VERSION ""

NS_ :

BS_:

BU_: AHLM ASBS CBC DIAGNOST DPDM DTCM ECM EHPS ESC ESL ESM ETM GPF HCP IC IRCM OCM ORC PTS RF_HUB SCCM SGW TBM TCM TPM

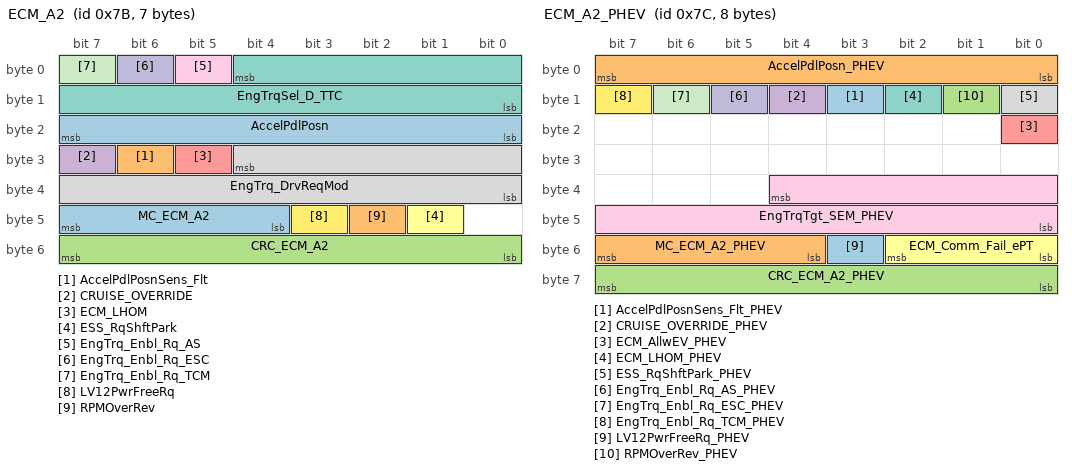
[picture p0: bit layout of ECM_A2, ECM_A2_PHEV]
BO_ 123 ECM_A2: 7 ECM
 SG_ AccelPdlPosn : 16|8@1+ (0.4,0) [0|100] "%"  CBC,DTCM,ESC,ETM,SGW,TBM,TCM
 SG_ AccelPdlPosnSens_Flt : 30|1@1+ (1,0) [0|0] ""  CBC,DTCM,ESC,IRCM,SGW,TCM
 SG_ CRC_ECM_A2 : 48|8@1+ (1,0) [0|0] ""  ESC,IRCM,SGW,TCM
 SG_ CRUISE_OVERRIDE : 31|1@1+ (1,0) [0|0] ""  ESC,IRCM,ORC,SGW,TCM
 SG_ ECM_LHOM : 29|1@1+ (1,0) [0|0] ""  IRCM,SGW,TCM
 SG_ ESS_RqShftPark : 41|1@1+ (1,0) [0|0] ""  ORC,SGW
 SG_ EngTrqSel_D_TTC : 4|13@0+ (0.25,-500) [-500|1547.5] "Nm"  DTCM,ESC,IRCM,ORC,SGW,TCM
 SG_ EngTrq_DrvReqMod : 28|13@0+ (0.25,-500) [-500|1547.5] "Nm"  DTCM,ESC,SGW,TCM
 SG_ EngTrq_Enbl_Rq_AS : 5|1@1+ (1,0) [0|0] ""  ESC,IRCM,SGW
 SG_ EngTrq_Enbl_Rq_ESC : 6|1@1+ (1,0) [0|0] ""  ESC,IRCM,SGW
 SG_ EngTrq_Enbl_Rq_TCM : 7|1@1+ (1,0) [0|0] ""  ORC,SGW,TCM
 SG_ LV12PwrFreeRq : 43|1@1+ (1,0) [0|0] ""  ESC,SGW,TCM
 SG_ MC_ECM_A2 : 44|4@1+ (1,0) [0|15] ""  ESC,IRCM,SGW,TCM
 SG_ RPMOverRev : 42|1@1+ (1,0) [0|0] ""  IRCM,SGW

BO_ 124 ECM_A2_PHEV: 8 ECM
 SG_ AccelPdlPosnSens_Flt_PHEV : 11|1@1+ (1,0) [0|0] ""  CBC,DTCM,ESC,HCP,IRCM,SGW,TCM
 SG_ AccelPdlPosn_PHEV : 0|8@1+ (0.4,0) [0|100] "%"  CBC,DTCM,ESC,IRCM,SGW,TCM
 SG_ CRC_ECM_A2_PHEV : 56|8@1+ (1,0) [0|0] ""  DTCM,ESC,HCP,IRCM,SGW,TCM
 SG_ CRUISE_OVERRIDE_PHEV : 12|1@1+ (1,0) [0|0] ""  ESC,IRCM,ORC,SGW,TCM
 SG_ ECM_AllwEV_PHEV : 16|1@1+ (1,0) [0|0] ""  HCP,SGW
 SG_ ECM_Comm_Fail_ePT : 48|3@1+ (1,0) [0|0] ""  HCP,SGW,TCM
 SG_ ECM_LHOM_PHEV : 10|1@1+ (1,0) [0|0] ""  HCP,IRCM,SGW,TCM
 SG_ ESS_RqShftPark_PHEV : 8|1@1+ (1,0) [0|0] ""  ORC,SGW
 SG_ EngTrqTgt_SEM_PHEV : 36|13@0+ (0.25,-500) [-500|1547.5] "Nm"  HCP,SGW
 SG_ EngTrq_Enbl_Rq_AS_PHEV : 13|1@1+ (1,0) [0|0] ""  ESC,IRCM,SGW
 SG_ EngTrq_Enbl_Rq_ESC_PHEV : 14|1@1+ (1,0) [0|0] ""  ESC,IRCM,SGW
 SG_ EngTrq_Enbl_Rq_TCM_PHEV : 15|1@1+ (1,0) [0|0] ""  HCP,ORC,SGW
 SG_ LV12PwrFreeRq_PHEV : 51|1@1+ (1,0) [0|0] ""  ESC,HCP,SGW
 SG_ MC_ECM_A2_PHEV : 52|4@1+ (1,0) [0|15] ""  DTCM,ESC,HCP,IRCM,SGW,TCM
 SG_ RPMOverRev_PHEV : 9|1@1+ (1,0) [0|0] ""  HCP,IRCM,SGW

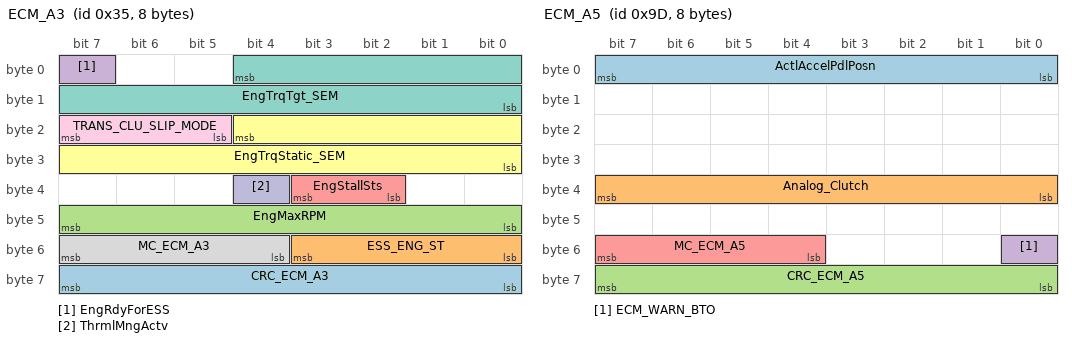
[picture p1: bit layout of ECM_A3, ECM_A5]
BO_ 53 ECM_A3: 8 ECM
 SG_ CRC_ECM_A3 : 56|8@1+ (1,0) [0|0] ""  IRCM,PTS,RF_HUB,SGW,TCM
 SG_ ESS_ENG_ST : 48|4@1+ (1,0) [0|0] ""  CBC,DTCM,EHPS,ESC,ETM,IC,IRCM,ORC,PTS,SGW,TBM,TCM
 SG_ EngMaxRPM : 40|8@1+ (50,0) [0|12700] "rpm"  SGW,TCM
 SG_ EngRdyForESS : 7|1@1+ (1,0) [0|0] ""  SGW,TCM
 SG_ EngStallSts : 34|2@1+ (1,0) [0|0] ""  RF_HUB,SGW
 SG_ EngTrqStatic_SEM : 20|13@0+ (0.25,-500) [-500|1547.5] "Nm"  SGW,TCM
 SG_ EngTrqTgt_SEM : 4|13@0+ (0.25,-500) [-500|1547.5] "Nm"  HCP,SGW,TCM
 SG_ MC_ECM_A3 : 52|4@1+ (1,0) [0|15] ""  EHPS,IRCM,PTS,RF_HUB,SGW,TCM
 SG_ TRANS_CLU_SLIP_MODE : 21|3@1+ (1,0) [0|0] ""  SGW,TCM
 SG_ ThrmlMngActv : 36|1@1+ (1,0) [0|0] ""  IRCM,SGW,TCM

BO_ 976 ECM_A4: 8 ECM
 SG_ KNK_MG_TRIGGER : 29|2@1+ (1,0) [0|0] ""  IC,SGW
 SG_ PF_WARN_MSG : 24|3@1+ (1,0) [0|0] ""  IC,SGW

BO_ 157 ECM_A5: 8 ECM
 SG_ ActlAccelPdlPosn : 0|8@1+ (0.4,0) [0|100] "%"  ESC,ETM,IRCM,ORC,SGW,TBM
 SG_ Analog_Clutch : 32|8@1+ (0.4,0) [0|100] "%"  SGW
 SG_ CRC_ECM_A5 : 56|8@1+ (1,0) [0|0] ""  ESC,IRCM,SGW
 SG_ ECM_WARN_BTO : 48|1@1+ (1,0) [0|0] ""  IC,SGW
 SG_ MC_ECM_A5 : 52|4@1+ (1,0) [0|15] ""  ESC,IRCM,SGW

BO_ 819 ECM_A6: 8 ECM
 SG_ ExhaustSwStat : 56|2@1+ (1,0) [0|0] ""  CBC,IC,SGW

BO_ 864 ECM_APPL1: 8 ECM
 SG_ ECM_APPL1 : 7|64@0+ (1,0) [0|0] ""  DIAGNOST,SGW

BO_ 850 ECM_APPL2: 8 DIAGNOST
 SG_ ECM_APPL2 : 7|64@0+ (1,0) [0|0] ""  ECM

BO_ 880 ECM_APPL3: 8 ECM
 SG_ ECM_APPL3 : 7|64@0+ (1,0) [0|0] ""  DIAGNOST,SGW

BO_ 896 ECM_APPL4: 8 ECM
 SG_ ECM_APPL4 : 7|64@0+ (1,0) [0|0] ""  DIAGNOST,SGW

BO_ 912 ECM_APPL5: 8 ECM
 SG_ ECM_APPL5 : 7|64@0+ (1,0) [0|0] ""  DIAGNOST,SGW

BO_ 928 ECM_APPL6: 8 ECM
 SG_ ECM_APPL6 : 7|64@0+ (1,0) [0|0] ""  DIAGNOST,SGW

BO_ 936 ECM_APPL7: 8 ECM
 SG_ ECM_APPL7 : 7|64@0+ (1,0) [0|0] ""  DIAGNOST,SGW

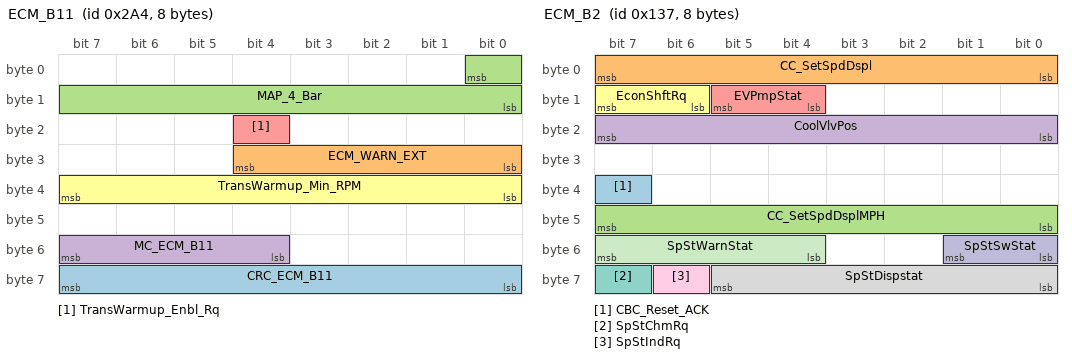
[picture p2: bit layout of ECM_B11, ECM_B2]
BO_ 676 ECM_B11: 8 ECM
 SG_ CRC_ECM_B11 : 56|8@1+ (1,0) [0|0] ""  SGW,TCM
 SG_ ECM_WARN_EXT : 24|5@1+ (1,0) [0|0] ""  ETM,IC,SGW,TBM
 SG_ MAP_4_Bar : 0|9@0+ (0.8,0) [0|408] "kPa"  ETM,ORC,SGW,TBM
 SG_ MC_ECM_B11 : 52|4@1+ (1,0) [0|15] ""  SGW,TCM
 SG_ TransWarmup_Enbl_Rq : 20|1@1+ (1,0) [0|0] ""  SGW,TCM
 SG_ TransWarmup_Min_RPM : 32|8@1+ (25,0) [0|6350] "rpm"  SGW,TCM

BO_ 311 ECM_B2: 8 ECM
 SG_ CBC_Reset_ACK : 39|1@1+ (1,0) [0|0] ""  CBC,SGW
 SG_ CC_SetSpdDspl : 0|8@1+ (1,0) [0|250] "km/h"  ETM,IC,SGW,TBM
 SG_ CC_SetSpdDsplMPH : 40|8@1+ (1,0) [0|254] "mph"  ETM,IC,SGW,TBM
 SG_ CoolVlvPos : 16|8@1+ (0.39374,0) [0.39374|99.61622] "%"  CBC,SGW
 SG_ EVPmpStat : 12|2@1+ (1,0) [0|0] ""  ESC,SGW
 SG_ EconShftRq : 14|2@1+ (1,0) [0|0] ""  IC,SGW
 SG_ SpStChmRq : 63|1@1+ (1,0) [0|0] ""  IC,SGW
 SG_ SpStDispstat : 56|6@1+ (1,0) [0|0] ""  ETM,IC,ORC,SGW,TBM
 SG_ SpStIndRq : 62|1@1+ (1,0) [0|0] ""  IC,SGW
 SG_ SpStSwStat : 48|2@1+ (1,0) [0|0] ""  CBC,ETM,ORC,SGW,TBM
 SG_ SpStWarnStat : 52|4@1+ (1,0) [0|0] ""  ETM,IC,ORC,SGW,TBM

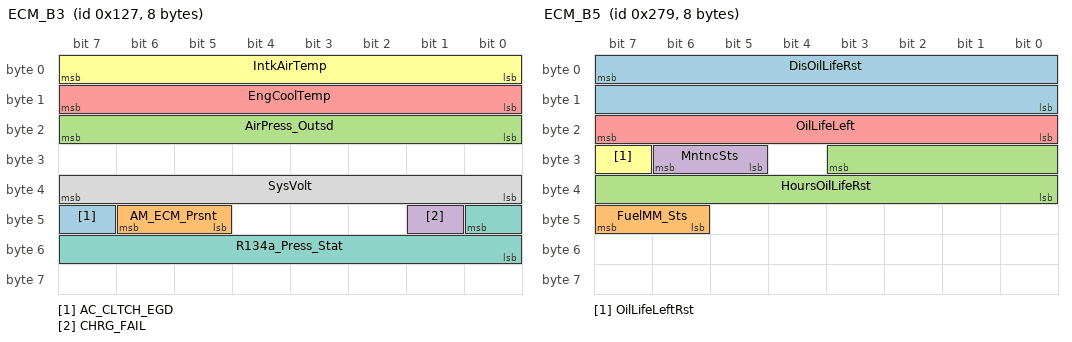
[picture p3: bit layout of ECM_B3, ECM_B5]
BO_ 295 ECM_B3: 8 ECM
 SG_ AC_CLTCH_EGD : 47|1@1+ (1,0) [0|0] ""  CBC,SGW,TCM
 SG_ AM_ECM_Prsnt : 45|2@1+ (1,0) [0|0] ""  CBC,SGW
 SG_ AirPress_Outsd : 16|8@1+ (1,0) [0|254] "kPaA"  ESC,IRCM,SGW,TCM,TPM
 SG_ CHRG_FAIL : 41|1@1+ (1,0) [0|0] ""  ETM,IC,SGW,TBM
 SG_ EngCoolTemp : 8|8@1+ (1,-40) [-40|214] "°C"  CBC,DTCM,ESC,ETM,IC,SGW,TBM,TCM
 SG_ IntkAirTemp : 0|8@1+ (1,-40) [-40|214] "°C"  ECM,SGW,TCM
 SG_ R134a_Press_Stat : 40|9@0+ (0.1,0) [0|40] "bar"  CBC,SGW
 SG_ SysVolt : 32|8@1+ (0.0618,0) [0|15.6972] "Volts"  HCP,SGW

BO_ 633 ECM_B5: 8 ECM
 SG_ DisOilLifeRst : 7|16@0+ (1,0) [0|65534] "km"  CBC,IC,SGW
 SG_ FuelMM_Sts : 46|2@1+ (1,0) [0|0] ""  IC,SGW
 SG_ HoursOilLifeRst : 27|12@0+ (1,0) [0|4000] "Hours"  CBC,SGW
 SG_ MntncSts : 29|2@1+ (1,0) [0|0] ""  ETM,IC,SGW,TBM
 SG_ OilLifeLeft : 16|8@1+ (1,0) [0|100] "%"  ETM,IC,SGW,TBM
 SG_ OilLifeLeftRst : 31|1@1+ (1,0) [0|0] ""  ETM,IC,SGW,TBM

BO_ 323 ECM_B7: 8 ECM
 SG_ DrvAway_Alert : 7|1@1+ (1,0) [0|0] ""  IC,ORC,SGW
 SG_ DrvAway_Inhibit : 15|1@1+ (1,0) [0|0] ""  IC,PTS,SGW

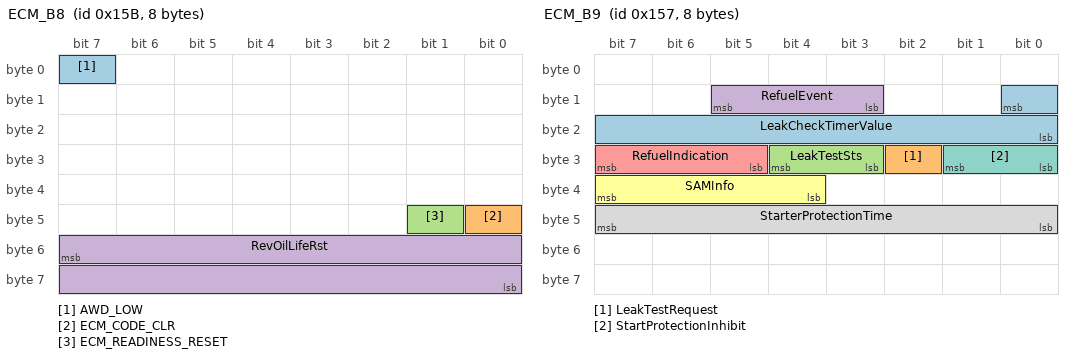
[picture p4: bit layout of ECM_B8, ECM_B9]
BO_ 347 ECM_B8: 8 ECM
 SG_ AWD_LOW : 7|1@1+ (1,0) [0|0] ""  HCP,SGW
 SG_ ECM_CODE_CLR : 40|1@1+ (1,0) [0|0] ""  ESC,HCP,SGW,TCM
 SG_ ECM_READINESS_RESET : 41|1@1+ (1,0) [0|0] ""  ESC,HCP,SGW,TCM
 SG_ RevOilLifeRst : 55|16@0+ (1000,0) [0|65534000] "Rev's"  CBC,SGW

BO_ 343 ECM_B9: 8 ECM
 SG_ LeakCheckTimerValue : 8|9@0+ (1,0) [0|510] "min"  CBC,SGW
 SG_ LeakTestRequest : 26|1@1+ (1,0) [0|0] ""  CBC,SGW
 SG_ LeakTestSts : 27|2@1+ (1,0) [0|0] ""  CBC,ECM,SGW
 SG_ RefuelEvent : 11|3@1+ (1,0) [0|0] ""  CBC,SGW
 SG_ RefuelIndication : 29|3@1+ (1,0) [0|0] ""  IC,SGW
 SG_ SAMInfo : 36|4@1+ (1,0) [0|0] ""  CBC,SGW
 SG_ StartProtectionInhibit : 24|2@1+ (1,0) [0|0] ""  IC,SGW
 SG_ StarterProtectionTime : 40|8@1+ (1,0) [0|254] "sec"  IC,SGW

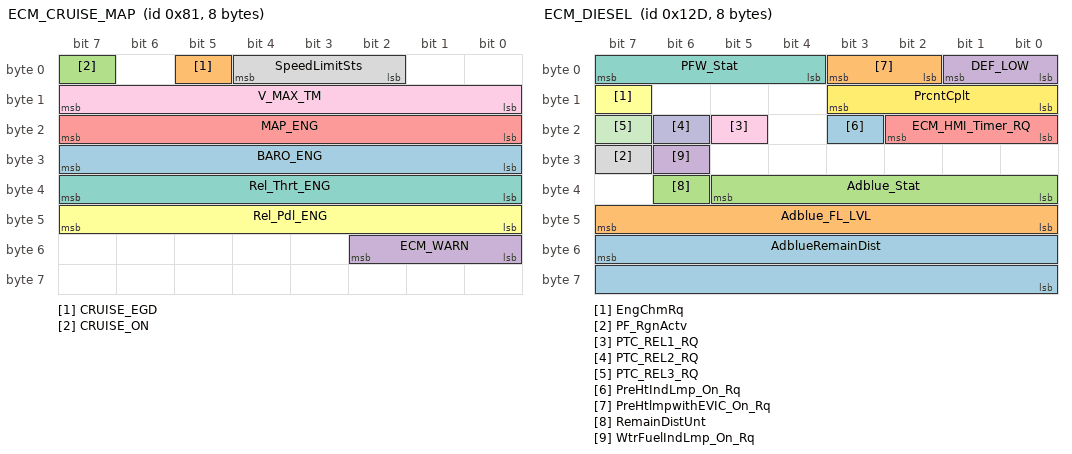
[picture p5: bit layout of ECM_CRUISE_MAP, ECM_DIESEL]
BO_ 129 ECM_CRUISE_MAP: 8 ECM
 SG_ BARO_ENG : 24|8@1+ (1,0) [0|254] "kPaA"  ESC,ETM,SGW,TBM
 SG_ CRUISE_EGD : 5|1@1+ (1,0) [0|0] ""  CBC,ESC,ETM,HCP,IC,ORC,SGW,TBM,TCM
 SG_ CRUISE_ON : 7|1@1+ (1,0) [0|0] ""  CBC,ESC,HCP,IC,ORC,SGW,TCM
 SG_ ECM_WARN : 48|3@1+ (1,0) [0|0] ""  IC,SGW
 SG_ MAP_ENG : 16|8@1+ (0.8,0) [0|203.2] "kPa"  ESC,ETM,SGW,TBM
 SG_ Rel_Pdl_ENG : 40|8@1+ (0.019607843,0) [0|4.98] "Volts"  ESC,ETM,SGW,TBM
 SG_ Rel_Thrt_ENG : 32|8@1+ (0.019607843,0) [0|4.98] "Volts"  ESC,ETM,SGW,TBM
 SG_ SpeedLimitSts : 2|3@1+ (1,0) [0|0] ""  IC,IRCM,ORC,SGW
 SG_ V_MAX_TM : 8|8@1+ (1,0) [0|250] "km/h(mph)"  SGW,TCM

BO_ 301 ECM_DIESEL: 8 ECM
 SG_ AdblueRemainDist : 55|16@0+ (1,0) [0|65534] ""  IC,SGW
 SG_ Adblue_FL_LVL : 40|8@1+ (1,0) [0|100] "%"  ETM,IC,SGW,TBM
 SG_ Adblue_Stat : 32|6@1+ (1,0) [0|0] ""  ETM,IC,SGW,TBM
 SG_ DEF_LOW : 0|2@1+ (1,0) [0|0] ""  ETM,IC,SGW,TBM
 SG_ ECM_HMI_Timer_RQ : 16|3@1+ (1,0) [0|0] ""  IC,SGW
 SG_ EngChmRq : 15|1@1+ (1,0) [0|0] ""  IC,SGW
 SG_ PFW_Stat : 4|4@1+ (1,0) [0|0] ""  ETM,IC,SGW,TBM
 SG_ PF_RgnActv : 31|1@1+ (1,0) [0|0] ""  SGW,TCM
 SG_ PTC_REL1_RQ : 21|1@1+ (1,0) [0|0] ""  CBC,SGW
 SG_ PTC_REL2_RQ : 22|1@1+ (1,0) [0|0] ""  CBC,SGW
 SG_ PTC_REL3_RQ : 23|1@1+ (1,0) [0|0] ""  CBC,SGW
 SG_ PrcntCplt : 8|4@1+ (10,0) [0|100] "%"  ETM,IC,SGW,TBM
 SG_ PreHtIndLmp_On_Rq : 19|1@1+ (1,0) [0|0] ""  CBC,ETM,SGW,TBM
 SG_ PreHtlmpwithEVIC_On_Rq : 2|2@1+ (1,0) [0|0] ""  IC,SGW
 SG_ RemainDistUnt : 38|1@1+ (1,0) [0|0] ""  IC,SGW
 SG_ WtrFuelIndLmp_On_Rq : 30|1@1+ (1,0) [0|0] ""  ETM,IC,SGW,TBM

BO_ 337 ECM_DIESEL2: 8 ECM
 SG_ TrboBstPress : 48|8@1+ (1,0) [0|250] "kPaG"  SGW

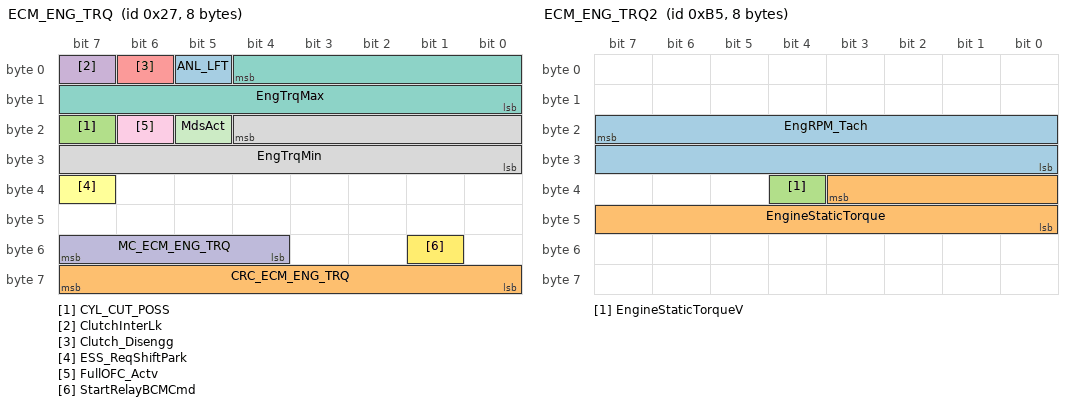
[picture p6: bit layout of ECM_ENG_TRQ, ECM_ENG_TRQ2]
BO_ 39 ECM_ENG_TRQ: 8 ECM
 SG_ ANL_LFT : 5|1@1+ (1,0) [0|0] ""  CBC,SGW
 SG_ CRC_ECM_ENG_TRQ : 56|8@1+ (1,0) [0|0] ""  ESC,IRCM,SGW
 SG_ CYL_CUT_POSS : 23|1@1+ (1,0) [0|0] ""  SGW
 SG_ ClutchInterLk : 7|1@1+ (1,0) [0|0] ""  DTCM,ECM,ESC,ORC,SGW
 SG_ Clutch_Disengg : 6|1@1+ (1,0) [0|0] ""  CBC,ECM,ESC,IRCM,ORC,SGW
 SG_ ESS_ReqShiftPark : 39|1@1+ (1,0) [0|0] ""  SGW,TCM
 SG_ EngTrqMax : 4|13@0+ (0.25,-500) [-500|1547.5] "Nm"  DTCM,ESC,IRCM,SGW,TCM
 SG_ EngTrqMin : 20|13@0+ (0.25,-500) [-500|1547.5] "Nm"  DTCM,ESC,IRCM,SGW
 SG_ FullOFC_Actv : 22|1@1+ (1,0) [0|0] ""  ESC,IRCM,SGW
 SG_ MC_ECM_ENG_TRQ : 52|4@1+ (1,0) [0|15] ""  ESC,IRCM,SGW
 SG_ MdsAct : 21|1@1+ (1,0) [0|0] ""  ETM,SGW,TBM,TCM
 SG_ StartRelayBCMCmd : 49|1@1+ (1,0) [0|0] ""  CBC,SGW

BO_ 181 ECM_ENG_TRQ2: 8 ECM
 SG_ EngRPM_Tach : 23|16@0+ (1,0) [0|65534] "RPM"  IC,SGW
 SG_ EngineStaticTorque : 35|12@0+ (0.32,-300.16) [-300.16|1008] "Nm"  HCP,SGW
 SG_ EngineStaticTorqueV : 36|1@1+ (1,0) [0|0] ""  HCP,SGW

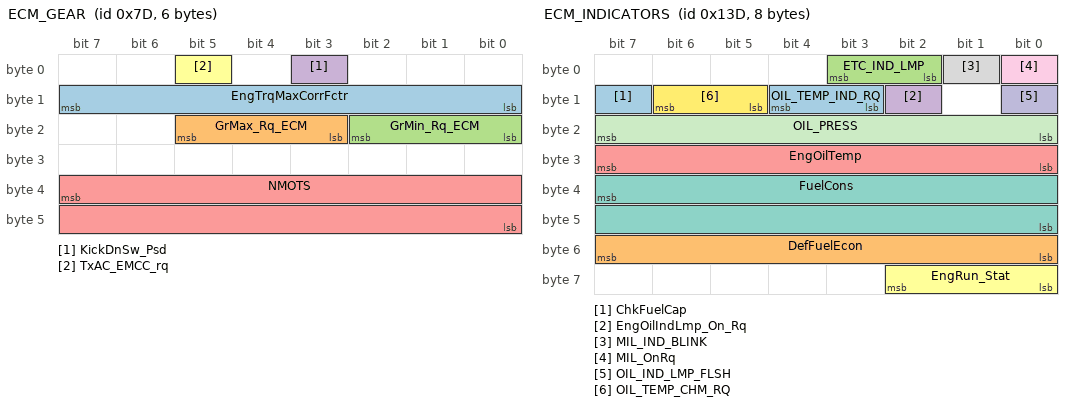
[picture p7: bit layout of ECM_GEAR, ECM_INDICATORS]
BO_ 125 ECM_GEAR: 6 ECM
 SG_ EngTrqMaxCorrFctr : 8|8@1+ (0.0078,0) [0|1.98] "Nm"  SGW,TCM
 SG_ GrMax_Rq_ECM : 19|3@1+ (1,0) [0|0] ""  SGW,TCM
 SG_ GrMin_Rq_ECM : 16|3@1+ (1,0) [0|0] ""  SGW,TCM
 SG_ KickDnSw_Psd : 3|1@1+ (1,0) [0|0] ""  ESC,SGW,TCM
 SG_ NMOTS : 39|16@0+ (1,0) [0|65534] "rpm"  ESC,SGW,TCM
 SG_ TxAC_EMCC_rq : 5|1@1+ (1,0) [0|0] ""  SGW,TCM

BO_ 317 ECM_INDICATORS: 8 ECM
 SG_ ChkFuelCap : 15|1@1+ (1,0) [0|0] ""  ETM,IC,SGW,TBM
 SG_ DefFuelEcon : 48|8@1+ (0.2,0) [0|50] "kmpl"  ETM,IC,SGW,TBM
 SG_ ETC_IND_LMP : 2|2@1+ (1,0) [0|0] ""  CBC,ETM,IC,SGW,TBM
 SG_ EngOilIndLmp_On_Rq : 10|1@1+ (1,0) [0|0] ""  CBC,ETM,IC,SGW,TBM
 SG_ EngOilTemp : 24|8@1+ (1,-40) [-40|160] "°C"  ETM,HCP,IC,SGW,TBM,TCM
 SG_ EngRun_Stat : 56|3@1+ (1,0) [0|0] ""  CBC,DTCM,ESC,HCP,IC,RF_HUB,SGW,TCM
 SG_ FuelCons : 39|16@0+ (0.21668,0) [0|14200] "µl/100ms"  ETM,IC,SGW,TBM
 SG_ MIL_IND_BLINK : 1|1@1+ (1,0) [0|0] ""  CBC,HCP,IC,ORC,SGW
 SG_ MIL_OnRq : 0|1@1+ (1,0) [0|0] ""  CBC,ETM,HCP,IC,ORC,SGW,TBM
 SG_ OIL_IND_LMP_FLSH : 8|1@1+ (1,0) [0|0] ""  ETM,IC,SGW,TBM
 SG_ OIL_PRESS : 16|8@1+ (4,0) [0|1016] "kPaG"  ETM,IC,SGW,TBM
 SG_ OIL_TEMP_CHM_RQ : 13|2@1+ (1,0) [0|0] ""  SGW
 SG_ OIL_TEMP_IND_RQ : 11|2@1+ (1,0) [0|0] ""  ETM,IC,SGW,TBM

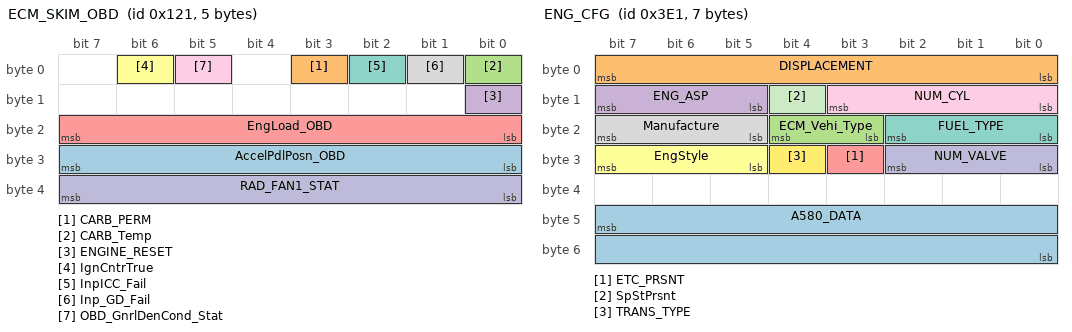
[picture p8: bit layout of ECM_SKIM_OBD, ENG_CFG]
BO_ 289 ECM_SKIM_OBD: 5 ECM
 SG_ AccelPdlPosn_OBD : 24|8@1+ (0.3922,0) [0|100] "%"  ESC,ETM,SGW,TBM,TCM
 SG_ CARB_PERM : 3|1@1+ (1,0) [0|0] ""  SGW,TCM
 SG_ CARB_Temp : 0|1@1+ (1,0) [0|0] ""  SGW,TCM
 SG_ ENGINE_RESET : 8|1@1+ (1,0) [0|0] ""  HCP,SGW
 SG_ EngLoad_OBD : 16|8@1+ (0.3922,0) [0|100] "%"  ESC,ETM,SGW,TBM,TCM
 SG_ IgnCntrTrue : 6|1@1+ (1,0) [0|0] ""  SGW,TCM
 SG_ InpICC_Fail : 2|1@1+ (1,0) [0|0] ""  SGW,TCM
 SG_ Inp_GD_Fail : 1|1@1+ (1,0) [0|0] ""  SGW,TCM
 SG_ OBD_GnrlDenCond_Stat : 5|1@1+ (1,0) [0|0] ""  HCP,SGW,TCM
 SG_ RAD_FAN1_STAT : 32|8@1+ (1,0) [0|100] "%"  ETM,SGW,TBM

BO_ 1449 ECU_APPL_AHLM: 8 AHLM
 SG_ ECU_APPL_AHLM : 7|64@0+ (1,0) [0|0] ""  DIAGNOST,SGW

BO_ 1418 ECU_APPL_ASBS: 8 ASBS
 SG_ ECU_APPL_ASBS : 7|64@0+ (1,0) [0|0] ""  DIAGNOST,SGW

BO_ 1468 ECU_APPL_BSMO: 8 ESC
 SG_ ECU_APPL_BSMO : 7|64@0+ (1,0) [0|0] ""  DIAGNOST,SGW

BO_ 1409 ECU_APPL_CBC: 8 CBC
 SG_ ECU_APPL_CBC : 7|64@0+ (1,0) [0|0] ""  DIAGNOST,SGW

BO_ 1427 ECU_APPL_DASM: 8 IRCM
 SG_ ECU_APPL_DASM : 7|64@0+ (1,0) [0|0] ""  DIAGNOST,SGW

BO_ 1425 ECU_APPL_DPDM: 8 DPDM
 SG_ ECU_APPL_DPDM : 7|64@0+ (1,0) [0|0] ""  DIAGNOST,SGW

BO_ 1419 ECU_APPL_DTCM: 8 DTCM
 SG_ ECU_APPL_DTCM : 7|64@0+ (1,0) [0|0] ""  DIAGNOST,SGW

BO_ 1464 ECU_APPL_ECM: 8 ECM
 SG_ ECU_APPL_ECM : 7|64@0+ (1,0) [0|0] ""  DIAGNOST,SGW

BO_ 1434 ECU_APPL_EPS: 8 EHPS
 SG_ ECU_APPL_EPS : 7|64@0+ (1,0) [0|0] ""  DIAGNOST,SGW

BO_ 1415 ECU_APPL_ESC: 8 ESC
 SG_ ECU_APPL_ESC : 7|64@0+ (1,0) [0|0] ""  DIAGNOST,SGW

BO_ 1416 ECU_APPL_ESL: 8 ESL
 SG_ ECU_APPL_ESL : 7|64@0+ (1,0) [0|0] ""  DIAGNOST,SGW

BO_ 1417 ECU_APPL_ESM: 8 ESM
 SG_ ECU_APPL_ESM : 7|64@0+ (1,0) [0|0] ""  DIAGNOST,SGW

BO_ 1458 ECU_APPL_GPF: 8 GPF
 SG_ ECU_APPL_GPF : 7|64@0+ (1,0) [0|0] ""  DIAGNOST,SGW

BO_ 1466 ECU_APPL_HCP: 8 HCP
 SG_ ECU_APPL_HCP : 7|64@0+ (1,0) [0|0] ""  DIAGNOST,SGW

BO_ 1410 ECU_APPL_IC: 8 IC
 SG_ ECU_APPL_IC : 7|64@0+ (1,0) [0|0] ""  DIAGNOST,SGW

BO_ 1438 ECU_APPL_OCM: 8 OCM
 SG_ ECU_APPL_OCM : 7|64@0+ (1,0) [0|0] ""  DIAGNOST,SGW

BO_ 1412 ECU_APPL_ORC: 8 ORC
 SG_ ECU_APPL_ORC : 7|64@0+ (1,0) [0|0] ""  DIAGNOST,SGW

BO_ 1442 ECU_APPL_PTS: 8 PTS
 SG_ ECU_APPL_PTS : 7|64@0+ (1,0) [0|0] ""  DIAGNOST,SGW

BO_ 1408 ECU_APPL_RF_HUB: 8 RF_HUB
 SG_ ECU_APPL_RF_HUB : 7|64@0+ (1,0) [0|0] ""  DIAGNOST,SGW

BO_ 1443 ECU_APPL_SCCM: 8 SCCM
 SG_ ECU_APPL_SCCM : 7|64@0+ (1,0) [0|0] ""  DIAGNOST,SGW

BO_ 1515 ECU_APPL_TBM: 8 SGW
 SG_ ECU_APPL_TBM : 7|64@0+ (1,0) [0|0] ""  DIAGNOST

BO_ 1465 ECU_APPL_TCM: 8 TCM
 SG_ ECU_APPL_TCM : 7|64@0+ (1,0) [0|0] ""  DIAGNOST,SGW

BO_ 1411 ECU_APPL_TPM: 8 TPM
 SG_ ECU_APPL_TPM : 7|64@0+ (1,0) [0|0] ""  DIAGNOST,SGW

BO_ 993 ENG_CFG: 7 ECM
 SG_ A580_DATA : 47|16@0+ (1,0) [0|0] ""  SGW
 SG_ DISPLACEMENT : 0|8@1+ (0.1,0) [0|25] "liters"  DTCM,ESC,ETM,HCP,IC,IRCM,ORC,SGW,TBM
 SG_ ECM_Vehi_Type : 19|2@1+ (1,0) [0|0] ""  SGW
 SG_ ENG_ASP : 13|3@1+ (1,0) [0|0] ""  ESC,IC,IRCM,SGW
 SG_ ETC_PRSNT : 27|1@1+ (1,0) [0|0] ""  SGW
 SG_ EngStyle : 29|3@1+ (1,0) [0|0] ""  CBC,ESC,SGW
 SG_ FUEL_TYPE : 16|3@1+ (1,0) [0|0] ""  CBC,ESC,ETM,IC,IRCM,SGW,TBM
 SG_ Manufacture : 21|3@1+ (1,0) [0|0] ""  SGW
 SG_ NUM_CYL : 8|4@1+ (1,0) [0|14] "cylinders"  ESC,ETM,IC,IRCM,SGW,TBM
 SG_ NUM_VALVE : 24|3@1+ (1,0) [0|6] "valve-per-cylinder"  IRCM,SGW
 SG_ SpStPrsnt : 12|1@1+ (1,0) [0|0] ""  CBC,EHPS,ESC,IC,IRCM,PTS,SGW
 SG_ TRANS_TYPE : 28|1@1+ (1,0) [0|0] ""  ETM,SGW,TBM

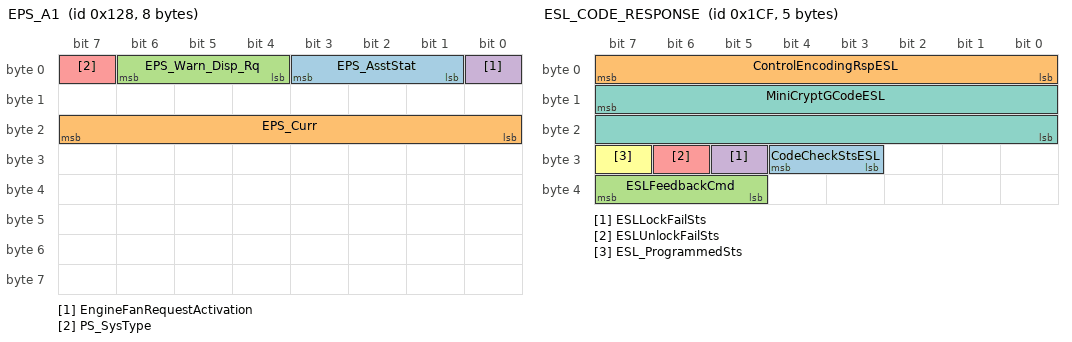
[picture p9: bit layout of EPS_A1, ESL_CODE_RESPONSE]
BO_ 296 EPS_A1: 8 EHPS
 SG_ EPS_AsstStat : 1|3@1+ (1,0) [0|0] ""  ESC,SGW
 SG_ EPS_Curr : 16|8@1+ (1,-50) [-50|204] "Amp"  SGW
 SG_ EPS_Warn_Disp_Rq : 4|3@1+ (1,0) [0|0] ""  ESC,ETM,IC,ORC,SGW,TBM
 SG_ EngineFanRequestActivation : 0|1@1+ (1,0) [0|0] ""  ECM,SGW
 SG_ PS_SysType : 7|1@1+ (1,0) [0|0] ""  CBC,ESC,SGW

BO_ 463 ESL_CODE_RESPONSE: 5 ESL
 SG_ CodeCheckStsESL : 27|2@1+ (1,0) [0|0] ""  CBC,SGW
 SG_ ControlEncodingRspESL : 0|8@1+ (1,0) [0|0] ""  CBC,SGW
 SG_ ESLFeedbackCmd : 37|3@1+ (1,0) [0|0] ""  CBC,SGW
 SG_ ESLLockFailSts : 29|1@1+ (1,0) [0|0] ""  CBC,SGW
 SG_ ESLUnlockFailSts : 30|1@1+ (1,0) [0|0] ""  CBC,SGW
 SG_ ESL_ProgrammedSts : 31|1@1+ (1,0) [0|0] ""  SGW
 SG_ MiniCryptGCodeESL : 15|16@0+ (1,0) [0|0] ""  CBC,SGW

BO_TX_BU_ 850 : DIAGNOST,SGW;
BO_TX_BU_ 1515 : SGW,TBM;
CM_ SG_ 123 AccelPdlPosn "Throttle Pedal Position (Calculated)";
CM_ SG_ 123 AccelPdlPosnSens_Flt "Accelerator pedal position sensor fault";
CM_ SG_ 123 CRC_ECM_A2 "CRC-checksum byte 1 to 6 according to SAE J1850";
CM_ SG_ 123 CRUISE_OVERRIDE "Driver is over-riding cruise set speed";
CM_ SG_ 123 ECM_LHOM "Engine in limp home mode";
CM_ SG_ 123 ESS_RqShftPark "ESS Request shift to Park.  1 = True, 0 = False";
CM_ SG_ 123 EngTrqSel_D_TTC "Corrected (substitute) driver torque demand";
CM_ SG_ 123 EngTrq_DrvReqMod "Driver requested engine torque modifed";
CM_ SG_ 123 EngTrq_Enbl_Rq_AS "Allow LCM torque requests";
CM_ SG_ 123 EngTrq_Enbl_Rq_ESC "Allow ESC torque request";
CM_ SG_ 123 EngTrq_Enbl_Rq_TCM "Allow TRANS torque request";
CM_ SG_ 123 LV12PwrFreeRq "Level 1 or 2 power free request - engine controller has depowered the throttle body";
CM_ SG_ 123 MC_ECM_A2 "Message counter";
CM_ SG_ 123 RPMOverRev "RPM Overrev condition has occurred";
CM_ SG_ 124 AccelPdlPosnSens_Flt_PHEV "Accelerator pedal position sensor fault";
CM_ SG_ 124 AccelPdlPosn_PHEV "Throttle Pedal Position (Calculated)";
CM_ SG_ 124 CRC_ECM_A2_PHEV "CRC-checksum byte 1 to 6 according to SAE J1850";
CM_ SG_ 124 CRUISE_OVERRIDE_PHEV "Driver is over-riding cruise set speed";
CM_ SG_ 124 ECM_AllwEV_PHEV "ECM allow EV mode; 0 EV_not_allowed 1 EV_allowed";
CM_ SG_ 124 ECM_Comm_Fail_ePT "ECM_Comm_Fail_ePT";
CM_ SG_ 124 ECM_LHOM_PHEV "Engine in limp home mode";
CM_ SG_ 124 ESS_RqShftPark_PHEV "ESS Request shift to Park.  1 = True, 0 = False";
CM_ SG_ 124 EngTrqTgt_SEM_PHEV "Final Target torque produced by combustion engine without Shift Intervention torque requests";
CM_ SG_ 124 EngTrq_Enbl_Rq_AS_PHEV "Allow LCM torque requests";
CM_ SG_ 124 EngTrq_Enbl_Rq_ESC_PHEV "Allow ESC torque request";
CM_ SG_ 124 EngTrq_Enbl_Rq_TCM_PHEV "Allow TRANS torque request";
CM_ SG_ 124 LV12PwrFreeRq_PHEV "Level 1 or 2 power free request - engine controller has depowered the throttle body";
CM_ SG_ 124 MC_ECM_A2_PHEV "Message counter";
CM_ SG_ 124 RPMOverRev_PHEV "RPM Overrev condition has occurred";
CM_ SG_ 53 CRC_ECM_A3 "CRC-checksum byte 1 to 7 according to SAE J1850";
CM_ SG_ 53 ESS_ENG_ST "ESS Engine State";
CM_ SG_ 53 EngMaxRPM "Engine maximum RPM";
CM_ SG_ 53 EngRdyForESS "Engine is ready for ESS action (1 = ready)";
CM_ SG_ 53 EngStallSts "Engine stall status message";
CM_ SG_ 53 EngTrqStatic_SEM "Static engine torque - trans trq request";
CM_ SG_ 53 EngTrqTgt_SEM "Target Torque  - trans trq. request";
CM_ SG_ 53 MC_ECM_A3 "Message counter";
CM_ SG_ 53 TRANS_CLU_SLIP_MODE "Clutch Slip Request Mode";
CM_ SG_ 53 ThrmlMngActv "Indicates ECM RPM Limitation Status, Active = 1";
CM_ SG_ 976 KNK_MG_TRIGGER "engine is experiencing high levels of LSPI (mega-knock)";
CM_ SG_ 976 PF_WARN_MSG "Particulate Filter warning message status";
CM_ SG_ 157 ActlAccelPdlPosn "Throttle Pedal Position (actual)";
CM_ SG_ 157 Analog_Clutch "Analog clutch pedal signal";
CM_ SG_ 157 CRC_ECM_A5 "CRC-checksum byte 1 to 7 according to SAE J1850";
CM_ SG_ 157 ECM_WARN_BTO "Status of the BTO failure is transmitted from ECM to cluster, appropriate EVIC message will be displayed by cluster";
CM_ SG_ 157 MC_ECM_A5 "Message counter";
CM_ SG_ 819 ExhaustSwStat "Exhaust switch status for button LED";
CM_ SG_ 864 ECM_APPL1 "Application";
CM_ SG_ 850 ECM_APPL2 "Application";
CM_ SG_ 880 ECM_APPL3 "CCP synchronous - TDC event DAQ";
CM_ SG_ 896 ECM_APPL4 "CCP 5ms DAQ  (from ENGINE to external tool)";
CM_ SG_ 912 ECM_APPL5 "CCP 10ms DAQ  (from ENGINE to external tool)";
CM_ SG_ 928 ECM_APPL6 "CCP 80ms DAQ  (from ENGINE to external tool)";
CM_ SG_ 936 ECM_APPL7 "Application";
CM_ SG_ 676 CRC_ECM_B11 "CRC-Checksum Byte 1 - 7 according to SAE J1850";
CM_ SG_ 676 ECM_WARN_EXT "HMI extended warnings";
CM_ SG_ 676 MAP_4_Bar "Engine manifold pressure (4 bar range)";
CM_ SG_ 676 MC_ECM_B11 "Message counter";
CM_ SG_ 676 TransWarmup_Enbl_Rq "Enable and disable flag for transmission warm up feature, 0h = WarmUp_NOT_Enabled 1h = WarmUp_Enabled";
CM_ SG_ 676 TransWarmup_Min_RPM "Minimal engine rpm request for transmission warm up feature";
CM_ SG_ 311 CBC_Reset_ACK "CBC reset acknowledge; True = [1]";
CM_ SG_ 311 CC_SetSpdDspl "Cruise control set speed for display (kmph only)";
CM_ SG_ 311 CC_SetSpdDsplMPH "Cruise control set speed for display in miles per hour";
CM_ SG_ 311 CoolVlvPos "Coolant (3-way) valve position";
CM_ SG_ 311 EVPmpStat "Electric vacuum pump status";
CM_ SG_ 311 EconShftRq "Economy transmission shift request";
CM_ SG_ 311 SpStChmRq "Stop start chime request";
CM_ SG_ 311 SpStDispstat "Stop start display status";
CM_ SG_ 311 SpStIndRq "Stop start indicator request";
CM_ SG_ 311 SpStSwStat "Stop start switch status";
CM_ SG_ 311 SpStWarnStat "Stop start warning status";
CM_ SG_ 295 AC_CLTCH_EGD "AC clutch engauged";
CM_ SG_ 295 AM_ECM_Prsnt "Aftermarket ECM present";
CM_ SG_ 295 AirPress_Outsd "Ambient air pressure (barometric pressure)";
CM_ SG_ 295 CHRG_FAIL "Charging system Failure (battery indicator request)";
CM_ SG_ 295 EngCoolTemp "Engine coolant temperature";
CM_ SG_ 295 IntkAirTemp "Engine Intake Air Temperature";
CM_ SG_ 295 R134a_Press_Stat "Refrigerant pressure (R134a or R1234YF)";
CM_ SG_ 295 SysVolt "Engine system voltage";
CM_ SG_ 633 DisOilLifeRst "Distance since last oil life reset";
CM_ SG_ 633 FuelMM_Sts "Fuel maintenance mode status";
CM_ SG_ 633 HoursOilLifeRst "Hours since last oil life reset";
CM_ SG_ 633 MntncSts "Maintenance reminder status";
CM_ SG_ 633 OilLifeLeft "Oil life left";
CM_ SG_ 633 OilLifeLeftRst "Oil life remaining has been reset";
CM_ SG_ 323 DrvAway_Alert "Drive Away Alert; True = [1]";
CM_ SG_ 323 DrvAway_Inhibit "Drive Away Inhibit; True = [1]";
CM_ SG_ 347 AWD_LOW "AWD LOW status; 0 4LOW_Not_Active 1 4LOW_Active";
CM_ SG_ 347 ECM_CODE_CLR "Handshake for not to send; 0 = Not cleared 1= Cleared";
CM_ SG_ 347 ECM_READINESS_RESET "Handshake for not to send; 0 Not set 1 set";
CM_ SG_ 347 RevOilLifeRst "Engine revolutions since last oil life reset";
CM_ SG_ 343 LeakCheckTimerValue "Requested leak test timer value";
CM_ SG_ 343 LeakTestRequest "Leak test is requested after powerdown; No request = [0], Leak test requested = [1]";
CM_ SG_ 343 LeakTestSts "Status of leak test";
CM_ SG_ 343 RefuelEvent "Status of refuel event";
CM_ SG_ 343 RefuelIndication "Indication to the driver about the status of the refuel system";
CM_ SG_ 343 SAMInfo "Logic status of the SAM strategy";
CM_ SG_ 343 StartProtectionInhibit "Starter protection status";
CM_ SG_ 343 StarterProtectionTime "Starter protection time";
CM_ SG_ 129 BARO_ENG "Ambient air pressure (barometric pressure)";
CM_ SG_ 129 CRUISE_EGD "Cruise system is controlling speed";
CM_ SG_ 129 CRUISE_ON "Cruise control system 'on'";
CM_ SG_ 129 ECM_WARN "HMI warnings";
CM_ SG_ 129 MAP_ENG "Intake manifold pressure, extended rangeEDR ONLY - Intake manifold pressure";
CM_ SG_ 129 Rel_Pdl_ENG "Relative pedal value";
CM_ SG_ 129 Rel_Thrt_ENG "Relative throttle value";
CM_ SG_ 129 SpeedLimitSts "Speed limiter status";
CM_ SG_ 129 V_MAX_TM "Max. or cruise control set speed";
CM_ SG_ 301 AdblueRemainDist "Adblue remaining distance";
CM_ SG_ 301 Adblue_FL_LVL "Adblue fluid level";
CM_ SG_ 301 Adblue_Stat "Adblue status";
CM_ SG_ 301 DEF_LOW "DEF Low Indicator request";
CM_ SG_ 301 ECM_HMI_Timer_RQ "DEF and DPF warning re-launch timer request";
CM_ SG_ 301 EngChmRq "Engine chime request";
CM_ SG_ 301 PFW_Stat "Particulate filter warning status";
CM_ SG_ 301 PF_RgnActv "Particulate filter regeneration active";
CM_ SG_ 301 PTC_REL1_RQ "Activate PTC Relay # 1";
CM_ SG_ 301 PTC_REL2_RQ "Activate PTC Relay # 2";
CM_ SG_ 301 PTC_REL3_RQ "Activate PTC Relay # 3";
CM_ SG_ 301 PrcntCplt "Percent complete";
CM_ SG_ 301 PreHtIndLmp_On_Rq "Request glow-plug (wait to start) lamp";
CM_ SG_ 301 PreHtlmpwithEVIC_On_Rq "Request Glow Plug Wait to Start Message and Lamp Indicator";
CM_ SG_ 301 RemainDistUnt "Adblue distance counter unit; miles = [0], km = [1]";
CM_ SG_ 301 WtrFuelIndLmp_On_Rq "Request water in fuel lamp (diesel only)";
CM_ SG_ 337 TrboBstPress "Turbo boost pressure";
CM_ SG_ 39 ANL_LFT "Starter motor running (Cranking)";
CM_ SG_ 39 CRC_ECM_ENG_TRQ "CRC-checksum byte 1 to 7 according to SAE J1850";
CM_ SG_ 39 CYL_CUT_POSS "Cylinder cut-out conditions fulfilled";
CM_ SG_ 39 ClutchInterLk "Clutch interlock switch, clutch depressed = [0]";
CM_ SG_ 39 Clutch_Disengg "Clutch upstop position:  Upstop=[0]; partial=[1]";
CM_ SG_ 39 ESS_ReqShiftPark "ESS Request shift to Park.  1 = True, 0 = False";
CM_ SG_ 39 EngTrqMax "Maximum engine torque";
CM_ SG_ 39 EngTrqMin "Minimum engine torque";
CM_ SG_ 39 FullOFC_Actv "Cylinder cut-out";
CM_ SG_ 39 MC_ECM_ENG_TRQ "Message counter";
CM_ SG_ 39 MdsAct "MDS Active";
CM_ SG_ 39 StartRelayBCMCmd "Engine restart request for StopStart function";
CM_ SG_ 181 EngRPM_Tach "Engine revolutions per minute for indication";
CM_ SG_ 181 EngineStaticTorque "Engine Actual Steady State Torque";
CM_ SG_ 181 EngineStaticTorqueV "Engine Actual Steady State Torque Validity";
CM_ SG_ 125 EngTrqMaxCorrFctr "Factor of reduction from max. torque";
CM_ SG_ 125 GrMax_Rq_ECM "Target gear upper limit (ECM requested limit)";
CM_ SG_ 125 GrMin_Rq_ECM "Target gear lower limit (ECM requested limit)";
CM_ SG_ 125 KickDnSw_Psd "kick-down (change-over scenario open!)";
CM_ SG_ 125 NMOTS "Target idle speed";
CM_ SG_ 125 TxAC_EMCC_rq "Transmission  AC converter clutch slip request; [1] = True";
CM_ SG_ 317 ChkFuelCap "Check fuel cap";
CM_ SG_ 317 DefFuelEcon "Default fuel economy";
CM_ SG_ 317 ETC_IND_LMP "ETC faulty, indicator lamp request";
CM_ SG_ 317 EngOilIndLmp_On_Rq "Request oil level/oil pressure indicator lamp";
CM_ SG_ 317 EngOilTemp "Oil temperature";
CM_ SG_ 317 EngRun_Stat "Engine running state";
CM_ SG_ 317 FuelCons "Fuel consumption";
CM_ SG_ 317 MIL_IND_BLINK "Request MIL blink (OBD II)";
CM_ SG_ 317 MIL_OnRq "MIL on request from the engine";
CM_ SG_ 317 OIL_IND_LMP_FLSH "Oil indicator lamp flash (for in plant use)";
CM_ SG_ 317 OIL_PRESS "Oil pressure";
CM_ SG_ 317 OIL_TEMP_CHM_RQ "Engine oil overtemp. chime request";
CM_ SG_ 317 OIL_TEMP_IND_RQ "Engine oil overtemp. indicator request";
CM_ SG_ 289 AccelPdlPosn_OBD "Pedal value for OBD (ISO 15031-5.4 PID 49)";
CM_ SG_ 289 CARB_PERM "CARB permanent fault code drive cycle";
CM_ SG_ 289 CARB_Temp "CARB warmup criteria is true [1]";
CM_ SG_ 289 ENGINE_RESET "ECM Reset Notification";
CM_ SG_ 289 EngLoad_OBD "Load value for OBD (ISO 15031-5.4 PID 4)";
CM_ SG_ 289 IgnCntrTrue "Ignition cycle counter is true [1]";
CM_ SG_ 289 InpICC_Fail "Inputs to the Ign Cycle Cntr are in a Pend or MIL cond.";
CM_ SG_ 289 Inp_GD_Fail "Inputs to the general denominator are in a pend or MIL fault.";
CM_ SG_ 289 OBD_GnrlDenCond_Stat "General denominator conditions are met [1].";
CM_ SG_ 289 RAD_FAN1_STAT "Low speed or single radiator fan requested duty cycle";
CM_ SG_ 1449 ECU_APPL_AHLM "ECU to External Application";
CM_ SG_ 1418 ECU_APPL_ASBS "ECU to External Application";
CM_ SG_ 1468 ECU_APPL_BSMO "ECU to External Application";
CM_ SG_ 1409 ECU_APPL_CBC "ECU to External Application";
CM_ SG_ 1427 ECU_APPL_DASM "ECU to External Application";
CM_ SG_ 1425 ECU_APPL_DPDM "ECU to External Application";
CM_ SG_ 1419 ECU_APPL_DTCM "ECU to External Application";
CM_ SG_ 1464 ECU_APPL_ECM "ECU to External Application";
CM_ SG_ 1434 ECU_APPL_EPS "ECU to External Application";
CM_ SG_ 1415 ECU_APPL_ESC "ECU to External Application";
CM_ SG_ 1416 ECU_APPL_ESL "ECU to External Application";
CM_ SG_ 1417 ECU_APPL_ESM "ECU to External Application";
CM_ SG_ 1458 ECU_APPL_GPF "ECU to External Application";
CM_ SG_ 1466 ECU_APPL_HCP "ECU to External Application";
CM_ SG_ 1410 ECU_APPL_IC "ECU to External Application";
CM_ SG_ 1438 ECU_APPL_OCM "ECU to External Application";
CM_ SG_ 1412 ECU_APPL_ORC "ECU to External Application";
CM_ SG_ 1442 ECU_APPL_PTS "ECU to External Application";
CM_ SG_ 1408 ECU_APPL_RF_HUB "ECU to External Application";
CM_ SG_ 1443 ECU_APPL_SCCM "ECU to External Application";
CM_ SG_ 1515 ECU_APPL_TBM "ECU to External Application";
CM_ SG_ 1465 ECU_APPL_TCM "ECU to External Application";
CM_ SG_ 1411 ECU_APPL_TPM "ECU to External Application";
CM_ SG_ 993 A580_DATA "A580 engine stored data and CRC";
CM_ SG_ 993 DISPLACEMENT "Engine displacement";
CM_ SG_ 993 ECM_Vehi_Type "Engine vehicle type";
CM_ SG_ 993 ENG_ASP "Engine aspiration method";
CM_ SG_ 993 ETC_PRSNT "Electronic throttle control";
CM_ SG_ 993 EngStyle "Engine output version";
CM_ SG_ 993 FUEL_TYPE "Fuel type";
CM_ SG_ 993 Manufacture "Engine manufacture";
CM_ SG_ 993 NUM_CYL "Number of engine cylinders";
CM_ SG_ 993 NUM_VALVE "Number of valves per cylinder";
CM_ SG_ 993 SpStPrsnt "Stop start feature present";
CM_ SG_ 993 TRANS_TYPE "Transmission type; [0] = manual, [1] = automatic";
CM_ SG_ 296 EPS_AsstStat "Electric Power Steering Assistance Status";
CM_ SG_ 296 EPS_Curr "Electric power steering current";
CM_ SG_ 296 EPS_Warn_Disp_Rq "Electric power steering warning display request";
CM_ SG_ 296 EngineFanRequestActivation "Engine fan activation request for cooling; True = [1]";
CM_ SG_ 296 PS_SysType "Power steering system type; EHPS = [0]: EPS = [1]";
CM_ SG_ 463 CodeCheckStsESL "Result of code check";
CM_ SG_ 463 ControlEncodingRspESL "ESL response to BCM MiniCrypt input";
CM_ SG_ 463 ESLFeedbackCmd "ESL status of executing lock/unlock";
CM_ SG_ 463 ESLLockFailSts "Display info on failed lock; Failed = [1]";
CM_ SG_ 463 ESLUnlockFailSts "Display info on failed unlock; Failed = [1]";
CM_ SG_ 463 ESL_ProgrammedSts "ESL programmed with security code; Programmed = [1]";
CM_ SG_ 463 MiniCryptGCodeESL "ESL MiniCrypt code";
BA_DEF_ BO_  "App-Botschaft" ENUM  "nein","ja";
BA_DEF_ BO_  "CanMsgMinLen" INT 0 8;
BA_DEF_ BO_  "DiagRequest" ENUM  "nein","ja";
BA_DEF_ BO_  "DiagResponse" ENUM  "nein","ja";
BA_DEF_ BO_  "DiagState" ENUM  "nein","ja";
BA_DEF_ BO_  "GenMsgCycleTime" INT 0 65535;
BA_DEF_ BO_  "GenMsgCycleTimeActive" INT 0 65535;
BA_DEF_ BO_  "GenMsgDelayTime" INT 0 65535;
BA_DEF_ BO_  "GenMsgNrOfRepetitions" INT 0 65535;
BA_DEF_ BO_  "GenMsgSendType" ENUM  "cyclicX","spontanX","cyclicIfActiveX","spontanWithDelay","cyclicAndSpontanX","cyclicAndSpontanWithDelay","spontanWithRepitition","cyclicIfActiveAndSpontanWD","cyclicIfActiveFast","cyclicWithRepeatOnDemand","none";
BA_DEF_ BO_  "GenMsgStartDelayTime" INT 0 65535;
BA_DEF_ BO_  "GenMsgStartValue" STRING ;
BA_DEF_ BO_  "NWM-Botschaft" ENUM  "nein","ja";
BA_DEF_ BO_  "TpTxIndex" INT 0 99;
BA_DEF_ SG_  "FlexKomComment" STRING ;
BA_DEF_ SG_  "FlexKomIsMotorola" ENUM  "nein","ja";
BA_DEF_ SG_  "FlexKomSID" INT 0 2147483647;
BA_DEF_ SG_  "FlexKomSigLaenge" INT 0 64;
BA_DEF_ SG_  "FlexKomSigName" STRING ;
BA_DEF_ SG_  "FlexKomSigStartPos" INT 0 63;
BA_DEF_ SG_  "FlexKomSigStartValue" STRING ;
BA_DEF_ SG_  "GenSigCycleTime" INT 0 65535;
BA_DEF_ SG_  "GenSigCycleTimeActive" INT 0 65535;
BA_DEF_ SG_  "GenSigSendType" ENUM  "cyclicX","spontanX","cyclicIfActiveX","spontanWithDelay","cyclicAndSpontanX","cyclicAndSpontanWithDelay","spontanWithRepitition","cyclicIfActiveAndSpontanWD","cyclicIfActiveFast","cyclicWithRepeatOnDemand","none";
BA_DEF_ SG_  "GenSigSNA" STRING ;
BA_DEF_ SG_  "GenSigStartValue" HEX 0 2147483648;
BA_DEF_ SG_  "GenSigTimeout_AHLM" INT 0 65535;
BA_DEF_ SG_  "GenSigTimeout_ASBS" INT 0 65535;
BA_DEF_ SG_  "GenSigTimeout_CBC" INT 0 65535;
BA_DEF_ SG_  "GenSigTimeout_DPDM" INT 0 65535;
BA_DEF_ SG_  "GenSigTimeout_DTCM" INT 0 65535;
BA_DEF_ SG_  "GenSigTimeout_EHPS" INT 0 65535;
BA_DEF_ SG_  "GenSigTimeout_ESC" INT 0 65535;
BA_DEF_ SG_  "GenSigTimeout_ESL" INT 0 65535;
BA_DEF_ SG_  "GenSigTimeout_ESM" INT 0 65535;
BA_DEF_ SG_  "GenSigTimeout_ETM" INT 0 65535;
BA_DEF_ SG_  "GenSigTimeout_IC" INT 0 65535;
BA_DEF_ SG_  "GenSigTimeout_OCM" INT 0 65535;
BA_DEF_ SG_  "GenSigTimeout_ORC" INT 0 65535;
BA_DEF_ SG_  "GenSigTimeout_PTS" INT 0 65535;
BA_DEF_ SG_  "GenSigTimeout_RF_HUB" INT 0 65535;
BA_DEF_ SG_  "GenSigTimeout_SCCM" INT 0 65535;
BA_DEF_ SG_  "GenSigTimeout_TBM" INT 0 65535;
BA_DEF_ SG_  "GenSigTimeout_TCM" INT 0 65535;
BA_DEF_ SG_  "GenSigTimeout_TPM" INT 0 65535;
BA_DEF_ SG_  "RID" STRING ;
BA_DEF_ SG_  "SystemSignalLongSymbol" STRING ;
BA_DEF_DEF_  "App-Botschaft" "nein";
BA_DEF_DEF_  "CanMsgMinLen" 0;
BA_DEF_DEF_  "DiagRequest" "nein";
BA_DEF_DEF_  "DiagResponse" "nein";
BA_DEF_DEF_  "DiagState" "nein";
BA_DEF_DEF_  "GenMsgCycleTime" 0;
BA_DEF_DEF_  "GenMsgCycleTimeActive" 0;
BA_DEF_DEF_  "GenMsgDelayTime" 0;
BA_DEF_DEF_  "GenMsgNrOfRepetitions" 0;
BA_DEF_DEF_  "GenMsgSendType" "cyclicX";
BA_DEF_DEF_  "GenMsgStartDelayTime" 0;
BA_DEF_DEF_  "GenMsgStartValue" "";
BA_DEF_DEF_  "NWM-Botschaft" "nein";
BA_DEF_DEF_  "TpTxIndex" 0;
BA_DEF_DEF_  "FlexKomComment" "";
BA_DEF_DEF_  "FlexKomIsMotorola" "nein";
BA_DEF_DEF_  "FlexKomSID" 0;
BA_DEF_DEF_  "FlexKomSigLaenge" 0;
BA_DEF_DEF_  "FlexKomSigName" "";
BA_DEF_DEF_  "FlexKomSigStartPos" 0;
BA_DEF_DEF_  "FlexKomSigStartValue" "";
BA_DEF_DEF_  "GenSigCycleTime" 0;
BA_DEF_DEF_  "GenSigCycleTimeActive" 0;
BA_DEF_DEF_  "GenSigSendType" "cyclicX";
BA_DEF_DEF_  "GenSigSNA" "";
BA_DEF_DEF_  "GenSigStartValue" 0;
BA_DEF_DEF_  "GenSigTimeout_AHLM" 0;
BA_DEF_DEF_  "GenSigTimeout_ASBS" 0;
BA_DEF_DEF_  "GenSigTimeout_CBC" 0;
BA_DEF_DEF_  "GenSigTimeout_DPDM" 0;
BA_DEF_DEF_  "GenSigTimeout_DTCM" 0;
BA_DEF_DEF_  "GenSigTimeout_EHPS" 0;
BA_DEF_DEF_  "GenSigTimeout_ESC" 0;
BA_DEF_DEF_  "GenSigTimeout_ESL" 0;
BA_DEF_DEF_  "GenSigTimeout_ESM" 0;
BA_DEF_DEF_  "GenSigTimeout_ETM" 0;
BA_DEF_DEF_  "GenSigTimeout_IC" 0;
BA_DEF_DEF_  "GenSigTimeout_OCM" 0;
BA_DEF_DEF_  "GenSigTimeout_ORC" 0;
BA_DEF_DEF_  "GenSigTimeout_PTS" 0;
BA_DEF_DEF_  "GenSigTimeout_RF_HUB" 0;
BA_DEF_DEF_  "GenSigTimeout_SCCM" 0;
BA_DEF_DEF_  "GenSigTimeout_TBM" 0;
BA_DEF_DEF_  "GenSigTimeout_TCM" 0;
BA_DEF_DEF_  "GenSigTimeout_TPM" 0;
BA_DEF_DEF_  "RID" "";
BA_DEF_DEF_  "SystemSignalLongSymbol" "";
BA_ "GenMsgStartValue" BO_ 123 "1FFFFF1FFF00FFh";
BA_ "GenMsgNrOfRepetitions" BO_ 123 2;
BA_ "GenMsgDelayTime" BO_ 123 20;
BA_ "GenMsgCycleTime" BO_ 123 20;
BA_ "GenMsgStartValue" BO_ 124 "FF0000001FFF00FFh";
BA_ "GenMsgNrOfRepetitions" BO_ 124 2;
BA_ "GenMsgDelayTime" BO_ 124 20;
BA_ "GenMsgCycleTime" BO_ 124 20;
BA_ "GenMsgStartValue" BO_ 53 "5FFF1FFF00FF0FFFh";
BA_ "GenMsgNrOfRepetitions" BO_ 53 2;
BA_ "GenMsgDelayTime" BO_ 53 20;
BA_ "GenMsgCycleTime" BO_ 53 10;
BA_ "GenMsgStartValue" BO_ 976 "0000000000000000h";
BA_ "GenMsgNrOfRepetitions" BO_ 976 2;
BA_ "GenMsgDelayTime" BO_ 976 20;
BA_ "GenMsgCycleTime" BO_ 976 500;
BA_ "GenMsgStartValue" BO_ 157 "FFFFFFFF00000CFFh";
BA_ "GenMsgNrOfRepetitions" BO_ 157 2;
BA_ "GenMsgDelayTime" BO_ 157 20;
BA_ "GenMsgCycleTime" BO_ 157 20;
BA_ "GenMsgStartValue" BO_ 819 "00000000000000FFh";
BA_ "GenMsgSendType" BO_ 819 5;
BA_ "GenMsgNrOfRepetitions" BO_ 819 2;
BA_ "GenMsgDelayTime" BO_ 819 20;
BA_ "GenMsgCycleTime" BO_ 819 1000;
BA_ "GenMsgStartValue" BO_ 864 "0000000000000000h";
BA_ "GenMsgSendType" BO_ 864 1;
BA_ "GenMsgNrOfRepetitions" BO_ 864 2;
BA_ "GenMsgDelayTime" BO_ 864 20;
BA_ "GenMsgStartValue" BO_ 850 "0000000000000000h";
BA_ "GenMsgSendType" BO_ 850 1;
BA_ "GenMsgNrOfRepetitions" BO_ 850 2;
BA_ "GenMsgDelayTime" BO_ 850 20;
BA_ "GenMsgStartValue" BO_ 880 "0000000000000000h";
BA_ "GenMsgSendType" BO_ 880 1;
BA_ "GenMsgNrOfRepetitions" BO_ 880 2;
BA_ "GenMsgDelayTime" BO_ 880 20;
BA_ "GenMsgStartValue" BO_ 896 "0000000000000000h";
BA_ "GenMsgSendType" BO_ 896 1;
BA_ "GenMsgNrOfRepetitions" BO_ 896 2;
BA_ "GenMsgDelayTime" BO_ 896 20;
BA_ "GenMsgStartValue" BO_ 912 "0000000000000000h";
BA_ "GenMsgSendType" BO_ 912 1;
BA_ "GenMsgNrOfRepetitions" BO_ 912 2;
BA_ "GenMsgDelayTime" BO_ 912 20;
BA_ "GenMsgStartValue" BO_ 928 "0000000000000000h";
BA_ "GenMsgSendType" BO_ 928 1;
BA_ "GenMsgNrOfRepetitions" BO_ 928 2;
BA_ "GenMsgDelayTime" BO_ 928 20;
BA_ "GenMsgStartValue" BO_ 936 "0000000000000000h";
BA_ "GenMsgSendType" BO_ 936 1;
BA_ "GenMsgNrOfRepetitions" BO_ 936 2;
BA_ "GenMsgDelayTime" BO_ 936 20;
BA_ "GenMsgStartValue" BO_ 676 "01FF0700000000FFh";
BA_ "GenMsgNrOfRepetitions" BO_ 676 2;
BA_ "GenMsgDelayTime" BO_ 676 20;
BA_ "GenMsgCycleTime" BO_ 676 100;
BA_ "GenMsgStartValue" BO_ 311 "FF00FFFF00FF0000h";
BA_ "GenMsgNrOfRepetitions" BO_ 311 2;
BA_ "GenMsgDelayTime" BO_ 311 20;
BA_ "GenMsgCycleTime" BO_ 311 100;
BA_ "GenMsgStartValue" BO_ 295 "00FFFF000001FFFFh";
BA_ "GenMsgNrOfRepetitions" BO_ 295 2;
BA_ "GenMsgDelayTime" BO_ 295 20;
BA_ "GenMsgCycleTime" BO_ 295 100;
BA_ "GenMsgStartValue" BO_ 633 "FFFFFF0FFF00FF00h";
BA_ "GenMsgNrOfRepetitions" BO_ 633 2;
BA_ "GenMsgDelayTime" BO_ 633 20;
BA_ "GenMsgCycleTime" BO_ 633 1000;
BA_ "GenMsgStartValue" BO_ 323 "7F0FFF0000000000h";
BA_ "GenMsgNrOfRepetitions" BO_ 323 2;
BA_ "GenMsgDelayTime" BO_ 323 20;
BA_ "GenMsgCycleTime" BO_ 323 100;
BA_ "GenMsgStartValue" BO_ 347 "000000000000FFFFh";
BA_ "GenMsgNrOfRepetitions" BO_ 347 2;
BA_ "GenMsgDelayTime" BO_ 347 20;
BA_ "GenMsgCycleTime" BO_ 347 100;
BA_ "GenMsgStartValue" BO_ 343 "00000000F00000FFh";
BA_ "GenMsgNrOfRepetitions" BO_ 343 2;
BA_ "GenMsgDelayTime" BO_ 343 20;
BA_ "GenMsgCycleTime" BO_ 343 100;
BA_ "GenMsgStartValue" BO_ 129 "08FFFF00FFFF00FFh";
BA_ "GenMsgNrOfRepetitions" BO_ 129 2;
BA_ "GenMsgDelayTime" BO_ 129 20;
BA_ "GenMsgCycleTime" BO_ 129 20;
BA_ "GenMsgStartValue" BO_ 301 "000F000000FF0000h";
BA_ "GenMsgNrOfRepetitions" BO_ 301 2;
BA_ "GenMsgDelayTime" BO_ 301 20;
BA_ "GenMsgCycleTime" BO_ 301 100;
BA_ "GenMsgStartValue" BO_ 337 "FF00000000000000h";
BA_ "GenMsgNrOfRepetitions" BO_ 337 2;
BA_ "GenMsgDelayTime" BO_ 337 20;
BA_ "GenMsgCycleTime" BO_ 337 100;
BA_ "GenMsgStartValue" BO_ 39 "9FFF1FFF1FFF00FFh";
BA_ "GenMsgNrOfRepetitions" BO_ 39 2;
BA_ "GenMsgDelayTime" BO_ 39 20;
BA_ "GenMsgCycleTime" BO_ 39 10;
BA_ "GenMsgStartValue" BO_ 181 "0000FFFF03AA00FFh";
BA_ "GenMsgNrOfRepetitions" BO_ 181 2;
BA_ "GenMsgDelayTime" BO_ 181 20;
BA_ "GenMsgCycleTime" BO_ 181 20;
BA_ "GenMsgStartValue" BO_ 125 "00FF000FFFFFh";
BA_ "GenMsgNrOfRepetitions" BO_ 125 2;
BA_ "GenMsgDelayTime" BO_ 125 20;
BA_ "GenMsgCycleTime" BO_ 125 20;
BA_ "GenMsgStartValue" BO_ 317 "6000FFFFFFFFFF07h";
BA_ "GenMsgNrOfRepetitions" BO_ 317 2;
BA_ "GenMsgDelayTime" BO_ 317 20;
BA_ "GenMsgCycleTime" BO_ 317 100;
BA_ "GenMsgStartValue" BO_ 289 "0000000000h";
BA_ "GenMsgNrOfRepetitions" BO_ 289 2;
BA_ "GenMsgDelayTime" BO_ 289 20;
BA_ "GenMsgCycleTime" BO_ 289 100;
BA_ "GenMsgStartValue" BO_ 1449 "0000000000000000h";
BA_ "GenMsgSendType" BO_ 1449 1;
BA_ "GenMsgNrOfRepetitions" BO_ 1449 2;
BA_ "GenMsgDelayTime" BO_ 1449 20;
BA_ "App-Botschaft" BO_ 1449 1;
BA_ "GenMsgStartValue" BO_ 1418 "0000000000000000h";
BA_ "GenMsgSendType" BO_ 1418 1;
BA_ "GenMsgNrOfRepetitions" BO_ 1418 2;
BA_ "GenMsgDelayTime" BO_ 1418 20;
BA_ "App-Botschaft" BO_ 1418 1;
BA_ "GenMsgStartValue" BO_ 1468 "0000000000000000h";
BA_ "GenMsgSendType" BO_ 1468 1;
BA_ "GenMsgNrOfRepetitions" BO_ 1468 2;
BA_ "GenMsgDelayTime" BO_ 1468 20;
BA_ "App-Botschaft" BO_ 1468 1;
BA_ "GenMsgStartValue" BO_ 1409 "0000000000000000h";
BA_ "GenMsgSendType" BO_ 1409 1;
BA_ "GenMsgNrOfRepetitions" BO_ 1409 2;
BA_ "GenMsgDelayTime" BO_ 1409 20;
BA_ "App-Botschaft" BO_ 1409 1;
BA_ "GenMsgStartValue" BO_ 1427 "0000000000000000h";
BA_ "GenMsgSendType" BO_ 1427 1;
BA_ "GenMsgNrOfRepetitions" BO_ 1427 2;
BA_ "GenMsgDelayTime" BO_ 1427 20;
BA_ "App-Botschaft" BO_ 1427 1;
BA_ "GenMsgStartValue" BO_ 1425 "0000000000000000h";
BA_ "GenMsgSendType" BO_ 1425 1;
BA_ "GenMsgNrOfRepetitions" BO_ 1425 2;
BA_ "GenMsgDelayTime" BO_ 1425 20;
BA_ "App-Botschaft" BO_ 1425 1;
BA_ "GenMsgStartValue" BO_ 1419 "0000000000000000h";
BA_ "GenMsgSendType" BO_ 1419 1;
BA_ "GenMsgNrOfRepetitions" BO_ 1419 2;
BA_ "GenMsgDelayTime" BO_ 1419 20;
BA_ "App-Botschaft" BO_ 1419 1;
BA_ "GenMsgStartValue" BO_ 1464 "0000000000000000h";
BA_ "GenMsgSendType" BO_ 1464 1;
BA_ "GenMsgNrOfRepetitions" BO_ 1464 2;
BA_ "GenMsgDelayTime" BO_ 1464 20;
BA_ "App-Botschaft" BO_ 1464 1;
BA_ "GenMsgStartValue" BO_ 1434 "0000000000000000h";
BA_ "GenMsgSendType" BO_ 1434 1;
BA_ "GenMsgNrOfRepetitions" BO_ 1434 2;
BA_ "GenMsgDelayTime" BO_ 1434 20;
BA_ "App-Botschaft" BO_ 1434 1;
BA_ "GenMsgStartValue" BO_ 1415 "0000000000000000h";
BA_ "GenMsgSendType" BO_ 1415 1;
BA_ "GenMsgNrOfRepetitions" BO_ 1415 2;
BA_ "GenMsgDelayTime" BO_ 1415 20;
BA_ "App-Botschaft" BO_ 1415 1;
BA_ "GenMsgStartValue" BO_ 1416 "0000000000000000h";
BA_ "GenMsgSendType" BO_ 1416 1;
BA_ "GenMsgNrOfRepetitions" BO_ 1416 2;
BA_ "GenMsgDelayTime" BO_ 1416 20;
BA_ "App-Botschaft" BO_ 1416 1;
BA_ "GenMsgStartValue" BO_ 1417 "0000000000000000h";
BA_ "GenMsgSendType" BO_ 1417 1;
BA_ "GenMsgNrOfRepetitions" BO_ 1417 2;
BA_ "GenMsgDelayTime" BO_ 1417 20;
BA_ "App-Botschaft" BO_ 1417 1;
BA_ "GenMsgStartValue" BO_ 1458 "0000000000000000h";
BA_ "GenMsgSendType" BO_ 1458 1;
BA_ "GenMsgNrOfRepetitions" BO_ 1458 2;
BA_ "GenMsgDelayTime" BO_ 1458 20;
BA_ "App-Botschaft" BO_ 1458 1;
BA_ "GenMsgStartValue" BO_ 1466 "0000000000000000h";
BA_ "GenMsgSendType" BO_ 1466 1;
BA_ "GenMsgNrOfRepetitions" BO_ 1466 2;
BA_ "GenMsgDelayTime" BO_ 1466 20;
BA_ "App-Botschaft" BO_ 1466 1;
BA_ "GenMsgStartValue" BO_ 1410 "0000000000000000h";
BA_ "GenMsgSendType" BO_ 1410 1;
BA_ "GenMsgNrOfRepetitions" BO_ 1410 2;
BA_ "GenMsgDelayTime" BO_ 1410 20;
BA_ "App-Botschaft" BO_ 1410 1;
BA_ "GenMsgStartValue" BO_ 1438 "0000000000000000h";
BA_ "GenMsgSendType" BO_ 1438 1;
BA_ "GenMsgNrOfRepetitions" BO_ 1438 2;
BA_ "GenMsgDelayTime" BO_ 1438 20;
BA_ "App-Botschaft" BO_ 1438 1;
BA_ "GenMsgStartValue" BO_ 1412 "0000000000000000h";
BA_ "GenMsgSendType" BO_ 1412 1;
BA_ "GenMsgNrOfRepetitions" BO_ 1412 2;
BA_ "GenMsgDelayTime" BO_ 1412 20;
BA_ "App-Botschaft" BO_ 1412 1;
BA_ "GenMsgStartValue" BO_ 1442 "0000000000000000h";
BA_ "GenMsgSendType" BO_ 1442 1;
BA_ "GenMsgNrOfRepetitions" BO_ 1442 2;
BA_ "GenMsgDelayTime" BO_ 1442 20;
BA_ "App-Botschaft" BO_ 1442 1;
BA_ "GenMsgStartValue" BO_ 1408 "0000000000000000h";
BA_ "GenMsgSendType" BO_ 1408 1;
BA_ "GenMsgNrOfRepetitions" BO_ 1408 2;
BA_ "GenMsgDelayTime" BO_ 1408 20;
BA_ "App-Botschaft" BO_ 1408 1;
BA_ "GenMsgStartValue" BO_ 1443 "0000000000000000h";
BA_ "GenMsgSendType" BO_ 1443 1;
BA_ "GenMsgNrOfRepetitions" BO_ 1443 2;
BA_ "GenMsgDelayTime" BO_ 1443 20;
BA_ "App-Botschaft" BO_ 1443 1;
BA_ "GenMsgStartValue" BO_ 1515 "0000000000000000h";
BA_ "GenMsgSendType" BO_ 1515 1;
BA_ "GenMsgNrOfRepetitions" BO_ 1515 2;
BA_ "GenMsgDelayTime" BO_ 1515 20;
BA_ "App-Botschaft" BO_ 1515 1;
BA_ "GenMsgStartValue" BO_ 1465 "0000000000000000h";
BA_ "GenMsgSendType" BO_ 1465 1;
BA_ "GenMsgNrOfRepetitions" BO_ 1465 2;
BA_ "GenMsgDelayTime" BO_ 1465 20;
BA_ "App-Botschaft" BO_ 1465 1;
BA_ "GenMsgStartValue" BO_ 1411 "0000000000000000h";
BA_ "GenMsgSendType" BO_ 1411 1;
BA_ "GenMsgNrOfRepetitions" BO_ 1411 2;
BA_ "GenMsgDelayTime" BO_ 1411 20;
BA_ "App-Botschaft" BO_ 1411 1;
BA_ "GenMsgStartValue" BO_ 993 "FFEFE7E71F0000h";
BA_ "GenMsgNrOfRepetitions" BO_ 993 2;
BA_ "GenMsgDelayTime" BO_ 993 20;
BA_ "GenMsgCycleTime" BO_ 993 100;
BA_ "GenMsgStartValue" BO_ 296 "0200FF0000000000h";
BA_ "GenMsgNrOfRepetitions" BO_ 296 2;
BA_ "GenMsgDelayTime" BO_ 296 20;
BA_ "GenMsgCycleTime" BO_ 296 100;
BA_ "GenMsgStartValue" BO_ 463 "0000000000h";
BA_ "GenMsgSendType" BO_ 463 1;
BA_ "GenMsgNrOfRepetitions" BO_ 463 2;
BA_ "GenMsgDelayTime" BO_ 463 20;
BA_ "RID" SG_ 123 AccelPdlPosn "5036";
BA_ "GenSigTimeout_TCM" SG_ 123 AccelPdlPosn 210;
BA_ "GenSigTimeout_ETM" SG_ 123 AccelPdlPosn 210;
BA_ "GenSigTimeout_DTCM" SG_ 123 AccelPdlPosn 210;
BA_ "GenSigStartValue" SG_ 123 AccelPdlPosn 255;
BA_ "GenSigSNA" SG_ 123 AccelPdlPosn "FFh";
BA_ "GenSigCycleTime" SG_ 123 AccelPdlPosn 20;
BA_ "FlexKomSigStartValue" SG_ 123 AccelPdlPosn "1FFFFF1FFF00FFh";
BA_ "FlexKomSigStartPos" SG_ 123 AccelPdlPosn 7;
BA_ "FlexKomSigName" SG_ 123 AccelPdlPosn "ECM_A2_PKT";
BA_ "FlexKomSigLaenge" SG_ 123 AccelPdlPosn 56;
BA_ "FlexKomSID" SG_ 123 AccelPdlPosn 455;
BA_ "FlexKomIsMotorola" SG_ 123 AccelPdlPosn 1;
BA_ "FlexKomComment" SG_ 123 AccelPdlPosn "ECM_A2 Packet";
BA_ "RID" SG_ 123 AccelPdlPosnSens_Flt "5031";
BA_ "GenSigTimeout_DTCM" SG_ 123 AccelPdlPosnSens_Flt 210;
BA_ "GenSigSNA" SG_ 123 AccelPdlPosnSens_Flt "0h";
BA_ "GenSigCycleTime" SG_ 123 AccelPdlPosnSens_Flt 20;
BA_ "FlexKomSigStartValue" SG_ 123 AccelPdlPosnSens_Flt "1FFFFF1FFF00FFh";
BA_ "FlexKomSigStartPos" SG_ 123 AccelPdlPosnSens_Flt 7;
BA_ "FlexKomSigName" SG_ 123 AccelPdlPosnSens_Flt "ECM_A2_PKT";
BA_ "FlexKomSigLaenge" SG_ 123 AccelPdlPosnSens_Flt 56;
BA_ "FlexKomSID" SG_ 123 AccelPdlPosnSens_Flt 455;
BA_ "FlexKomIsMotorola" SG_ 123 AccelPdlPosnSens_Flt 1;
BA_ "FlexKomComment" SG_ 123 AccelPdlPosnSens_Flt "ECM_A2 Packet";
BA_ "GenSigStartValue" SG_ 123 CRC_ECM_A2 255;
BA_ "GenSigSNA" SG_ 123 CRC_ECM_A2 "FFh";
BA_ "GenSigCycleTime" SG_ 123 CRC_ECM_A2 20;
BA_ "FlexKomSigStartValue" SG_ 123 CRC_ECM_A2 "1FFFFF1FFF00FFh";
BA_ "FlexKomSigStartPos" SG_ 123 CRC_ECM_A2 7;
BA_ "FlexKomSigName" SG_ 123 CRC_ECM_A2 "ECM_A2_PKT";
BA_ "FlexKomSigLaenge" SG_ 123 CRC_ECM_A2 56;
BA_ "FlexKomSID" SG_ 123 CRC_ECM_A2 455;
BA_ "FlexKomIsMotorola" SG_ 123 CRC_ECM_A2 1;
BA_ "FlexKomComment" SG_ 123 CRC_ECM_A2 "ECM_A2 Packet";
BA_ "GenSigTimeout_TCM" SG_ 123 CRUISE_OVERRIDE 210;
BA_ "GenSigTimeout_IC" SG_ 123 CRUISE_OVERRIDE 210;
BA_ "GenSigSNA" SG_ 123 CRUISE_OVERRIDE "0h";
BA_ "GenSigCycleTime" SG_ 123 CRUISE_OVERRIDE 20;
BA_ "FlexKomSigStartValue" SG_ 123 CRUISE_OVERRIDE "1FFFFF1FFF00FFh";
BA_ "FlexKomSigStartPos" SG_ 123 CRUISE_OVERRIDE 7;
BA_ "FlexKomSigName" SG_ 123 CRUISE_OVERRIDE "ECM_A2_PKT";
BA_ "FlexKomSigLaenge" SG_ 123 CRUISE_OVERRIDE 56;
BA_ "FlexKomSID" SG_ 123 CRUISE_OVERRIDE 455;
BA_ "FlexKomIsMotorola" SG_ 123 CRUISE_OVERRIDE 1;
BA_ "FlexKomComment" SG_ 123 CRUISE_OVERRIDE "ECM_A2 Packet";
BA_ "GenSigTimeout_TCM" SG_ 123 ECM_LHOM 210;
BA_ "GenSigSNA" SG_ 123 ECM_LHOM "0h";
BA_ "GenSigCycleTime" SG_ 123 ECM_LHOM 20;
BA_ "FlexKomSigStartValue" SG_ 123 ECM_LHOM "1FFFFF1FFF00FFh";
BA_ "FlexKomSigStartPos" SG_ 123 ECM_LHOM 7;
BA_ "FlexKomSigName" SG_ 123 ECM_LHOM "ECM_A2_PKT";
BA_ "FlexKomSigLaenge" SG_ 123 ECM_LHOM 56;
BA_ "FlexKomSID" SG_ 123 ECM_LHOM 455;
BA_ "FlexKomIsMotorola" SG_ 123 ECM_LHOM 1;
BA_ "FlexKomComment" SG_ 123 ECM_LHOM "ECM_A2 Packet";
BA_ "GenSigSNA" SG_ 123 ESS_RqShftPark "0h";
BA_ "GenSigCycleTime" SG_ 123 ESS_RqShftPark 20;
BA_ "FlexKomSigStartValue" SG_ 123 ESS_RqShftPark "1FFFFF1FFF00FFh";
BA_ "FlexKomSigStartPos" SG_ 123 ESS_RqShftPark 7;
BA_ "FlexKomSigName" SG_ 123 ESS_RqShftPark "ECM_A2_PKT";
BA_ "FlexKomSigLaenge" SG_ 123 ESS_RqShftPark 56;
BA_ "FlexKomSID" SG_ 123 ESS_RqShftPark 455;
BA_ "FlexKomIsMotorola" SG_ 123 ESS_RqShftPark 1;
BA_ "FlexKomComment" SG_ 123 ESS_RqShftPark "ECM_A2 Packet";
BA_ "GenSigTimeout_TCM" SG_ 123 EngTrqSel_D_TTC 210;
BA_ "GenSigTimeout_DTCM" SG_ 123 EngTrqSel_D_TTC 210;
BA_ "GenSigStartValue" SG_ 123 EngTrqSel_D_TTC 8191;
BA_ "GenSigSNA" SG_ 123 EngTrqSel_D_TTC "1FFFh";
BA_ "GenSigCycleTime" SG_ 123 EngTrqSel_D_TTC 20;
BA_ "FlexKomSigStartValue" SG_ 123 EngTrqSel_D_TTC "1FFFFF1FFF00FFh";
BA_ "FlexKomSigStartPos" SG_ 123 EngTrqSel_D_TTC 7;
BA_ "FlexKomSigName" SG_ 123 EngTrqSel_D_TTC "ECM_A2_PKT";
BA_ "FlexKomSigLaenge" SG_ 123 EngTrqSel_D_TTC 56;
BA_ "FlexKomSID" SG_ 123 EngTrqSel_D_TTC 455;
BA_ "FlexKomIsMotorola" SG_ 123 EngTrqSel_D_TTC 1;
BA_ "FlexKomComment" SG_ 123 EngTrqSel_D_TTC "ECM_A2 Packet";
BA_ "GenSigTimeout_DTCM" SG_ 123 EngTrq_DrvReqMod 210;
BA_ "GenSigStartValue" SG_ 123 EngTrq_DrvReqMod 8191;
BA_ "GenSigSNA" SG_ 123 EngTrq_DrvReqMod "1FFFh";
BA_ "GenSigCycleTime" SG_ 123 EngTrq_DrvReqMod 20;
BA_ "FlexKomSigStartValue" SG_ 123 EngTrq_DrvReqMod "1FFFFF1FFF00FFh";
BA_ "FlexKomSigStartPos" SG_ 123 EngTrq_DrvReqMod 7;
BA_ "FlexKomSigName" SG_ 123 EngTrq_DrvReqMod "ECM_A2_PKT";
BA_ "FlexKomSigLaenge" SG_ 123 EngTrq_DrvReqMod 56;
BA_ "FlexKomSID" SG_ 123 EngTrq_DrvReqMod 455;
BA_ "FlexKomIsMotorola" SG_ 123 EngTrq_DrvReqMod 1;
BA_ "FlexKomComment" SG_ 123 EngTrq_DrvReqMod "ECM_A2 Packet";
BA_ "GenSigSNA" SG_ 123 EngTrq_Enbl_Rq_AS "0h";
BA_ "GenSigCycleTime" SG_ 123 EngTrq_Enbl_Rq_AS 20;
BA_ "FlexKomSigStartValue" SG_ 123 EngTrq_Enbl_Rq_AS "1FFFFF1FFF00FFh";
BA_ "FlexKomSigStartPos" SG_ 123 EngTrq_Enbl_Rq_AS 7;
BA_ "FlexKomSigName" SG_ 123 EngTrq_Enbl_Rq_AS "ECM_A2_PKT";
BA_ "FlexKomSigLaenge" SG_ 123 EngTrq_Enbl_Rq_AS 56;
BA_ "FlexKomSID" SG_ 123 EngTrq_Enbl_Rq_AS 455;
BA_ "FlexKomIsMotorola" SG_ 123 EngTrq_Enbl_Rq_AS 1;
BA_ "FlexKomComment" SG_ 123 EngTrq_Enbl_Rq_AS "ECM_A2 Packet";
BA_ "GenSigSNA" SG_ 123 EngTrq_Enbl_Rq_ESC "0h";
BA_ "GenSigCycleTime" SG_ 123 EngTrq_Enbl_Rq_ESC 20;
BA_ "FlexKomSigStartValue" SG_ 123 EngTrq_Enbl_Rq_ESC "1FFFFF1FFF00FFh";
BA_ "FlexKomSigStartPos" SG_ 123 EngTrq_Enbl_Rq_ESC 7;
BA_ "FlexKomSigName" SG_ 123 EngTrq_Enbl_Rq_ESC "ECM_A2_PKT";
BA_ "FlexKomSigLaenge" SG_ 123 EngTrq_Enbl_Rq_ESC 56;
BA_ "FlexKomSID" SG_ 123 EngTrq_Enbl_Rq_ESC 455;
BA_ "FlexKomIsMotorola" SG_ 123 EngTrq_Enbl_Rq_ESC 1;
BA_ "FlexKomComment" SG_ 123 EngTrq_Enbl_Rq_ESC "ECM_A2 Packet";
BA_ "GenSigTimeout_TCM" SG_ 123 EngTrq_Enbl_Rq_TCM 210;
BA_ "GenSigSNA" SG_ 123 EngTrq_Enbl_Rq_TCM "0h";
BA_ "GenSigCycleTime" SG_ 123 EngTrq_Enbl_Rq_TCM 20;
BA_ "FlexKomSigStartValue" SG_ 123 EngTrq_Enbl_Rq_TCM "1FFFFF1FFF00FFh";
BA_ "FlexKomSigStartPos" SG_ 123 EngTrq_Enbl_Rq_TCM 7;
BA_ "FlexKomSigName" SG_ 123 EngTrq_Enbl_Rq_TCM "ECM_A2_PKT";
BA_ "FlexKomSigLaenge" SG_ 123 EngTrq_Enbl_Rq_TCM 56;
BA_ "FlexKomSID" SG_ 123 EngTrq_Enbl_Rq_TCM 455;
BA_ "FlexKomIsMotorola" SG_ 123 EngTrq_Enbl_Rq_TCM 1;
BA_ "FlexKomComment" SG_ 123 EngTrq_Enbl_Rq_TCM "ECM_A2 Packet";
BA_ "GenSigSNA" SG_ 123 LV12PwrFreeRq "0h";
BA_ "GenSigCycleTime" SG_ 123 LV12PwrFreeRq 20;
BA_ "FlexKomSigStartValue" SG_ 123 LV12PwrFreeRq "1FFFFF1FFF00FFh";
BA_ "FlexKomSigStartPos" SG_ 123 LV12PwrFreeRq 7;
BA_ "FlexKomSigName" SG_ 123 LV12PwrFreeRq "ECM_A2_PKT";
BA_ "FlexKomSigLaenge" SG_ 123 LV12PwrFreeRq 56;
BA_ "FlexKomSID" SG_ 123 LV12PwrFreeRq 455;
BA_ "FlexKomIsMotorola" SG_ 123 LV12PwrFreeRq 1;
BA_ "FlexKomComment" SG_ 123 LV12PwrFreeRq "ECM_A2 Packet";
BA_ "GenSigSNA" SG_ 123 MC_ECM_A2 "0h";
BA_ "GenSigCycleTime" SG_ 123 MC_ECM_A2 20;
BA_ "FlexKomSigStartValue" SG_ 123 MC_ECM_A2 "1FFFFF1FFF00FFh";
BA_ "FlexKomSigStartPos" SG_ 123 MC_ECM_A2 7;
BA_ "FlexKomSigName" SG_ 123 MC_ECM_A2 "ECM_A2_PKT";
BA_ "FlexKomSigLaenge" SG_ 123 MC_ECM_A2 56;
BA_ "FlexKomSID" SG_ 123 MC_ECM_A2 455;
BA_ "FlexKomIsMotorola" SG_ 123 MC_ECM_A2 1;
BA_ "FlexKomComment" SG_ 123 MC_ECM_A2 "ECM_A2 Packet";
BA_ "GenSigSNA" SG_ 123 RPMOverRev "0h";
BA_ "GenSigCycleTime" SG_ 123 RPMOverRev 20;
BA_ "FlexKomSigStartValue" SG_ 123 RPMOverRev "1FFFFF1FFF00FFh";
BA_ "FlexKomSigStartPos" SG_ 123 RPMOverRev 7;
BA_ "FlexKomSigName" SG_ 123 RPMOverRev "ECM_A2_PKT";
BA_ "FlexKomSigLaenge" SG_ 123 RPMOverRev 56;
BA_ "FlexKomSID" SG_ 123 RPMOverRev 455;
BA_ "FlexKomIsMotorola" SG_ 123 RPMOverRev 1;
BA_ "FlexKomComment" SG_ 123 RPMOverRev "ECM_A2 Packet";
BA_ "RID" SG_ 124 AccelPdlPosnSens_Flt_PHEV "6416";
BA_ "GenSigTimeout_DTCM" SG_ 124 AccelPdlPosnSens_Flt_PHEV 210;
BA_ "GenSigSNA" SG_ 124 AccelPdlPosnSens_Flt_PHEV "0h";
BA_ "GenSigCycleTime" SG_ 124 AccelPdlPosnSens_Flt_PHEV 20;
BA_ "FlexKomSigStartValue" SG_ 124 AccelPdlPosnSens_Flt_PHEV "FF0000001FFF00FFh";
BA_ "FlexKomSigStartPos" SG_ 124 AccelPdlPosnSens_Flt_PHEV 7;
BA_ "FlexKomSigName" SG_ 124 AccelPdlPosnSens_Flt_PHEV "ECM_A2_PHEV_PKT";
BA_ "FlexKomSigLaenge" SG_ 124 AccelPdlPosnSens_Flt_PHEV 64;
BA_ "FlexKomSID" SG_ 124 AccelPdlPosnSens_Flt_PHEV 2991;
BA_ "FlexKomIsMotorola" SG_ 124 AccelPdlPosnSens_Flt_PHEV 1;
BA_ "FlexKomComment" SG_ 124 AccelPdlPosnSens_Flt_PHEV "ECM_A2_PHEV_PKT";
BA_ "RID" SG_ 124 AccelPdlPosn_PHEV "6400";
BA_ "GenSigTimeout_TCM" SG_ 124 AccelPdlPosn_PHEV 210;
BA_ "GenSigTimeout_ETM" SG_ 124 AccelPdlPosn_PHEV 210;
BA_ "GenSigTimeout_DTCM" SG_ 124 AccelPdlPosn_PHEV 210;
BA_ "GenSigStartValue" SG_ 124 AccelPdlPosn_PHEV 255;
BA_ "GenSigSNA" SG_ 124 AccelPdlPosn_PHEV "FFh";
BA_ "GenSigCycleTime" SG_ 124 AccelPdlPosn_PHEV 20;
BA_ "FlexKomSigStartValue" SG_ 124 AccelPdlPosn_PHEV "FF0000001FFF00FFh";
BA_ "FlexKomSigStartPos" SG_ 124 AccelPdlPosn_PHEV 7;
BA_ "FlexKomSigName" SG_ 124 AccelPdlPosn_PHEV "ECM_A2_PHEV_PKT";
BA_ "FlexKomSigLaenge" SG_ 124 AccelPdlPosn_PHEV 64;
BA_ "FlexKomSID" SG_ 124 AccelPdlPosn_PHEV 2991;
BA_ "FlexKomIsMotorola" SG_ 124 AccelPdlPosn_PHEV 1;
BA_ "FlexKomComment" SG_ 124 AccelPdlPosn_PHEV "ECM_A2_PHEV_PKT";
BA_ "GenSigStartValue" SG_ 124 CRC_ECM_A2_PHEV 255;
BA_ "GenSigSNA" SG_ 124 CRC_ECM_A2_PHEV "FFh";
BA_ "GenSigCycleTime" SG_ 124 CRC_ECM_A2_PHEV 20;
BA_ "FlexKomSigStartValue" SG_ 124 CRC_ECM_A2_PHEV "FF0000001FFF00FFh";
BA_ "FlexKomSigStartPos" SG_ 124 CRC_ECM_A2_PHEV 7;
BA_ "FlexKomSigName" SG_ 124 CRC_ECM_A2_PHEV "ECM_A2_PHEV_PKT";
BA_ "FlexKomSigLaenge" SG_ 124 CRC_ECM_A2_PHEV 64;
BA_ "FlexKomSID" SG_ 124 CRC_ECM_A2_PHEV 2991;
BA_ "FlexKomIsMotorola" SG_ 124 CRC_ECM_A2_PHEV 1;
BA_ "FlexKomComment" SG_ 124 CRC_ECM_A2_PHEV "ECM_A2_PHEV_PKT";
BA_ "GenSigTimeout_TCM" SG_ 124 CRUISE_OVERRIDE_PHEV 210;
BA_ "GenSigTimeout_IC" SG_ 124 CRUISE_OVERRIDE_PHEV 210;
BA_ "GenSigSNA" SG_ 124 CRUISE_OVERRIDE_PHEV "0h";
BA_ "GenSigCycleTime" SG_ 124 CRUISE_OVERRIDE_PHEV 20;
BA_ "FlexKomSigStartValue" SG_ 124 CRUISE_OVERRIDE_PHEV "FF0000001FFF00FFh";
BA_ "FlexKomSigStartPos" SG_ 124 CRUISE_OVERRIDE_PHEV 7;
BA_ "FlexKomSigName" SG_ 124 CRUISE_OVERRIDE_PHEV "ECM_A2_PHEV_PKT";
BA_ "FlexKomSigLaenge" SG_ 124 CRUISE_OVERRIDE_PHEV 64;
BA_ "FlexKomSID" SG_ 124 CRUISE_OVERRIDE_PHEV 2991;
BA_ "FlexKomIsMotorola" SG_ 124 CRUISE_OVERRIDE_PHEV 1;
BA_ "FlexKomComment" SG_ 124 CRUISE_OVERRIDE_PHEV "ECM_A2_PHEV_PKT";
BA_ "GenSigSNA" SG_ 124 ECM_AllwEV_PHEV "0h";
BA_ "GenSigCycleTime" SG_ 124 ECM_AllwEV_PHEV 20;
BA_ "FlexKomSigStartValue" SG_ 124 ECM_AllwEV_PHEV "FF0000001FFF00FFh";
BA_ "FlexKomSigStartPos" SG_ 124 ECM_AllwEV_PHEV 7;
BA_ "FlexKomSigName" SG_ 124 ECM_AllwEV_PHEV "ECM_A2_PHEV_PKT";
BA_ "FlexKomSigLaenge" SG_ 124 ECM_AllwEV_PHEV 64;
BA_ "FlexKomSID" SG_ 124 ECM_AllwEV_PHEV 2991;
BA_ "FlexKomIsMotorola" SG_ 124 ECM_AllwEV_PHEV 1;
BA_ "FlexKomComment" SG_ 124 ECM_AllwEV_PHEV "ECM_A2_PHEV_PKT";
BA_ "GenSigSNA" SG_ 124 ECM_Comm_Fail_ePT "0h";
BA_ "GenSigCycleTime" SG_ 124 ECM_Comm_Fail_ePT 20;
BA_ "FlexKomSigStartValue" SG_ 124 ECM_Comm_Fail_ePT "FF0000001FFF00FFh";
BA_ "FlexKomSigStartPos" SG_ 124 ECM_Comm_Fail_ePT 7;
BA_ "FlexKomSigName" SG_ 124 ECM_Comm_Fail_ePT "ECM_A2_PHEV_PKT";
BA_ "FlexKomSigLaenge" SG_ 124 ECM_Comm_Fail_ePT 64;
BA_ "FlexKomSID" SG_ 124 ECM_Comm_Fail_ePT 2991;
BA_ "FlexKomIsMotorola" SG_ 124 ECM_Comm_Fail_ePT 1;
BA_ "FlexKomComment" SG_ 124 ECM_Comm_Fail_ePT "ECM_A2_PHEV_PKT";
BA_ "GenSigTimeout_TCM" SG_ 124 ECM_LHOM_PHEV 210;
BA_ "GenSigSNA" SG_ 124 ECM_LHOM_PHEV "0h";
BA_ "GenSigCycleTime" SG_ 124 ECM_LHOM_PHEV 20;
BA_ "FlexKomSigStartValue" SG_ 124 ECM_LHOM_PHEV "FF0000001FFF00FFh";
BA_ "FlexKomSigStartPos" SG_ 124 ECM_LHOM_PHEV 7;
BA_ "FlexKomSigName" SG_ 124 ECM_LHOM_PHEV "ECM_A2_PHEV_PKT";
BA_ "FlexKomSigLaenge" SG_ 124 ECM_LHOM_PHEV 64;
BA_ "FlexKomSID" SG_ 124 ECM_LHOM_PHEV 2991;
BA_ "FlexKomIsMotorola" SG_ 124 ECM_LHOM_PHEV 1;
BA_ "FlexKomComment" SG_ 124 ECM_LHOM_PHEV "ECM_A2_PHEV_PKT";
BA_ "GenSigSNA" SG_ 124 ESS_RqShftPark_PHEV "0h";
BA_ "GenSigCycleTime" SG_ 124 ESS_RqShftPark_PHEV 20;
BA_ "FlexKomSigStartValue" SG_ 124 ESS_RqShftPark_PHEV "FF0000001FFF00FFh";
BA_ "FlexKomSigStartPos" SG_ 124 ESS_RqShftPark_PHEV 7;
BA_ "FlexKomSigName" SG_ 124 ESS_RqShftPark_PHEV "ECM_A2_PHEV_PKT";
BA_ "FlexKomSigLaenge" SG_ 124 ESS_RqShftPark_PHEV 64;
BA_ "FlexKomSID" SG_ 124 ESS_RqShftPark_PHEV 2991;
BA_ "FlexKomIsMotorola" SG_ 124 ESS_RqShftPark_PHEV 1;
BA_ "FlexKomComment" SG_ 124 ESS_RqShftPark_PHEV "ECM_A2_PHEV_PKT";
BA_ "GenSigStartValue" SG_ 124 EngTrqTgt_SEM_PHEV 8191;
BA_ "GenSigSNA" SG_ 124 EngTrqTgt_SEM_PHEV "1FFFh";
BA_ "GenSigCycleTime" SG_ 124 EngTrqTgt_SEM_PHEV 20;
BA_ "FlexKomSigStartValue" SG_ 124 EngTrqTgt_SEM_PHEV "FF0000001FFF00FFh";
BA_ "FlexKomSigStartPos" SG_ 124 EngTrqTgt_SEM_PHEV 7;
BA_ "FlexKomSigName" SG_ 124 EngTrqTgt_SEM_PHEV "ECM_A2_PHEV_PKT";
BA_ "FlexKomSigLaenge" SG_ 124 EngTrqTgt_SEM_PHEV 64;
BA_ "FlexKomSID" SG_ 124 EngTrqTgt_SEM_PHEV 2991;
BA_ "FlexKomIsMotorola" SG_ 124 EngTrqTgt_SEM_PHEV 1;
BA_ "FlexKomComment" SG_ 124 EngTrqTgt_SEM_PHEV "ECM_A2_PHEV_PKT";
BA_ "GenSigSNA" SG_ 124 EngTrq_Enbl_Rq_AS_PHEV "0h";
BA_ "GenSigCycleTime" SG_ 124 EngTrq_Enbl_Rq_AS_PHEV 20;
BA_ "FlexKomSigStartValue" SG_ 124 EngTrq_Enbl_Rq_AS_PHEV "FF0000001FFF00FFh";
BA_ "FlexKomSigStartPos" SG_ 124 EngTrq_Enbl_Rq_AS_PHEV 7;
BA_ "FlexKomSigName" SG_ 124 EngTrq_Enbl_Rq_AS_PHEV "ECM_A2_PHEV_PKT";
BA_ "FlexKomSigLaenge" SG_ 124 EngTrq_Enbl_Rq_AS_PHEV 64;
BA_ "FlexKomSID" SG_ 124 EngTrq_Enbl_Rq_AS_PHEV 2991;
BA_ "FlexKomIsMotorola" SG_ 124 EngTrq_Enbl_Rq_AS_PHEV 1;
BA_ "FlexKomComment" SG_ 124 EngTrq_Enbl_Rq_AS_PHEV "ECM_A2_PHEV_PKT";
BA_ "GenSigSNA" SG_ 124 EngTrq_Enbl_Rq_ESC_PHEV "0h";
BA_ "GenSigCycleTime" SG_ 124 EngTrq_Enbl_Rq_ESC_PHEV 20;
BA_ "FlexKomSigStartValue" SG_ 124 EngTrq_Enbl_Rq_ESC_PHEV "FF0000001FFF00FFh";
BA_ "FlexKomSigStartPos" SG_ 124 EngTrq_Enbl_Rq_ESC_PHEV 7;
BA_ "FlexKomSigName" SG_ 124 EngTrq_Enbl_Rq_ESC_PHEV "ECM_A2_PHEV_PKT";
BA_ "FlexKomSigLaenge" SG_ 124 EngTrq_Enbl_Rq_ESC_PHEV 64;
BA_ "FlexKomSID" SG_ 124 EngTrq_Enbl_Rq_ESC_PHEV 2991;
BA_ "FlexKomIsMotorola" SG_ 124 EngTrq_Enbl_Rq_ESC_PHEV 1;
BA_ "FlexKomComment" SG_ 124 EngTrq_Enbl_Rq_ESC_PHEV "ECM_A2_PHEV_PKT";
BA_ "GenSigTimeout_TCM" SG_ 124 EngTrq_Enbl_Rq_TCM_PHEV 210;
BA_ "GenSigSNA" SG_ 124 EngTrq_Enbl_Rq_TCM_PHEV "0h";
BA_ "GenSigCycleTime" SG_ 124 EngTrq_Enbl_Rq_TCM_PHEV 20;
BA_ "FlexKomSigStartValue" SG_ 124 EngTrq_Enbl_Rq_TCM_PHEV "FF0000001FFF00FFh";
BA_ "FlexKomSigStartPos" SG_ 124 EngTrq_Enbl_Rq_TCM_PHEV 7;
BA_ "FlexKomSigName" SG_ 124 EngTrq_Enbl_Rq_TCM_PHEV "ECM_A2_PHEV_PKT";
BA_ "FlexKomSigLaenge" SG_ 124 EngTrq_Enbl_Rq_TCM_PHEV 64;
BA_ "FlexKomSID" SG_ 124 EngTrq_Enbl_Rq_TCM_PHEV 2991;
BA_ "FlexKomIsMotorola" SG_ 124 EngTrq_Enbl_Rq_TCM_PHEV 1;
BA_ "FlexKomComment" SG_ 124 EngTrq_Enbl_Rq_TCM_PHEV "ECM_A2_PHEV_PKT";
BA_ "GenSigSNA" SG_ 124 LV12PwrFreeRq_PHEV "0h";
BA_ "GenSigCycleTime" SG_ 124 LV12PwrFreeRq_PHEV 20;
BA_ "FlexKomSigStartValue" SG_ 124 LV12PwrFreeRq_PHEV "FF0000001FFF00FFh";
BA_ "FlexKomSigStartPos" SG_ 124 LV12PwrFreeRq_PHEV 7;
BA_ "FlexKomSigName" SG_ 124 LV12PwrFreeRq_PHEV "ECM_A2_PHEV_PKT";
BA_ "FlexKomSigLaenge" SG_ 124 LV12PwrFreeRq_PHEV 64;
BA_ "FlexKomSID" SG_ 124 LV12PwrFreeRq_PHEV 2991;
BA_ "FlexKomIsMotorola" SG_ 124 LV12PwrFreeRq_PHEV 1;
BA_ "FlexKomComment" SG_ 124 LV12PwrFreeRq_PHEV "ECM_A2_PHEV_PKT";
BA_ "GenSigSNA" SG_ 124 MC_ECM_A2_PHEV "0h";
BA_ "GenSigCycleTime" SG_ 124 MC_ECM_A2_PHEV 20;
BA_ "FlexKomSigStartValue" SG_ 124 MC_ECM_A2_PHEV "FF0000001FFF00FFh";
BA_ "FlexKomSigStartPos" SG_ 124 MC_ECM_A2_PHEV 7;
BA_ "FlexKomSigName" SG_ 124 MC_ECM_A2_PHEV "ECM_A2_PHEV_PKT";
BA_ "FlexKomSigLaenge" SG_ 124 MC_ECM_A2_PHEV 64;
BA_ "FlexKomSID" SG_ 124 MC_ECM_A2_PHEV 2991;
BA_ "FlexKomIsMotorola" SG_ 124 MC_ECM_A2_PHEV 1;
BA_ "FlexKomComment" SG_ 124 MC_ECM_A2_PHEV "ECM_A2_PHEV_PKT";
BA_ "GenSigSNA" SG_ 124 RPMOverRev_PHEV "0h";
BA_ "GenSigCycleTime" SG_ 124 RPMOverRev_PHEV 20;
BA_ "FlexKomSigStartValue" SG_ 124 RPMOverRev_PHEV "FF0000001FFF00FFh";
BA_ "FlexKomSigStartPos" SG_ 124 RPMOverRev_PHEV 7;
BA_ "FlexKomSigName" SG_ 124 RPMOverRev_PHEV "ECM_A2_PHEV_PKT";
BA_ "FlexKomSigLaenge" SG_ 124 RPMOverRev_PHEV 64;
BA_ "FlexKomSID" SG_ 124 RPMOverRev_PHEV 2991;
BA_ "FlexKomIsMotorola" SG_ 124 RPMOverRev_PHEV 1;
BA_ "FlexKomComment" SG_ 124 RPMOverRev_PHEV "ECM_A2_PHEV_PKT";
BA_ "GenSigStartValue" SG_ 53 CRC_ECM_A3 255;
BA_ "GenSigSNA" SG_ 53 CRC_ECM_A3 "FFh";
BA_ "GenSigCycleTime" SG_ 53 CRC_ECM_A3 10;
BA_ "FlexKomSigStartValue" SG_ 53 CRC_ECM_A3 "5FFF1FFF00FF0FFFh";
BA_ "FlexKomSigStartPos" SG_ 53 CRC_ECM_A3 7;
BA_ "FlexKomSigName" SG_ 53 CRC_ECM_A3 "ECM_A3_PKT";
BA_ "FlexKomSigLaenge" SG_ 53 CRC_ECM_A3 64;
BA_ "FlexKomSID" SG_ 53 CRC_ECM_A3 1369;
BA_ "FlexKomIsMotorola" SG_ 53 CRC_ECM_A3 1;
BA_ "FlexKomComment" SG_ 53 CRC_ECM_A3 "ECM_A3 message packet";
BA_ "RID" SG_ 53 ESS_ENG_ST "1653";
BA_ "GenSigTimeout_RF_HUB" SG_ 53 ESS_ENG_ST 105;
BA_ "GenSigTimeout_ORC" SG_ 53 ESS_ENG_ST 35;
BA_ "GenSigTimeout_CBC" SG_ 53 ESS_ENG_ST 105;
BA_ "GenSigStartValue" SG_ 53 ESS_ENG_ST 15;
BA_ "GenSigSNA" SG_ 53 ESS_ENG_ST "Fh";
BA_ "GenSigCycleTime" SG_ 53 ESS_ENG_ST 10;
BA_ "FlexKomSigStartValue" SG_ 53 ESS_ENG_ST "5FFF1FFF00FF0FFFh";
BA_ "FlexKomSigStartPos" SG_ 53 ESS_ENG_ST 7;
BA_ "FlexKomSigName" SG_ 53 ESS_ENG_ST "ECM_A3_PKT";
BA_ "FlexKomSigLaenge" SG_ 53 ESS_ENG_ST 64;
BA_ "FlexKomSID" SG_ 53 ESS_ENG_ST 1369;
BA_ "FlexKomIsMotorola" SG_ 53 ESS_ENG_ST 1;
BA_ "FlexKomComment" SG_ 53 ESS_ENG_ST "ECM_A3 message packet";
BA_ "GenSigStartValue" SG_ 53 EngMaxRPM 255;
BA_ "GenSigSNA" SG_ 53 EngMaxRPM "FFh";
BA_ "GenSigCycleTime" SG_ 53 EngMaxRPM 10;
BA_ "FlexKomSigStartValue" SG_ 53 EngMaxRPM "5FFF1FFF00FF0FFFh";
BA_ "FlexKomSigStartPos" SG_ 53 EngMaxRPM 7;
BA_ "FlexKomSigName" SG_ 53 EngMaxRPM "ECM_A3_PKT";
BA_ "FlexKomSigLaenge" SG_ 53 EngMaxRPM 64;
BA_ "FlexKomSID" SG_ 53 EngMaxRPM 1369;
BA_ "FlexKomIsMotorola" SG_ 53 EngMaxRPM 1;
BA_ "FlexKomComment" SG_ 53 EngMaxRPM "ECM_A3 message packet";
BA_ "GenSigSNA" SG_ 53 EngRdyForESS "0h";
BA_ "GenSigCycleTime" SG_ 53 EngRdyForESS 10;
BA_ "FlexKomSigStartValue" SG_ 53 EngRdyForESS "5FFF1FFF00FF0FFFh";
BA_ "FlexKomSigStartPos" SG_ 53 EngRdyForESS 7;
BA_ "FlexKomSigName" SG_ 53 EngRdyForESS "ECM_A3_PKT";
BA_ "FlexKomSigLaenge" SG_ 53 EngRdyForESS 64;
BA_ "FlexKomSID" SG_ 53 EngRdyForESS 1369;
BA_ "FlexKomIsMotorola" SG_ 53 EngRdyForESS 1;
BA_ "FlexKomComment" SG_ 53 EngRdyForESS "ECM_A3 message packet";
BA_ "GenSigSNA" SG_ 53 EngStallSts "3h";
BA_ "GenSigCycleTime" SG_ 53 EngStallSts 10;
BA_ "FlexKomSigStartValue" SG_ 53 EngStallSts "5FFF1FFF00FF0FFFh";
BA_ "FlexKomSigStartPos" SG_ 53 EngStallSts 7;
BA_ "FlexKomSigName" SG_ 53 EngStallSts "ECM_A3_PKT";
BA_ "FlexKomSigLaenge" SG_ 53 EngStallSts 64;
BA_ "FlexKomSID" SG_ 53 EngStallSts 1369;
BA_ "FlexKomIsMotorola" SG_ 53 EngStallSts 1;
BA_ "FlexKomComment" SG_ 53 EngStallSts "ECM_A3 message packet";
BA_ "GenSigStartValue" SG_ 53 EngTrqStatic_SEM 8191;
BA_ "GenSigSNA" SG_ 53 EngTrqStatic_SEM "1FFFh";
BA_ "GenSigCycleTime" SG_ 53 EngTrqStatic_SEM 10;
BA_ "FlexKomSigStartValue" SG_ 53 EngTrqStatic_SEM "5FFF1FFF00FF0FFFh";
BA_ "FlexKomSigStartPos" SG_ 53 EngTrqStatic_SEM 7;
BA_ "FlexKomSigName" SG_ 53 EngTrqStatic_SEM "ECM_A3_PKT";
BA_ "FlexKomSigLaenge" SG_ 53 EngTrqStatic_SEM 64;
BA_ "FlexKomSID" SG_ 53 EngTrqStatic_SEM 1369;
BA_ "FlexKomIsMotorola" SG_ 53 EngTrqStatic_SEM 1;
BA_ "FlexKomComment" SG_ 53 EngTrqStatic_SEM "ECM_A3 message packet";
BA_ "GenSigStartValue" SG_ 53 EngTrqTgt_SEM 8191;
BA_ "GenSigSNA" SG_ 53 EngTrqTgt_SEM "1FFFh";
BA_ "GenSigCycleTime" SG_ 53 EngTrqTgt_SEM 10;
BA_ "FlexKomSigStartValue" SG_ 53 EngTrqTgt_SEM "5FFF1FFF00FF0FFFh";
BA_ "FlexKomSigStartPos" SG_ 53 EngTrqTgt_SEM 7;
BA_ "FlexKomSigName" SG_ 53 EngTrqTgt_SEM "ECM_A3_PKT";
BA_ "FlexKomSigLaenge" SG_ 53 EngTrqTgt_SEM 64;
BA_ "FlexKomSID" SG_ 53 EngTrqTgt_SEM 1369;
BA_ "FlexKomIsMotorola" SG_ 53 EngTrqTgt_SEM 1;
BA_ "FlexKomComment" SG_ 53 EngTrqTgt_SEM "ECM_A3 message packet";
BA_ "GenSigSNA" SG_ 53 MC_ECM_A3 "0h";
BA_ "GenSigCycleTime" SG_ 53 MC_ECM_A3 10;
BA_ "FlexKomSigStartValue" SG_ 53 MC_ECM_A3 "5FFF1FFF00FF0FFFh";
BA_ "FlexKomSigStartPos" SG_ 53 MC_ECM_A3 7;
BA_ "FlexKomSigName" SG_ 53 MC_ECM_A3 "ECM_A3_PKT";
BA_ "FlexKomSigLaenge" SG_ 53 MC_ECM_A3 64;
BA_ "FlexKomSID" SG_ 53 MC_ECM_A3 1369;
BA_ "FlexKomIsMotorola" SG_ 53 MC_ECM_A3 1;
BA_ "FlexKomComment" SG_ 53 MC_ECM_A3 "ECM_A3 message packet";
BA_ "RID" SG_ 53 TRANS_CLU_SLIP_MODE "2105";
BA_ "GenSigTimeout_CBC" SG_ 53 TRANS_CLU_SLIP_MODE 105;
BA_ "GenSigSNA" SG_ 53 TRANS_CLU_SLIP_MODE "7h";
BA_ "GenSigCycleTime" SG_ 53 TRANS_CLU_SLIP_MODE 10;
BA_ "FlexKomSigStartValue" SG_ 53 TRANS_CLU_SLIP_MODE "5FFF1FFF00FF0FFFh";
BA_ "FlexKomSigStartPos" SG_ 53 TRANS_CLU_SLIP_MODE 7;
BA_ "FlexKomSigName" SG_ 53 TRANS_CLU_SLIP_MODE "ECM_A3_PKT";
BA_ "FlexKomSigLaenge" SG_ 53 TRANS_CLU_SLIP_MODE 64;
BA_ "FlexKomSID" SG_ 53 TRANS_CLU_SLIP_MODE 1369;
BA_ "FlexKomIsMotorola" SG_ 53 TRANS_CLU_SLIP_MODE 1;
BA_ "FlexKomComment" SG_ 53 TRANS_CLU_SLIP_MODE "ECM_A3 message packet";
BA_ "GenSigSNA" SG_ 53 ThrmlMngActv "0h";
BA_ "GenSigCycleTime" SG_ 53 ThrmlMngActv 10;
BA_ "FlexKomSigStartValue" SG_ 53 ThrmlMngActv "5FFF1FFF00FF0FFFh";
BA_ "FlexKomSigStartPos" SG_ 53 ThrmlMngActv 7;
BA_ "FlexKomSigName" SG_ 53 ThrmlMngActv "ECM_A3_PKT";
BA_ "FlexKomSigLaenge" SG_ 53 ThrmlMngActv 64;
BA_ "FlexKomSID" SG_ 53 ThrmlMngActv 1369;
BA_ "FlexKomIsMotorola" SG_ 53 ThrmlMngActv 1;
BA_ "FlexKomComment" SG_ 53 ThrmlMngActv "ECM_A3 message packet";
BA_ "GenSigTimeout_IC" SG_ 976 KNK_MG_TRIGGER 5250;
BA_ "GenSigSNA" SG_ 976 KNK_MG_TRIGGER "0h";
BA_ "GenSigCycleTime" SG_ 976 KNK_MG_TRIGGER 500;
BA_ "FlexKomSigStartValue" SG_ 976 KNK_MG_TRIGGER "0000000000000000h";
BA_ "FlexKomSigStartPos" SG_ 976 KNK_MG_TRIGGER 7;
BA_ "FlexKomSigName" SG_ 976 KNK_MG_TRIGGER "ECM_A4_Pkt";
BA_ "FlexKomSigLaenge" SG_ 976 KNK_MG_TRIGGER 64;
BA_ "FlexKomSID" SG_ 976 KNK_MG_TRIGGER 2627;
BA_ "FlexKomIsMotorola" SG_ 976 KNK_MG_TRIGGER 1;
BA_ "FlexKomComment" SG_ 976 KNK_MG_TRIGGER "ECM_A4 Packet";
BA_ "GenSigTimeout_IC" SG_ 976 PF_WARN_MSG 5250;
BA_ "GenSigSNA" SG_ 976 PF_WARN_MSG "0h";
BA_ "GenSigCycleTime" SG_ 976 PF_WARN_MSG 500;
BA_ "FlexKomSigStartValue" SG_ 976 PF_WARN_MSG "0000000000000000h";
BA_ "FlexKomSigStartPos" SG_ 976 PF_WARN_MSG 7;
BA_ "FlexKomSigName" SG_ 976 PF_WARN_MSG "ECM_A4_Pkt";
BA_ "FlexKomSigLaenge" SG_ 976 PF_WARN_MSG 64;
BA_ "FlexKomSID" SG_ 976 PF_WARN_MSG 2627;
BA_ "FlexKomIsMotorola" SG_ 976 PF_WARN_MSG 1;
BA_ "FlexKomComment" SG_ 976 PF_WARN_MSG "ECM_A4 Packet";
BA_ "RID" SG_ 157 ActlAccelPdlPosn "5035";
BA_ "GenSigTimeout_CBC" SG_ 157 ActlAccelPdlPosn 210;
BA_ "GenSigStartValue" SG_ 157 ActlAccelPdlPosn 255;
BA_ "GenSigSNA" SG_ 157 ActlAccelPdlPosn "FFh";
BA_ "GenSigCycleTime" SG_ 157 ActlAccelPdlPosn 20;
BA_ "FlexKomSigStartValue" SG_ 157 ActlAccelPdlPosn "FFFFFFFF00000CFFh";
BA_ "FlexKomSigStartPos" SG_ 157 ActlAccelPdlPosn 7;
BA_ "FlexKomSigName" SG_ 157 ActlAccelPdlPosn "ECM_A5_PKT";
BA_ "FlexKomSigLaenge" SG_ 157 ActlAccelPdlPosn 64;
BA_ "FlexKomSID" SG_ 157 ActlAccelPdlPosn 1821;
BA_ "FlexKomIsMotorola" SG_ 157 ActlAccelPdlPosn 1;
BA_ "FlexKomComment" SG_ 157 ActlAccelPdlPosn "ECM_A5 Packet";
BA_ "GenSigSNA" SG_ 157 Analog_Clutch "FFh";
BA_ "GenSigCycleTime" SG_ 157 Analog_Clutch 20;
BA_ "FlexKomSigStartValue" SG_ 157 Analog_Clutch "FFFFFFFF00000CFFh";
BA_ "FlexKomSigStartPos" SG_ 157 Analog_Clutch 7;
BA_ "FlexKomSigName" SG_ 157 Analog_Clutch "ECM_A5_PKT";
BA_ "FlexKomSigLaenge" SG_ 157 Analog_Clutch 64;
BA_ "FlexKomSID" SG_ 157 Analog_Clutch 1821;
BA_ "FlexKomIsMotorola" SG_ 157 Analog_Clutch 1;
BA_ "FlexKomComment" SG_ 157 Analog_Clutch "ECM_A5 Packet";
BA_ "GenSigStartValue" SG_ 157 CRC_ECM_A5 255;
BA_ "GenSigSNA" SG_ 157 CRC_ECM_A5 "FFh";
BA_ "GenSigCycleTime" SG_ 157 CRC_ECM_A5 20;
BA_ "FlexKomSigStartValue" SG_ 157 CRC_ECM_A5 "FFFFFFFF00000CFFh";
BA_ "FlexKomSigStartPos" SG_ 157 CRC_ECM_A5 7;
BA_ "FlexKomSigName" SG_ 157 CRC_ECM_A5 "ECM_A5_PKT";
BA_ "FlexKomSigLaenge" SG_ 157 CRC_ECM_A5 64;
BA_ "FlexKomSID" SG_ 157 CRC_ECM_A5 1821;
BA_ "FlexKomIsMotorola" SG_ 157 CRC_ECM_A5 1;
BA_ "FlexKomComment" SG_ 157 CRC_ECM_A5 "ECM_A5 Packet";
BA_ "GenSigTimeout_IC" SG_ 157 ECM_WARN_BTO 210;
BA_ "GenSigSNA" SG_ 157 ECM_WARN_BTO "0h";
BA_ "GenSigCycleTime" SG_ 157 ECM_WARN_BTO 20;
BA_ "FlexKomSigStartValue" SG_ 157 ECM_WARN_BTO "FFFFFFFF00000CFFh";
BA_ "FlexKomSigStartPos" SG_ 157 ECM_WARN_BTO 7;
BA_ "FlexKomSigName" SG_ 157 ECM_WARN_BTO "ECM_A5_PKT";
BA_ "FlexKomSigLaenge" SG_ 157 ECM_WARN_BTO 64;
BA_ "FlexKomSID" SG_ 157 ECM_WARN_BTO 1821;
BA_ "FlexKomIsMotorola" SG_ 157 ECM_WARN_BTO 1;
BA_ "FlexKomComment" SG_ 157 ECM_WARN_BTO "ECM_A5 Packet";
BA_ "GenSigSNA" SG_ 157 MC_ECM_A5 "0h";
BA_ "GenSigCycleTime" SG_ 157 MC_ECM_A5 20;
BA_ "FlexKomSigStartValue" SG_ 157 MC_ECM_A5 "FFFFFFFF00000CFFh";
BA_ "FlexKomSigStartPos" SG_ 157 MC_ECM_A5 7;
BA_ "FlexKomSigName" SG_ 157 MC_ECM_A5 "ECM_A5_PKT";
BA_ "FlexKomSigLaenge" SG_ 157 MC_ECM_A5 64;
BA_ "FlexKomSID" SG_ 157 MC_ECM_A5 1821;
BA_ "FlexKomIsMotorola" SG_ 157 MC_ECM_A5 1;
BA_ "FlexKomComment" SG_ 157 MC_ECM_A5 "ECM_A5 Packet";
BA_ "GenSigSNA" SG_ 819 ExhaustSwStat "3h";
BA_ "GenSigSendType" SG_ 819 ExhaustSwStat 5;
BA_ "GenSigCycleTime" SG_ 819 ExhaustSwStat 1000;
BA_ "FlexKomSigStartValue" SG_ 819 ExhaustSwStat "00000000000000FFh";
BA_ "FlexKomSigStartPos" SG_ 819 ExhaustSwStat 7;
BA_ "FlexKomSigName" SG_ 819 ExhaustSwStat "ECM_A6_PKT1";
BA_ "FlexKomSigLaenge" SG_ 819 ExhaustSwStat 64;
BA_ "FlexKomSID" SG_ 819 ExhaustSwStat 3093;
BA_ "FlexKomIsMotorola" SG_ 819 ExhaustSwStat 1;
BA_ "FlexKomComment" SG_ 819 ExhaustSwStat "ECM_A6 Packet";
BA_ "GenSigSNA" SG_ 864 ECM_APPL1 "0h";
BA_ "GenSigSendType" SG_ 864 ECM_APPL1 1;
BA_ "FlexKomSigStartValue" SG_ 864 ECM_APPL1 "0000000000000000h";
BA_ "FlexKomSigStartPos" SG_ 864 ECM_APPL1 7;
BA_ "FlexKomSigName" SG_ 864 ECM_APPL1 "ECM_APPL1";
BA_ "FlexKomSigLaenge" SG_ 864 ECM_APPL1 64;
BA_ "FlexKomSID" SG_ 864 ECM_APPL1 780;
BA_ "FlexKomIsMotorola" SG_ 864 ECM_APPL1 1;
BA_ "FlexKomComment" SG_ 864 ECM_APPL1 "Application";
BA_ "GenSigSNA" SG_ 850 ECM_APPL2 "0h";
BA_ "GenSigSendType" SG_ 850 ECM_APPL2 1;
BA_ "FlexKomSigStartValue" SG_ 850 ECM_APPL2 "0000000000000000h";
BA_ "FlexKomSigStartPos" SG_ 850 ECM_APPL2 7;
BA_ "FlexKomSigName" SG_ 850 ECM_APPL2 "ECM_APPL2";
BA_ "FlexKomSigLaenge" SG_ 850 ECM_APPL2 64;
BA_ "FlexKomSID" SG_ 850 ECM_APPL2 1110;
BA_ "FlexKomIsMotorola" SG_ 850 ECM_APPL2 1;
BA_ "FlexKomComment" SG_ 850 ECM_APPL2 "Application";
BA_ "GenSigSNA" SG_ 880 ECM_APPL3 "0h";
BA_ "GenSigSendType" SG_ 880 ECM_APPL3 1;
BA_ "FlexKomSigStartValue" SG_ 880 ECM_APPL3 "0000000000000000h";
BA_ "FlexKomSigStartPos" SG_ 880 ECM_APPL3 7;
BA_ "FlexKomSigName" SG_ 880 ECM_APPL3 "ECM_APPL3";
BA_ "FlexKomSigLaenge" SG_ 880 ECM_APPL3 64;
BA_ "FlexKomSID" SG_ 880 ECM_APPL3 781;
BA_ "FlexKomIsMotorola" SG_ 880 ECM_APPL3 1;
BA_ "FlexKomComment" SG_ 880 ECM_APPL3 "CCP synchronous - TDC event DAQ";
BA_ "GenSigSNA" SG_ 896 ECM_APPL4 "0h";
BA_ "GenSigSendType" SG_ 896 ECM_APPL4 1;
BA_ "FlexKomSigStartValue" SG_ 896 ECM_APPL4 "0000000000000000h";
BA_ "FlexKomSigStartPos" SG_ 896 ECM_APPL4 7;
BA_ "FlexKomSigName" SG_ 896 ECM_APPL4 "ECM_APPL4";
BA_ "FlexKomSigLaenge" SG_ 896 ECM_APPL4 64;
BA_ "FlexKomSID" SG_ 896 ECM_APPL4 782;
BA_ "FlexKomIsMotorola" SG_ 896 ECM_APPL4 1;
BA_ "FlexKomComment" SG_ 896 ECM_APPL4 "CCP 5ms DAQ  (from ENGINE to external tool)";
BA_ "GenSigSNA" SG_ 912 ECM_APPL5 "0h";
BA_ "GenSigSendType" SG_ 912 ECM_APPL5 1;
BA_ "FlexKomSigStartValue" SG_ 912 ECM_APPL5 "0000000000000000h";
BA_ "FlexKomSigStartPos" SG_ 912 ECM_APPL5 7;
BA_ "FlexKomSigName" SG_ 912 ECM_APPL5 "ECM_APPL5";
BA_ "FlexKomSigLaenge" SG_ 912 ECM_APPL5 64;
BA_ "FlexKomSID" SG_ 912 ECM_APPL5 783;
BA_ "FlexKomIsMotorola" SG_ 912 ECM_APPL5 1;
BA_ "FlexKomComment" SG_ 912 ECM_APPL5 "CCP 10ms DAQ  (from ENGINE to external tool)";
BA_ "GenSigSNA" SG_ 928 ECM_APPL6 "0h";
BA_ "GenSigSendType" SG_ 928 ECM_APPL6 1;
BA_ "FlexKomSigStartValue" SG_ 928 ECM_APPL6 "0000000000000000h";
BA_ "FlexKomSigStartPos" SG_ 928 ECM_APPL6 7;
BA_ "FlexKomSigName" SG_ 928 ECM_APPL6 "ECM_APPL6";
BA_ "FlexKomSigLaenge" SG_ 928 ECM_APPL6 64;
BA_ "FlexKomSID" SG_ 928 ECM_APPL6 784;
BA_ "FlexKomIsMotorola" SG_ 928 ECM_APPL6 1;
BA_ "FlexKomComment" SG_ 928 ECM_APPL6 "CCP 80ms DAQ  (from ENGINE to external tool)";
BA_ "GenSigSNA" SG_ 936 ECM_APPL7 "0h";
BA_ "GenSigSendType" SG_ 936 ECM_APPL7 1;
BA_ "FlexKomSigStartValue" SG_ 936 ECM_APPL7 "0000000000000000h";
BA_ "FlexKomSigStartPos" SG_ 936 ECM_APPL7 7;
BA_ "FlexKomSigName" SG_ 936 ECM_APPL7 "ECM_APPL7";
BA_ "FlexKomSigLaenge" SG_ 936 ECM_APPL7 64;
BA_ "FlexKomSID" SG_ 936 ECM_APPL7 1111;
BA_ "FlexKomIsMotorola" SG_ 936 ECM_APPL7 1;
BA_ "FlexKomComment" SG_ 936 ECM_APPL7 "Application";
BA_ "GenSigStartValue" SG_ 676 CRC_ECM_B11 255;
BA_ "GenSigSNA" SG_ 676 CRC_ECM_B11 "FFh";
BA_ "GenSigCycleTime" SG_ 676 CRC_ECM_B11 100;
BA_ "FlexKomSigStartValue" SG_ 676 CRC_ECM_B11 "FFh";
BA_ "FlexKomSigStartPos" SG_ 676 CRC_ECM_B11 63;
BA_ "FlexKomSigName" SG_ 676 CRC_ECM_B11 "CRC_ECM_B11";
BA_ "FlexKomSigLaenge" SG_ 676 CRC_ECM_B11 8;
BA_ "FlexKomSID" SG_ 676 CRC_ECM_B11 2793;
BA_ "FlexKomIsMotorola" SG_ 676 CRC_ECM_B11 1;
BA_ "FlexKomComment" SG_ 676 CRC_ECM_B11 "CRC-Checksum Byte 1 - 7 according to SAE J1850";
BA_ "GenSigTimeout_IC" SG_ 676 ECM_WARN_EXT 1050;
BA_ "GenSigSNA" SG_ 676 ECM_WARN_EXT "1Fh";
BA_ "GenSigCycleTime" SG_ 676 ECM_WARN_EXT 100;
BA_ "FlexKomSigStartValue" SG_ 676 ECM_WARN_EXT "00h";
BA_ "FlexKomSigStartPos" SG_ 676 ECM_WARN_EXT 28;
BA_ "FlexKomSigName" SG_ 676 ECM_WARN_EXT "ECM_WARN_EXT";
BA_ "FlexKomSigLaenge" SG_ 676 ECM_WARN_EXT 5;
BA_ "FlexKomSID" SG_ 676 ECM_WARN_EXT 2727;
BA_ "FlexKomIsMotorola" SG_ 676 ECM_WARN_EXT 1;
BA_ "FlexKomComment" SG_ 676 ECM_WARN_EXT "HMI extended warnings";
BA_ "GenSigStartValue" SG_ 676 MAP_4_Bar 511;
BA_ "GenSigSNA" SG_ 676 MAP_4_Bar "1FFh";
BA_ "GenSigCycleTime" SG_ 676 MAP_4_Bar 100;
BA_ "FlexKomSigStartValue" SG_ 676 MAP_4_Bar "01FFh";
BA_ "FlexKomSigStartPos" SG_ 676 MAP_4_Bar 7;
BA_ "FlexKomSigName" SG_ 676 MAP_4_Bar "MAP_4_Bar";
BA_ "FlexKomSigLaenge" SG_ 676 MAP_4_Bar 16;
BA_ "FlexKomSID" SG_ 676 MAP_4_Bar 2688;
BA_ "FlexKomIsMotorola" SG_ 676 MAP_4_Bar 1;
BA_ "FlexKomComment" SG_ 676 MAP_4_Bar "Engine manifold pressure (4 bar range)";
BA_ "GenSigSNA" SG_ 676 MC_ECM_B11 "0h";
BA_ "GenSigCycleTime" SG_ 676 MC_ECM_B11 100;
BA_ "FlexKomSigStartValue" SG_ 676 MC_ECM_B11 "00h";
BA_ "FlexKomSigStartPos" SG_ 676 MC_ECM_B11 55;
BA_ "FlexKomSigName" SG_ 676 MC_ECM_B11 "MC_ECM_B11";
BA_ "FlexKomSigLaenge" SG_ 676 MC_ECM_B11 4;
BA_ "FlexKomSID" SG_ 676 MC_ECM_B11 2792;
BA_ "FlexKomIsMotorola" SG_ 676 MC_ECM_B11 1;
BA_ "FlexKomComment" SG_ 676 MC_ECM_B11 "Message Counter";
BA_ "GenSigSNA" SG_ 676 TransWarmup_Enbl_Rq "0h";
BA_ "GenSigCycleTime" SG_ 676 TransWarmup_Enbl_Rq 100;
BA_ "FlexKomSigStartValue" SG_ 676 TransWarmup_Enbl_Rq "00h";
BA_ "FlexKomSigStartPos" SG_ 676 TransWarmup_Enbl_Rq 20;
BA_ "FlexKomSigName" SG_ 676 TransWarmup_Enbl_Rq "TransWarmup_Enbl_Rq";
BA_ "FlexKomSigLaenge" SG_ 676 TransWarmup_Enbl_Rq 1;
BA_ "FlexKomSID" SG_ 676 TransWarmup_Enbl_Rq 2790;
BA_ "FlexKomIsMotorola" SG_ 676 TransWarmup_Enbl_Rq 1;
BA_ "FlexKomComment" SG_ 676 TransWarmup_Enbl_Rq "Enable and disable flag for transmission warm up f";
BA_ "GenSigSNA" SG_ 676 TransWarmup_Min_RPM "FFh";
BA_ "GenSigCycleTime" SG_ 676 TransWarmup_Min_RPM 100;
BA_ "FlexKomSigStartValue" SG_ 676 TransWarmup_Min_RPM "00h";
BA_ "FlexKomSigStartPos" SG_ 676 TransWarmup_Min_RPM 39;
BA_ "FlexKomSigName" SG_ 676 TransWarmup_Min_RPM "TransWarmup_Min_RPM";
BA_ "FlexKomSigLaenge" SG_ 676 TransWarmup_Min_RPM 8;
BA_ "FlexKomSID" SG_ 676 TransWarmup_Min_RPM 2791;
BA_ "FlexKomIsMotorola" SG_ 676 TransWarmup_Min_RPM 1;
BA_ "FlexKomComment" SG_ 676 TransWarmup_Min_RPM "Enable and disable flag for transmission warm up f";
BA_ "GenSigSNA" SG_ 311 CBC_Reset_ACK "0h";
BA_ "GenSigCycleTime" SG_ 311 CBC_Reset_ACK 100;
BA_ "FlexKomSigStartValue" SG_ 311 CBC_Reset_ACK "00h";
BA_ "FlexKomSigStartPos" SG_ 311 CBC_Reset_ACK 39;
BA_ "FlexKomSigName" SG_ 311 CBC_Reset_ACK "CBC_Reset_ACK";
BA_ "FlexKomSigLaenge" SG_ 311 CBC_Reset_ACK 1;
BA_ "FlexKomSID" SG_ 311 CBC_Reset_ACK 2529;
BA_ "FlexKomIsMotorola" SG_ 311 CBC_Reset_ACK 1;
BA_ "FlexKomComment" SG_ 311 CBC_Reset_ACK "CBC reset acknowledge; True = [1]";
BA_ "GenSigTimeout_IC" SG_ 311 CC_SetSpdDspl 1050;
BA_ "GenSigStartValue" SG_ 311 CC_SetSpdDspl 255;
BA_ "GenSigSNA" SG_ 311 CC_SetSpdDspl "FFh";
BA_ "GenSigCycleTime" SG_ 311 CC_SetSpdDspl 100;
BA_ "FlexKomSigStartValue" SG_ 311 CC_SetSpdDspl "FFh";
BA_ "FlexKomSigStartPos" SG_ 311 CC_SetSpdDspl 7;
BA_ "FlexKomSigName" SG_ 311 CC_SetSpdDspl "CC_SetSpdDspl";
BA_ "FlexKomSigLaenge" SG_ 311 CC_SetSpdDspl 8;
BA_ "FlexKomSID" SG_ 311 CC_SetSpdDspl 1361;
BA_ "FlexKomIsMotorola" SG_ 311 CC_SetSpdDspl 1;
BA_ "FlexKomComment" SG_ 311 CC_SetSpdDspl "Cruise control set speed for display (kmph only)";
BA_ "GenSigTimeout_IC" SG_ 311 CC_SetSpdDsplMPH 1050;
BA_ "GenSigStartValue" SG_ 311 CC_SetSpdDsplMPH 255;
BA_ "GenSigSNA" SG_ 311 CC_SetSpdDsplMPH "FFh";
BA_ "GenSigCycleTime" SG_ 311 CC_SetSpdDsplMPH 100;
BA_ "FlexKomSigStartValue" SG_ 311 CC_SetSpdDsplMPH "FFh";
BA_ "FlexKomSigStartPos" SG_ 311 CC_SetSpdDsplMPH 47;
BA_ "FlexKomSigName" SG_ 311 CC_SetSpdDsplMPH "CC_SetSpdDsplMPH";
BA_ "FlexKomSigLaenge" SG_ 311 CC_SetSpdDsplMPH 8;
BA_ "FlexKomSID" SG_ 311 CC_SetSpdDsplMPH 1610;
BA_ "FlexKomIsMotorola" SG_ 311 CC_SetSpdDsplMPH 1;
BA_ "FlexKomComment" SG_ 311 CC_SetSpdDsplMPH "Cruise control set speed for display in miles per ";
BA_ "RID" SG_ 311 CoolVlvPos "1282";
BA_ "GenSigTimeout_CBC" SG_ 311 CoolVlvPos 1050;
BA_ "GenSigStartValue" SG_ 311 CoolVlvPos 255;
BA_ "GenSigSNA" SG_ 311 CoolVlvPos "FFh";
BA_ "GenSigCycleTime" SG_ 311 CoolVlvPos 100;
BA_ "FlexKomSigStartValue" SG_ 311 CoolVlvPos "FFh";
BA_ "FlexKomSigStartPos" SG_ 311 CoolVlvPos 23;
BA_ "FlexKomSigName" SG_ 311 CoolVlvPos "CoolVlvPos";
BA_ "FlexKomSigLaenge" SG_ 311 CoolVlvPos 8;
BA_ "FlexKomSID" SG_ 311 CoolVlvPos 1446;
BA_ "FlexKomIsMotorola" SG_ 311 CoolVlvPos 1;
BA_ "FlexKomComment" SG_ 311 CoolVlvPos "Coolant (3-way) valve position";
BA_ "GenSigSNA" SG_ 311 EVPmpStat "3h";
BA_ "GenSigCycleTime" SG_ 311 EVPmpStat 100;
BA_ "FlexKomSigStartValue" SG_ 311 EVPmpStat "00h";
BA_ "FlexKomSigStartPos" SG_ 311 EVPmpStat 13;
BA_ "FlexKomSigName" SG_ 311 EVPmpStat "EVPmpStat";
BA_ "FlexKomSigLaenge" SG_ 311 EVPmpStat 2;
BA_ "FlexKomSID" SG_ 311 EVPmpStat 1418;
BA_ "FlexKomIsMotorola" SG_ 311 EVPmpStat 1;
BA_ "FlexKomComment" SG_ 311 EVPmpStat "Electric vacuum pump status";
BA_ "GenSigTimeout_IC" SG_ 311 EconShftRq 1050;
BA_ "GenSigSNA" SG_ 311 EconShftRq "3h";
BA_ "GenSigCycleTime" SG_ 311 EconShftRq 100;
BA_ "FlexKomSigStartValue" SG_ 311 EconShftRq "00h";
BA_ "FlexKomSigStartPos" SG_ 311 EconShftRq 15;
BA_ "FlexKomSigName" SG_ 311 EconShftRq "EconShftRq";
BA_ "FlexKomSigLaenge" SG_ 311 EconShftRq 2;
BA_ "FlexKomSID" SG_ 311 EconShftRq 1642;
BA_ "FlexKomIsMotorola" SG_ 311 EconShftRq 1;
BA_ "FlexKomComment" SG_ 311 EconShftRq "Economy transmission shift request";
BA_ "GenSigSNA" SG_ 311 SpStChmRq "0h";
BA_ "GenSigCycleTime" SG_ 311 SpStChmRq 100;
BA_ "FlexKomSigStartValue" SG_ 311 SpStChmRq "0000h";
BA_ "FlexKomSigStartPos" SG_ 311 SpStChmRq 55;
BA_ "FlexKomSigName" SG_ 311 SpStChmRq "SpStPacket";
BA_ "FlexKomSigLaenge" SG_ 311 SpStChmRq 16;
BA_ "FlexKomSID" SG_ 311 SpStChmRq 1567;
BA_ "FlexKomIsMotorola" SG_ 311 SpStChmRq 1;
BA_ "FlexKomComment" SG_ 311 SpStChmRq "Stop start packet";
BA_ "GenSigTimeout_ORC" SG_ 311 SpStDispstat 350;
BA_ "GenSigTimeout_IC" SG_ 311 SpStDispstat 1050;
BA_ "GenSigSNA" SG_ 311 SpStDispstat "3Fh";
BA_ "GenSigCycleTime" SG_ 311 SpStDispstat 100;
BA_ "FlexKomSigStartValue" SG_ 311 SpStDispstat "0000h";
BA_ "FlexKomSigStartPos" SG_ 311 SpStDispstat 55;
BA_ "FlexKomSigName" SG_ 311 SpStDispstat "SpStPacket";
BA_ "FlexKomSigLaenge" SG_ 311 SpStDispstat 16;
BA_ "FlexKomSID" SG_ 311 SpStDispstat 1567;
BA_ "FlexKomIsMotorola" SG_ 311 SpStDispstat 1;
BA_ "FlexKomComment" SG_ 311 SpStDispstat "Stop start packet";
BA_ "GenSigSNA" SG_ 311 SpStIndRq "0h";
BA_ "GenSigCycleTime" SG_ 311 SpStIndRq 100;
BA_ "FlexKomSigStartValue" SG_ 311 SpStIndRq "0000h";
BA_ "FlexKomSigStartPos" SG_ 311 SpStIndRq 55;
BA_ "FlexKomSigName" SG_ 311 SpStIndRq "SpStPacket";
BA_ "FlexKomSigLaenge" SG_ 311 SpStIndRq 16;
BA_ "FlexKomSID" SG_ 311 SpStIndRq 1567;
BA_ "FlexKomIsMotorola" SG_ 311 SpStIndRq 1;
BA_ "FlexKomComment" SG_ 311 SpStIndRq "Stop start packet";
BA_ "RID" SG_ 311 SpStSwStat "1002 1617 1706 5114";
BA_ "GenSigTimeout_ORC" SG_ 311 SpStSwStat 350;
BA_ "GenSigTimeout_IC" SG_ 311 SpStSwStat 1050;
BA_ "GenSigTimeout_CBC" SG_ 311 SpStSwStat 1050;
BA_ "GenSigSNA" SG_ 311 SpStSwStat "3h";
BA_ "GenSigCycleTime" SG_ 311 SpStSwStat 100;
BA_ "FlexKomSigStartValue" SG_ 311 SpStSwStat "0000h";
BA_ "FlexKomSigStartPos" SG_ 311 SpStSwStat 55;
BA_ "FlexKomSigName" SG_ 311 SpStSwStat "SpStPacket";
BA_ "FlexKomSigLaenge" SG_ 311 SpStSwStat 16;
BA_ "FlexKomSID" SG_ 311 SpStSwStat 1567;
BA_ "FlexKomIsMotorola" SG_ 311 SpStSwStat 1;
BA_ "FlexKomComment" SG_ 311 SpStSwStat "Stop start packet";
BA_ "GenSigTimeout_ORC" SG_ 311 SpStWarnStat 350;
BA_ "GenSigTimeout_IC" SG_ 311 SpStWarnStat 1050;
BA_ "GenSigSNA" SG_ 311 SpStWarnStat "Fh";
BA_ "GenSigCycleTime" SG_ 311 SpStWarnStat 100;
BA_ "FlexKomSigStartValue" SG_ 311 SpStWarnStat "0000h";
BA_ "FlexKomSigStartPos" SG_ 311 SpStWarnStat 55;
BA_ "FlexKomSigName" SG_ 311 SpStWarnStat "SpStPacket";
BA_ "FlexKomSigLaenge" SG_ 311 SpStWarnStat 16;
BA_ "FlexKomSID" SG_ 311 SpStWarnStat 1567;
BA_ "FlexKomIsMotorola" SG_ 311 SpStWarnStat 1;
BA_ "FlexKomComment" SG_ 311 SpStWarnStat "Stop start packet";
BA_ "RID" SG_ 295 AC_CLTCH_EGD "1165";
BA_ "GenSigSNA" SG_ 295 AC_CLTCH_EGD "0h";
BA_ "GenSigCycleTime" SG_ 295 AC_CLTCH_EGD 100;
BA_ "FlexKomSigStartValue" SG_ 295 AC_CLTCH_EGD "00h";
BA_ "FlexKomSigStartPos" SG_ 295 AC_CLTCH_EGD 47;
BA_ "FlexKomSigName" SG_ 295 AC_CLTCH_EGD "AC_CLTCH_EGD";
BA_ "FlexKomSigLaenge" SG_ 295 AC_CLTCH_EGD 1;
BA_ "FlexKomSID" SG_ 295 AC_CLTCH_EGD 1086;
BA_ "FlexKomIsMotorola" SG_ 295 AC_CLTCH_EGD 1;
BA_ "FlexKomComment" SG_ 295 AC_CLTCH_EGD "AC clutch engauged";
BA_ "GenSigTimeout_CBC" SG_ 295 AM_ECM_Prsnt 1050;
BA_ "GenSigSNA" SG_ 295 AM_ECM_Prsnt "3h";
BA_ "GenSigCycleTime" SG_ 295 AM_ECM_Prsnt 100;
BA_ "FlexKomSigStartValue" SG_ 295 AM_ECM_Prsnt "00h";
BA_ "FlexKomSigStartPos" SG_ 295 AM_ECM_Prsnt 46;
BA_ "FlexKomSigName" SG_ 295 AM_ECM_Prsnt "AM_ECM_Prsnt";
BA_ "FlexKomSigLaenge" SG_ 295 AM_ECM_Prsnt 2;
BA_ "FlexKomSID" SG_ 295 AM_ECM_Prsnt 1941;
BA_ "FlexKomIsMotorola" SG_ 295 AM_ECM_Prsnt 1;
BA_ "FlexKomComment" SG_ 295 AM_ECM_Prsnt "Aftermarket ECM present";
BA_ "GenSigTimeout_TPM" SG_ 295 AirPress_Outsd 1050;
BA_ "GenSigTimeout_RF_HUB" SG_ 295 AirPress_Outsd 1050;
BA_ "GenSigTimeout_IC" SG_ 295 AirPress_Outsd 1050;
BA_ "GenSigTimeout_ETM" SG_ 295 AirPress_Outsd 1050;
BA_ "GenSigStartValue" SG_ 295 AirPress_Outsd 255;
BA_ "GenSigSNA" SG_ 295 AirPress_Outsd "FFh";
BA_ "GenSigCycleTime" SG_ 295 AirPress_Outsd 100;
BA_ "FlexKomSigStartValue" SG_ 295 AirPress_Outsd "FFh";
BA_ "FlexKomSigStartPos" SG_ 295 AirPress_Outsd 23;
BA_ "FlexKomSigName" SG_ 295 AirPress_Outsd "AirPress_Outsd";
BA_ "FlexKomSigLaenge" SG_ 295 AirPress_Outsd 8;
BA_ "FlexKomSID" SG_ 295 AirPress_Outsd 1084;
BA_ "FlexKomIsMotorola" SG_ 295 AirPress_Outsd 1;
BA_ "FlexKomComment" SG_ 295 AirPress_Outsd "Ambient air pressure (barometric pressure)";
BA_ "RID" SG_ 295 CHRG_FAIL "6549";
BA_ "GenSigTimeout_TBM" SG_ 295 CHRG_FAIL 1050;
BA_ "GenSigTimeout_ORC" SG_ 295 CHRG_FAIL 350;
BA_ "GenSigTimeout_IC" SG_ 295 CHRG_FAIL 1050;
BA_ "GenSigSNA" SG_ 295 CHRG_FAIL "1h";
BA_ "GenSigCycleTime" SG_ 295 CHRG_FAIL 100;
BA_ "FlexKomSigStartValue" SG_ 295 CHRG_FAIL "00h";
BA_ "FlexKomSigStartPos" SG_ 295 CHRG_FAIL 41;
BA_ "FlexKomSigName" SG_ 295 CHRG_FAIL "CHRG_FAIL";
BA_ "FlexKomSigLaenge" SG_ 295 CHRG_FAIL 1;
BA_ "FlexKomSID" SG_ 295 CHRG_FAIL 1085;
BA_ "FlexKomIsMotorola" SG_ 295 CHRG_FAIL 1;
BA_ "FlexKomComment" SG_ 295 CHRG_FAIL "Charging system Failure (battery indicator request";
BA_ "RID" SG_ 295 EngCoolTemp "1130";
BA_ "GenSigTimeout_TCM" SG_ 295 EngCoolTemp 1050;
BA_ "GenSigTimeout_TBM" SG_ 295 EngCoolTemp 1050;
BA_ "GenSigTimeout_IC" SG_ 295 EngCoolTemp 1050;
BA_ "GenSigTimeout_CBC" SG_ 295 EngCoolTemp 1050;
BA_ "GenSigStartValue" SG_ 295 EngCoolTemp 255;
BA_ "GenSigSNA" SG_ 295 EngCoolTemp "FFh";
BA_ "GenSigCycleTime" SG_ 295 EngCoolTemp 100;
BA_ "FlexKomSigStartValue" SG_ 295 EngCoolTemp "FFh";
BA_ "FlexKomSigStartPos" SG_ 295 EngCoolTemp 15;
BA_ "FlexKomSigName" SG_ 295 EngCoolTemp "EngCoolTemp";
BA_ "FlexKomSigLaenge" SG_ 295 EngCoolTemp 8;
BA_ "FlexKomSID" SG_ 295 EngCoolTemp 711;
BA_ "FlexKomIsMotorola" SG_ 295 EngCoolTemp 1;
BA_ "FlexKomComment" SG_ 295 EngCoolTemp "Engine coolant temperature";
BA_ "RID" SG_ 295 IntkAirTemp "1149";
BA_ "GenSigTimeout_IC" SG_ 295 IntkAirTemp 1050;
BA_ "GenSigTimeout_ETM" SG_ 295 IntkAirTemp 1050;
BA_ "GenSigSNA" SG_ 295 IntkAirTemp "FFh";
BA_ "GenSigCycleTime" SG_ 295 IntkAirTemp 100;
BA_ "FlexKomSigStartValue" SG_ 295 IntkAirTemp "00h";
BA_ "FlexKomSigStartPos" SG_ 295 IntkAirTemp 7;
BA_ "FlexKomSigName" SG_ 295 IntkAirTemp "IntkAirTemp";
BA_ "FlexKomSigLaenge" SG_ 295 IntkAirTemp 8;
BA_ "FlexKomSID" SG_ 295 IntkAirTemp 441;
BA_ "FlexKomIsMotorola" SG_ 295 IntkAirTemp 1;
BA_ "FlexKomComment" SG_ 295 IntkAirTemp "Engine Intake Air Temperature";
BA_ "RID" SG_ 295 R134a_Press_Stat "1167";
BA_ "GenSigTimeout_CBC" SG_ 295 R134a_Press_Stat 1050;
BA_ "GenSigStartValue" SG_ 295 R134a_Press_Stat 511;
BA_ "GenSigSNA" SG_ 295 R134a_Press_Stat "1FFh";
BA_ "GenSigCycleTime" SG_ 295 R134a_Press_Stat 100;
BA_ "FlexKomSigStartValue" SG_ 295 R134a_Press_Stat "01FFh";
BA_ "FlexKomSigStartPos" SG_ 295 R134a_Press_Stat 47;
BA_ "FlexKomSigName" SG_ 295 R134a_Press_Stat "R134a_Press_Stat";
BA_ "FlexKomSigLaenge" SG_ 295 R134a_Press_Stat 16;
BA_ "FlexKomSID" SG_ 295 R134a_Press_Stat 787;
BA_ "FlexKomIsMotorola" SG_ 295 R134a_Press_Stat 1;
BA_ "FlexKomComment" SG_ 295 R134a_Press_Stat "Refrigerant pressure (R134a or R1234YF)";
BA_ "GenSigSNA" SG_ 295 SysVolt "FFh";
BA_ "GenSigCycleTime" SG_ 295 SysVolt 100;
BA_ "FlexKomSigStartValue" SG_ 295 SysVolt "0000h";
BA_ "FlexKomSigStartPos" SG_ 295 SysVolt 31;
BA_ "FlexKomSigName" SG_ 295 SysVolt "EngVoltPkt";
BA_ "FlexKomSigLaenge" SG_ 295 SysVolt 16;
BA_ "FlexKomSID" SG_ 295 SysVolt 437;
BA_ "FlexKomIsMotorola" SG_ 295 SysVolt 1;
BA_ "FlexKomComment" SG_ 295 SysVolt "Engine voltage packet";
BA_ "GenSigTimeout_IC" SG_ 633 DisOilLifeRst 10500;
BA_ "GenSigTimeout_ETM" SG_ 633 DisOilLifeRst 10500;
BA_ "GenSigTimeout_CBC" SG_ 633 DisOilLifeRst 10500;
BA_ "GenSigStartValue" SG_ 633 DisOilLifeRst 65535;
BA_ "GenSigSNA" SG_ 633 DisOilLifeRst "FFFFh";
BA_ "GenSigCycleTime" SG_ 633 DisOilLifeRst 1000;
BA_ "FlexKomSigStartValue" SG_ 633 DisOilLifeRst "FFFFFF0FFFh";
BA_ "FlexKomSigStartPos" SG_ 633 DisOilLifeRst 7;
BA_ "FlexKomSigName" SG_ 633 DisOilLifeRst "OilLifePkt";
BA_ "FlexKomSigLaenge" SG_ 633 DisOilLifeRst 40;
BA_ "FlexKomSID" SG_ 633 DisOilLifeRst 1668;
BA_ "FlexKomIsMotorola" SG_ 633 DisOilLifeRst 1;
BA_ "FlexKomComment" SG_ 633 DisOilLifeRst "Oil life packet";
BA_ "GenSigTimeout_IC" SG_ 633 FuelMM_Sts 10500;
BA_ "GenSigSNA" SG_ 633 FuelMM_Sts "0h";
BA_ "GenSigCycleTime" SG_ 633 FuelMM_Sts 1000;
BA_ "FlexKomSigStartValue" SG_ 633 FuelMM_Sts "00h";
BA_ "FlexKomSigStartPos" SG_ 633 FuelMM_Sts 47;
BA_ "FlexKomSigName" SG_ 633 FuelMM_Sts "FuelMM_Sts";
BA_ "FlexKomSigLaenge" SG_ 633 FuelMM_Sts 8;
BA_ "FlexKomSID" SG_ 633 FuelMM_Sts 2550;
BA_ "FlexKomIsMotorola" SG_ 633 FuelMM_Sts 1;
BA_ "FlexKomComment" SG_ 633 FuelMM_Sts "Fuel maintenance mode status";
BA_ "GenSigTimeout_TBM" SG_ 633 HoursOilLifeRst 10500;
BA_ "GenSigTimeout_IC" SG_ 633 HoursOilLifeRst 10500;
BA_ "GenSigTimeout_ETM" SG_ 633 HoursOilLifeRst 10500;
BA_ "GenSigTimeout_CBC" SG_ 633 HoursOilLifeRst 10500;
BA_ "GenSigStartValue" SG_ 633 HoursOilLifeRst 4095;
BA_ "GenSigSNA" SG_ 633 HoursOilLifeRst "FFFh";
BA_ "GenSigCycleTime" SG_ 633 HoursOilLifeRst 1000;
BA_ "FlexKomSigStartValue" SG_ 633 HoursOilLifeRst "FFFFFF0FFFh";
BA_ "FlexKomSigStartPos" SG_ 633 HoursOilLifeRst 7;
BA_ "FlexKomSigName" SG_ 633 HoursOilLifeRst "OilLifePkt";
BA_ "FlexKomSigLaenge" SG_ 633 HoursOilLifeRst 40;
BA_ "FlexKomSID" SG_ 633 HoursOilLifeRst 1668;
BA_ "FlexKomIsMotorola" SG_ 633 HoursOilLifeRst 1;
BA_ "FlexKomComment" SG_ 633 HoursOilLifeRst "Oil life packet";
BA_ "GenSigTimeout_TBM" SG_ 633 MntncSts 10500;
BA_ "GenSigTimeout_IC" SG_ 633 MntncSts 10500;
BA_ "GenSigTimeout_ETM" SG_ 633 MntncSts 10500;
BA_ "GenSigSNA" SG_ 633 MntncSts "3h";
BA_ "GenSigCycleTime" SG_ 633 MntncSts 1000;
BA_ "FlexKomSigStartValue" SG_ 633 MntncSts "FFFFFF0FFFh";
BA_ "FlexKomSigStartPos" SG_ 633 MntncSts 7;
BA_ "FlexKomSigName" SG_ 633 MntncSts "OilLifePkt";
BA_ "FlexKomSigLaenge" SG_ 633 MntncSts 40;
BA_ "FlexKomSID" SG_ 633 MntncSts 1668;
BA_ "FlexKomIsMotorola" SG_ 633 MntncSts 1;
BA_ "FlexKomComment" SG_ 633 MntncSts "Oil life packet";
BA_ "GenSigTimeout_TBM" SG_ 633 OilLifeLeft 10500;
BA_ "GenSigTimeout_IC" SG_ 633 OilLifeLeft 10500;
BA_ "GenSigTimeout_ETM" SG_ 633 OilLifeLeft 10500;
BA_ "GenSigStartValue" SG_ 633 OilLifeLeft 255;
BA_ "GenSigSNA" SG_ 633 OilLifeLeft "FFh";
BA_ "GenSigCycleTime" SG_ 633 OilLifeLeft 1000;
BA_ "FlexKomSigStartValue" SG_ 633 OilLifeLeft "FFFFFF0FFFh";
BA_ "FlexKomSigStartPos" SG_ 633 OilLifeLeft 7;
BA_ "FlexKomSigName" SG_ 633 OilLifeLeft "OilLifePkt";
BA_ "FlexKomSigLaenge" SG_ 633 OilLifeLeft 40;
BA_ "FlexKomSID" SG_ 633 OilLifeLeft 1668;
BA_ "FlexKomIsMotorola" SG_ 633 OilLifeLeft 1;
BA_ "FlexKomComment" SG_ 633 OilLifeLeft "Oil life packet";
BA_ "RID" SG_ 633 OilLifeLeftRst "1619";
BA_ "GenSigTimeout_TBM" SG_ 633 OilLifeLeftRst 10500;
BA_ "GenSigTimeout_IC" SG_ 633 OilLifeLeftRst 10500;
BA_ "GenSigTimeout_ETM" SG_ 633 OilLifeLeftRst 10500;
BA_ "GenSigSNA" SG_ 633 OilLifeLeftRst "0h";
BA_ "GenSigCycleTime" SG_ 633 OilLifeLeftRst 1000;
BA_ "FlexKomSigStartValue" SG_ 633 OilLifeLeftRst "FFFFFF0FFFh";
BA_ "FlexKomSigStartPos" SG_ 633 OilLifeLeftRst 7;
BA_ "FlexKomSigName" SG_ 633 OilLifeLeftRst "OilLifePkt";
BA_ "FlexKomSigLaenge" SG_ 633 OilLifeLeftRst 40;
BA_ "FlexKomSID" SG_ 633 OilLifeLeftRst 1668;
BA_ "FlexKomIsMotorola" SG_ 633 OilLifeLeftRst 1;
BA_ "FlexKomComment" SG_ 633 OilLifeLeftRst "Oil life packet";
BA_ "GenSigTimeout_IC" SG_ 323 DrvAway_Alert 1050;
BA_ "GenSigSNA" SG_ 323 DrvAway_Alert "0h";
BA_ "GenSigCycleTime" SG_ 323 DrvAway_Alert 100;
BA_ "FlexKomSigStartValue" SG_ 323 DrvAway_Alert "00h";
BA_ "FlexKomSigStartPos" SG_ 323 DrvAway_Alert 7;
BA_ "FlexKomSigName" SG_ 323 DrvAway_Alert "DrvAway_Alert";
BA_ "FlexKomSigLaenge" SG_ 323 DrvAway_Alert 1;
BA_ "FlexKomSID" SG_ 323 DrvAway_Alert 2390;
BA_ "FlexKomIsMotorola" SG_ 323 DrvAway_Alert 1;
BA_ "FlexKomComment" SG_ 323 DrvAway_Alert "Drive Away Alert; True = [1]";
BA_ "GenSigTimeout_IC" SG_ 323 DrvAway_Inhibit 1050;
BA_ "GenSigSNA" SG_ 323 DrvAway_Inhibit "0h";
BA_ "GenSigCycleTime" SG_ 323 DrvAway_Inhibit 100;
BA_ "FlexKomSigStartValue" SG_ 323 DrvAway_Inhibit "00h";
BA_ "FlexKomSigStartPos" SG_ 323 DrvAway_Inhibit 15;
BA_ "FlexKomSigName" SG_ 323 DrvAway_Inhibit "DrvAway_Inhibit";
BA_ "FlexKomSigLaenge" SG_ 323 DrvAway_Inhibit 1;
BA_ "FlexKomSID" SG_ 323 DrvAway_Inhibit 2391;
BA_ "FlexKomIsMotorola" SG_ 323 DrvAway_Inhibit 1;
BA_ "FlexKomComment" SG_ 323 DrvAway_Inhibit "Drive Away Inhibit; True = [1]";
BA_ "GenSigSNA" SG_ 347 AWD_LOW "0h";
BA_ "GenSigCycleTime" SG_ 347 AWD_LOW 100;
BA_ "FlexKomSigStartValue" SG_ 347 AWD_LOW "00h";
BA_ "FlexKomSigStartPos" SG_ 347 AWD_LOW 7;
BA_ "FlexKomSigName" SG_ 347 AWD_LOW "AWD_LOW";
BA_ "FlexKomSigLaenge" SG_ 347 AWD_LOW 1;
BA_ "FlexKomSID" SG_ 347 AWD_LOW 2977;
BA_ "FlexKomIsMotorola" SG_ 347 AWD_LOW 1;
BA_ "FlexKomComment" SG_ 347 AWD_LOW "AWD LOW status; 0 4LOW_Not_Active 1 4LOW_Active";
BA_ "GenSigSNA" SG_ 347 ECM_CODE_CLR "0h";
BA_ "GenSigCycleTime" SG_ 347 ECM_CODE_CLR 100;
BA_ "FlexKomSigStartValue" SG_ 347 ECM_CODE_CLR "00h";
BA_ "FlexKomSigStartPos" SG_ 347 ECM_CODE_CLR 41;
BA_ "FlexKomSigName" SG_ 347 ECM_CODE_CLR "ECM_CODE_READINESS_PDU";
BA_ "FlexKomSigLaenge" SG_ 347 ECM_CODE_CLR 2;
BA_ "FlexKomSID" SG_ 347 ECM_CODE_CLR 2963;
BA_ "FlexKomIsMotorola" SG_ 347 ECM_CODE_CLR 1;
BA_ "FlexKomComment" SG_ 347 ECM_CODE_CLR "ECM Code Readiness PDU";
BA_ "GenSigSNA" SG_ 347 ECM_READINESS_RESET "0h";
BA_ "GenSigCycleTime" SG_ 347 ECM_READINESS_RESET 100;
BA_ "FlexKomSigStartValue" SG_ 347 ECM_READINESS_RESET "00h";
BA_ "FlexKomSigStartPos" SG_ 347 ECM_READINESS_RESET 41;
BA_ "FlexKomSigName" SG_ 347 ECM_READINESS_RESET "ECM_CODE_READINESS_PDU";
BA_ "FlexKomSigLaenge" SG_ 347 ECM_READINESS_RESET 2;
BA_ "FlexKomSID" SG_ 347 ECM_READINESS_RESET 2963;
BA_ "FlexKomIsMotorola" SG_ 347 ECM_READINESS_RESET 1;
BA_ "FlexKomComment" SG_ 347 ECM_READINESS_RESET "ECM Code Readiness PDU";
BA_ "GenSigTimeout_CBC" SG_ 347 RevOilLifeRst 1050;
BA_ "GenSigStartValue" SG_ 347 RevOilLifeRst 65535;
BA_ "GenSigSNA" SG_ 347 RevOilLifeRst "FFFFh";
BA_ "GenSigCycleTime" SG_ 347 RevOilLifeRst 100;
BA_ "FlexKomSigStartValue" SG_ 347 RevOilLifeRst "FFFFh";
BA_ "FlexKomSigStartPos" SG_ 347 RevOilLifeRst 55;
BA_ "FlexKomSigName" SG_ 347 RevOilLifeRst "RevOilLifeRst";
BA_ "FlexKomSigLaenge" SG_ 347 RevOilLifeRst 16;
BA_ "FlexKomSID" SG_ 347 RevOilLifeRst 2109;
BA_ "FlexKomIsMotorola" SG_ 347 RevOilLifeRst 1;
BA_ "FlexKomComment" SG_ 347 RevOilLifeRst "Engine revolutions since last oil life reset";
BA_ "GenSigSNA" SG_ 343 LeakCheckTimerValue "1FFh";
BA_ "GenSigCycleTime" SG_ 343 LeakCheckTimerValue 100;
BA_ "FlexKomSigStartValue" SG_ 343 LeakCheckTimerValue "0000h";
BA_ "FlexKomSigStartPos" SG_ 343 LeakCheckTimerValue 15;
BA_ "FlexKomSigName" SG_ 343 LeakCheckTimerValue "LeakCheckTimerValue";
BA_ "FlexKomSigLaenge" SG_ 343 LeakCheckTimerValue 16;
BA_ "FlexKomSID" SG_ 343 LeakCheckTimerValue 2575;
BA_ "FlexKomIsMotorola" SG_ 343 LeakCheckTimerValue 1;
BA_ "FlexKomComment" SG_ 343 LeakCheckTimerValue "Requested leak test timer value";
BA_ "GenSigSNA" SG_ 343 LeakTestRequest "0h";
BA_ "GenSigCycleTime" SG_ 343 LeakTestRequest 100;
BA_ "FlexKomSigStartValue" SG_ 343 LeakTestRequest "00h";
BA_ "FlexKomSigStartPos" SG_ 343 LeakTestRequest 26;
BA_ "FlexKomSigName" SG_ 343 LeakTestRequest "LeakTestRequest";
BA_ "FlexKomSigLaenge" SG_ 343 LeakTestRequest 1;
BA_ "FlexKomSID" SG_ 343 LeakTestRequest 2577;
BA_ "FlexKomIsMotorola" SG_ 343 LeakTestRequest 1;
BA_ "FlexKomComment" SG_ 343 LeakTestRequest "Leak test is requested after powerdown; No request";
BA_ "GenSigSNA" SG_ 343 LeakTestSts "0h";
BA_ "GenSigCycleTime" SG_ 343 LeakTestSts 100;
BA_ "FlexKomSigStartValue" SG_ 343 LeakTestSts "00h";
BA_ "FlexKomSigStartPos" SG_ 343 LeakTestSts 28;
BA_ "FlexKomSigName" SG_ 343 LeakTestSts "LeakTestSts";
BA_ "FlexKomSigLaenge" SG_ 343 LeakTestSts 2;
BA_ "FlexKomSID" SG_ 343 LeakTestSts 2576;
BA_ "FlexKomIsMotorola" SG_ 343 LeakTestSts 1;
BA_ "FlexKomComment" SG_ 343 LeakTestSts "Status of leak test";
BA_ "GenSigSNA" SG_ 343 RefuelEvent "0h";
BA_ "GenSigCycleTime" SG_ 343 RefuelEvent 100;
BA_ "FlexKomSigStartValue" SG_ 343 RefuelEvent "00h";
BA_ "FlexKomSigStartPos" SG_ 343 RefuelEvent 13;
BA_ "FlexKomSigName" SG_ 343 RefuelEvent "RefuelEvent";
BA_ "FlexKomSigLaenge" SG_ 343 RefuelEvent 3;
BA_ "FlexKomSID" SG_ 343 RefuelEvent 2574;
BA_ "FlexKomIsMotorola" SG_ 343 RefuelEvent 1;
BA_ "FlexKomComment" SG_ 343 RefuelEvent "Status of refuel event";
BA_ "GenSigTimeout_IC" SG_ 343 RefuelIndication 1050;
BA_ "GenSigSNA" SG_ 343 RefuelIndication "0h";
BA_ "GenSigCycleTime" SG_ 343 RefuelIndication 100;
BA_ "FlexKomSigStartValue" SG_ 343 RefuelIndication "00h";
BA_ "FlexKomSigStartPos" SG_ 343 RefuelIndication 31;
BA_ "FlexKomSigName" SG_ 343 RefuelIndication "RefuelIndication";
BA_ "FlexKomSigLaenge" SG_ 343 RefuelIndication 3;
BA_ "FlexKomSID" SG_ 343 RefuelIndication 2578;
BA_ "FlexKomIsMotorola" SG_ 343 RefuelIndication 1;
BA_ "FlexKomComment" SG_ 343 RefuelIndication "Indication to the driver about the status of the r";
BA_ "GenSigTimeout_CBC" SG_ 343 SAMInfo 1050;
BA_ "GenSigStartValue" SG_ 343 SAMInfo 15;
BA_ "GenSigSNA" SG_ 343 SAMInfo "Fh";
BA_ "GenSigCycleTime" SG_ 343 SAMInfo 100;
BA_ "FlexKomSigStartValue" SG_ 343 SAMInfo "0Fh";
BA_ "FlexKomSigStartPos" SG_ 343 SAMInfo 39;
BA_ "FlexKomSigName" SG_ 343 SAMInfo "SAMInfo";
BA_ "FlexKomSigLaenge" SG_ 343 SAMInfo 4;
BA_ "FlexKomSID" SG_ 343 SAMInfo 2649;
BA_ "FlexKomIsMotorola" SG_ 343 SAMInfo 1;
BA_ "FlexKomComment" SG_ 343 SAMInfo "Logic status of the SAM strategy";
BA_ "GenSigTimeout_IC" SG_ 343 StartProtectionInhibit 1050;
BA_ "GenSigSNA" SG_ 343 StartProtectionInhibit "3h";
BA_ "GenSigCycleTime" SG_ 343 StartProtectionInhibit 100;
BA_ "FlexKomSigStartValue" SG_ 343 StartProtectionInhibit "00h";
BA_ "FlexKomSigStartPos" SG_ 343 StartProtectionInhibit 25;
BA_ "FlexKomSigName" SG_ 343 StartProtectionInhibit "StartProtectionInhibit";
BA_ "FlexKomSigLaenge" SG_ 343 StartProtectionInhibit 2;
BA_ "FlexKomSID" SG_ 343 StartProtectionInhibit 2612;
BA_ "FlexKomIsMotorola" SG_ 343 StartProtectionInhibit 1;
BA_ "FlexKomComment" SG_ 343 StartProtectionInhibit "Starter protection status";
BA_ "GenSigTimeout_IC" SG_ 343 StarterProtectionTime 1050;
BA_ "GenSigSNA" SG_ 343 StarterProtectionTime "FFh";
BA_ "GenSigCycleTime" SG_ 343 StarterProtectionTime 100;
BA_ "FlexKomSigStartValue" SG_ 343 StarterProtectionTime "00h";
BA_ "FlexKomSigStartPos" SG_ 343 StarterProtectionTime 47;
BA_ "FlexKomSigName" SG_ 343 StarterProtectionTime "StarterProtectionTime";
BA_ "FlexKomSigLaenge" SG_ 343 StarterProtectionTime 8;
BA_ "FlexKomSID" SG_ 343 StarterProtectionTime 2613;
BA_ "FlexKomIsMotorola" SG_ 343 StarterProtectionTime 1;
BA_ "FlexKomComment" SG_ 343 StarterProtectionTime "Starter protection time";
BA_ "GenSigTimeout_IC" SG_ 129 BARO_ENG 210;
BA_ "GenSigSNA" SG_ 129 BARO_ENG "FFh";
BA_ "GenSigCycleTime" SG_ 129 BARO_ENG 20;
BA_ "FlexKomSigStartValue" SG_ 129 BARO_ENG "FF00FFFF00FFh";
BA_ "FlexKomSigStartPos" SG_ 129 BARO_ENG 23;
BA_ "FlexKomSigName" SG_ 129 BARO_ENG "Engine_1_Pkt";
BA_ "FlexKomSigLaenge" SG_ 129 BARO_ENG 48;
BA_ "FlexKomSID" SG_ 129 BARO_ENG 1352;
BA_ "FlexKomIsMotorola" SG_ 129 BARO_ENG 1;
BA_ "FlexKomComment" SG_ 129 BARO_ENG "General engine Data";
BA_ "RID" SG_ 129 CRUISE_EGD "1101";
BA_ "GenSigTimeout_TCM" SG_ 129 CRUISE_EGD 210;
BA_ "GenSigTimeout_ORC" SG_ 129 CRUISE_EGD 70;
BA_ "GenSigTimeout_IC" SG_ 129 CRUISE_EGD 210;
BA_ "GenSigTimeout_CBC" SG_ 129 CRUISE_EGD 210;
BA_ "GenSigSNA" SG_ 129 CRUISE_EGD "0h";
BA_ "GenSigCycleTime" SG_ 129 CRUISE_EGD 20;
BA_ "FlexKomSigStartValue" SG_ 129 CRUISE_EGD "00h";
BA_ "FlexKomSigStartPos" SG_ 129 CRUISE_EGD 5;
BA_ "FlexKomSigName" SG_ 129 CRUISE_EGD "CRUISE_EGD";
BA_ "FlexKomSigLaenge" SG_ 129 CRUISE_EGD 1;
BA_ "FlexKomSID" SG_ 129 CRUISE_EGD 856;
BA_ "FlexKomIsMotorola" SG_ 129 CRUISE_EGD 1;
BA_ "FlexKomComment" SG_ 129 CRUISE_EGD "Cruise system is controlling speed";
BA_ "GenSigTimeout_SCCM" SG_ 129 CRUISE_ON 210;
BA_ "GenSigTimeout_ORC" SG_ 129 CRUISE_ON 70;
BA_ "GenSigTimeout_IC" SG_ 129 CRUISE_ON 210;
BA_ "GenSigSNA" SG_ 129 CRUISE_ON "0h";
BA_ "GenSigCycleTime" SG_ 129 CRUISE_ON 20;
BA_ "FlexKomSigStartValue" SG_ 129 CRUISE_ON "00h";
BA_ "FlexKomSigStartPos" SG_ 129 CRUISE_ON 7;
BA_ "FlexKomSigName" SG_ 129 CRUISE_ON "CRUISE_ON";
BA_ "FlexKomSigLaenge" SG_ 129 CRUISE_ON 1;
BA_ "FlexKomSID" SG_ 129 CRUISE_ON 1250;
BA_ "FlexKomIsMotorola" SG_ 129 CRUISE_ON 1;
BA_ "FlexKomComment" SG_ 129 CRUISE_ON "Cruise control system 'on'";
BA_ "GenSigTimeout_IC" SG_ 129 ECM_WARN 210;
BA_ "GenSigSNA" SG_ 129 ECM_WARN "7h";
BA_ "GenSigCycleTime" SG_ 129 ECM_WARN 20;
BA_ "FlexKomSigStartValue" SG_ 129 ECM_WARN "FF00FFFF00FFh";
BA_ "FlexKomSigStartPos" SG_ 129 ECM_WARN 23;
BA_ "FlexKomSigName" SG_ 129 ECM_WARN "Engine_1_Pkt";
BA_ "FlexKomSigLaenge" SG_ 129 ECM_WARN 48;
BA_ "FlexKomSID" SG_ 129 ECM_WARN 1352;
BA_ "FlexKomIsMotorola" SG_ 129 ECM_WARN 1;
BA_ "FlexKomComment" SG_ 129 ECM_WARN "General engine Data";
BA_ "GenSigTimeout_TBM" SG_ 129 MAP_ENG 210;
BA_ "GenSigTimeout_ETM" SG_ 129 MAP_ENG 1010;
BA_ "GenSigStartValue" SG_ 129 MAP_ENG 255;
BA_ "GenSigSNA" SG_ 129 MAP_ENG "FFh";
BA_ "GenSigCycleTime" SG_ 129 MAP_ENG 20;
BA_ "FlexKomSigStartValue" SG_ 129 MAP_ENG "FF00FFFF00FFh";
BA_ "FlexKomSigStartPos" SG_ 129 MAP_ENG 23;
BA_ "FlexKomSigName" SG_ 129 MAP_ENG "Engine_1_Pkt";
BA_ "FlexKomSigLaenge" SG_ 129 MAP_ENG 48;
BA_ "FlexKomSID" SG_ 129 MAP_ENG 1352;
BA_ "FlexKomIsMotorola" SG_ 129 MAP_ENG 1;
BA_ "FlexKomComment" SG_ 129 MAP_ENG "General engine Data";
BA_ "GenSigStartValue" SG_ 129 Rel_Pdl_ENG 255;
BA_ "GenSigSNA" SG_ 129 Rel_Pdl_ENG "FFh";
BA_ "GenSigCycleTime" SG_ 129 Rel_Pdl_ENG 20;
BA_ "FlexKomSigStartValue" SG_ 129 Rel_Pdl_ENG "FF00FFFF00FFh";
BA_ "FlexKomSigStartPos" SG_ 129 Rel_Pdl_ENG 23;
BA_ "FlexKomSigName" SG_ 129 Rel_Pdl_ENG "Engine_1_Pkt";
BA_ "FlexKomSigLaenge" SG_ 129 Rel_Pdl_ENG 48;
BA_ "FlexKomSID" SG_ 129 Rel_Pdl_ENG 1352;
BA_ "FlexKomIsMotorola" SG_ 129 Rel_Pdl_ENG 1;
BA_ "FlexKomComment" SG_ 129 Rel_Pdl_ENG "General engine Data";
BA_ "GenSigStartValue" SG_ 129 Rel_Thrt_ENG 255;
BA_ "GenSigSNA" SG_ 129 Rel_Thrt_ENG "FFh";
BA_ "GenSigCycleTime" SG_ 129 Rel_Thrt_ENG 20;
BA_ "FlexKomSigStartValue" SG_ 129 Rel_Thrt_ENG "FF00FFFF00FFh";
BA_ "FlexKomSigStartPos" SG_ 129 Rel_Thrt_ENG 23;
BA_ "FlexKomSigName" SG_ 129 Rel_Thrt_ENG "Engine_1_Pkt";
BA_ "FlexKomSigLaenge" SG_ 129 Rel_Thrt_ENG 48;
BA_ "FlexKomSID" SG_ 129 Rel_Thrt_ENG 1352;
BA_ "FlexKomIsMotorola" SG_ 129 Rel_Thrt_ENG 1;
BA_ "FlexKomComment" SG_ 129 Rel_Thrt_ENG "General engine Data";
BA_ "GenSigTimeout_IC" SG_ 129 SpeedLimitSts 210;
BA_ "GenSigStartValue" SG_ 129 SpeedLimitSts 2;
BA_ "GenSigSNA" SG_ 129 SpeedLimitSts "7h";
BA_ "GenSigCycleTime" SG_ 129 SpeedLimitSts 20;
BA_ "FlexKomSigStartValue" SG_ 129 SpeedLimitSts "02h";
BA_ "FlexKomSigStartPos" SG_ 129 SpeedLimitSts 4;
BA_ "FlexKomSigName" SG_ 129 SpeedLimitSts "SpeedLimitSts";
BA_ "FlexKomSigLaenge" SG_ 129 SpeedLimitSts 3;
BA_ "FlexKomSID" SG_ 129 SpeedLimitSts 1865;
BA_ "FlexKomIsMotorola" SG_ 129 SpeedLimitSts 1;
BA_ "FlexKomComment" SG_ 129 SpeedLimitSts "Speed limiter status";
BA_ "GenSigStartValue" SG_ 129 V_MAX_TM 255;
BA_ "GenSigSNA" SG_ 129 V_MAX_TM "FFh";
BA_ "GenSigCycleTime" SG_ 129 V_MAX_TM 20;
BA_ "FlexKomSigStartValue" SG_ 129 V_MAX_TM "FFh";
BA_ "FlexKomSigStartPos" SG_ 129 V_MAX_TM 15;
BA_ "FlexKomSigName" SG_ 129 V_MAX_TM "V_MAX_TM";
BA_ "FlexKomSigLaenge" SG_ 129 V_MAX_TM 8;
BA_ "FlexKomSID" SG_ 129 V_MAX_TM 1252;
BA_ "FlexKomIsMotorola" SG_ 129 V_MAX_TM 1;
BA_ "FlexKomComment" SG_ 129 V_MAX_TM "Max. or cruise control set speed";
BA_ "GenSigTimeout_IC" SG_ 301 AdblueRemainDist 1050;
BA_ "GenSigSNA" SG_ 301 AdblueRemainDist "FFFFh";
BA_ "GenSigCycleTime" SG_ 301 AdblueRemainDist 100;
BA_ "FlexKomSigStartValue" SG_ 301 AdblueRemainDist "00FF0000h";
BA_ "FlexKomSigStartPos" SG_ 301 AdblueRemainDist 39;
BA_ "FlexKomSigName" SG_ 301 AdblueRemainDist "AdblueDispRq";
BA_ "FlexKomSigLaenge" SG_ 301 AdblueRemainDist 32;
BA_ "FlexKomSID" SG_ 301 AdblueRemainDist 1436;
BA_ "FlexKomIsMotorola" SG_ 301 AdblueRemainDist 1;
BA_ "FlexKomComment" SG_ 301 AdblueRemainDist "Adblue display request";
BA_ "GenSigStartValue" SG_ 301 Adblue_FL_LVL 255;
BA_ "GenSigSNA" SG_ 301 Adblue_FL_LVL "FFh";
BA_ "GenSigCycleTime" SG_ 301 Adblue_FL_LVL 100;
BA_ "FlexKomSigStartValue" SG_ 301 Adblue_FL_LVL "00FF0000h";
BA_ "FlexKomSigStartPos" SG_ 301 Adblue_FL_LVL 39;
BA_ "FlexKomSigName" SG_ 301 Adblue_FL_LVL "AdblueDispRq";
BA_ "FlexKomSigLaenge" SG_ 301 Adblue_FL_LVL 32;
BA_ "FlexKomSID" SG_ 301 Adblue_FL_LVL 1436;
BA_ "FlexKomIsMotorola" SG_ 301 Adblue_FL_LVL 1;
BA_ "FlexKomComment" SG_ 301 Adblue_FL_LVL "Adblue display request";
BA_ "GenSigTimeout_IC" SG_ 301 Adblue_Stat 1050;
BA_ "GenSigSNA" SG_ 301 Adblue_Stat "3Fh";
BA_ "GenSigCycleTime" SG_ 301 Adblue_Stat 100;
BA_ "FlexKomSigStartValue" SG_ 301 Adblue_Stat "00FF0000h";
BA_ "FlexKomSigStartPos" SG_ 301 Adblue_Stat 39;
BA_ "FlexKomSigName" SG_ 301 Adblue_Stat "AdblueDispRq";
BA_ "FlexKomSigLaenge" SG_ 301 Adblue_Stat 32;
BA_ "FlexKomSID" SG_ 301 Adblue_Stat 1436;
BA_ "FlexKomIsMotorola" SG_ 301 Adblue_Stat 1;
BA_ "FlexKomComment" SG_ 301 Adblue_Stat "Adblue display request";
BA_ "GenSigTimeout_IC" SG_ 301 DEF_LOW 1050;
BA_ "GenSigSNA" SG_ 301 DEF_LOW "3h";
BA_ "GenSigCycleTime" SG_ 301 DEF_LOW 100;
BA_ "FlexKomSigStartValue" SG_ 301 DEF_LOW "000Fh";
BA_ "FlexKomSigStartPos" SG_ 301 DEF_LOW 7;
BA_ "FlexKomSigName" SG_ 301 DEF_LOW "DEF_DPF_Pkt";
BA_ "FlexKomSigLaenge" SG_ 301 DEF_LOW 16;
BA_ "FlexKomSID" SG_ 301 DEF_LOW 1726;
BA_ "FlexKomIsMotorola" SG_ 301 DEF_LOW 1;
BA_ "FlexKomComment" SG_ 301 DEF_LOW "Exhaust fuel and particulate filter packet";
BA_ "GenSigTimeout_IC" SG_ 301 ECM_HMI_Timer_RQ 1050;
BA_ "GenSigSNA" SG_ 301 ECM_HMI_Timer_RQ "7h";
BA_ "GenSigCycleTime" SG_ 301 ECM_HMI_Timer_RQ 100;
BA_ "FlexKomSigStartValue" SG_ 301 ECM_HMI_Timer_RQ "00h";
BA_ "FlexKomSigStartPos" SG_ 301 ECM_HMI_Timer_RQ 18;
BA_ "FlexKomSigName" SG_ 301 ECM_HMI_Timer_RQ "ECM_HMI_Timer_RQ";
BA_ "FlexKomSigLaenge" SG_ 301 ECM_HMI_Timer_RQ 3;
BA_ "FlexKomSID" SG_ 301 ECM_HMI_Timer_RQ 1727;
BA_ "FlexKomIsMotorola" SG_ 301 ECM_HMI_Timer_RQ 1;
BA_ "FlexKomComment" SG_ 301 ECM_HMI_Timer_RQ "DEF and DPF warning re-launch timer request";
BA_ "GenSigTimeout_IC" SG_ 301 EngChmRq 1050;
BA_ "GenSigSNA" SG_ 301 EngChmRq "0h";
BA_ "GenSigCycleTime" SG_ 301 EngChmRq 100;
BA_ "FlexKomSigStartValue" SG_ 301 EngChmRq "00h";
BA_ "FlexKomSigStartPos" SG_ 301 EngChmRq 15;
BA_ "FlexKomSigName" SG_ 301 EngChmRq "EngChmRq";
BA_ "FlexKomSigLaenge" SG_ 301 EngChmRq 1;
BA_ "FlexKomSID" SG_ 301 EngChmRq 1864;
BA_ "FlexKomIsMotorola" SG_ 301 EngChmRq 1;
BA_ "FlexKomComment" SG_ 301 EngChmRq "Engine chime request";
BA_ "GenSigTimeout_IC" SG_ 301 PFW_Stat 1050;
BA_ "GenSigSNA" SG_ 301 PFW_Stat "Fh";
BA_ "GenSigCycleTime" SG_ 301 PFW_Stat 100;
BA_ "FlexKomSigStartValue" SG_ 301 PFW_Stat "000Fh";
BA_ "FlexKomSigStartPos" SG_ 301 PFW_Stat 7;
BA_ "FlexKomSigName" SG_ 301 PFW_Stat "DEF_DPF_Pkt";
BA_ "FlexKomSigLaenge" SG_ 301 PFW_Stat 16;
BA_ "FlexKomSID" SG_ 301 PFW_Stat 1726;
BA_ "FlexKomIsMotorola" SG_ 301 PFW_Stat 1;
BA_ "FlexKomComment" SG_ 301 PFW_Stat "Exhaust fuel and particulate filter packet";
BA_ "GenSigSNA" SG_ 301 PF_RgnActv "0h";
BA_ "GenSigCycleTime" SG_ 301 PF_RgnActv 100;
BA_ "FlexKomSigStartValue" SG_ 301 PF_RgnActv "00h";
BA_ "FlexKomSigStartPos" SG_ 301 PF_RgnActv 31;
BA_ "FlexKomSigName" SG_ 301 PF_RgnActv "PF_RgnActv";
BA_ "FlexKomSigLaenge" SG_ 301 PF_RgnActv 1;
BA_ "FlexKomSID" SG_ 301 PF_RgnActv 1643;
BA_ "FlexKomIsMotorola" SG_ 301 PF_RgnActv 1;
BA_ "FlexKomComment" SG_ 301 PF_RgnActv "Particulate filter regeneration active";
BA_ "GenSigSNA" SG_ 301 PTC_REL1_RQ "0h";
BA_ "GenSigCycleTime" SG_ 301 PTC_REL1_RQ 100;
BA_ "FlexKomSigStartValue" SG_ 301 PTC_REL1_RQ "00h";
BA_ "FlexKomSigStartPos" SG_ 301 PTC_REL1_RQ 23;
BA_ "FlexKomSigName" SG_ 301 PTC_REL1_RQ "PTC_REL_RQ";
BA_ "FlexKomSigLaenge" SG_ 301 PTC_REL1_RQ 3;
BA_ "FlexKomSID" SG_ 301 PTC_REL1_RQ 721;
BA_ "FlexKomIsMotorola" SG_ 301 PTC_REL1_RQ 1;
BA_ "FlexKomComment" SG_ 301 PTC_REL1_RQ "PTC relay requests";
BA_ "GenSigSNA" SG_ 301 PTC_REL2_RQ "0h";
BA_ "GenSigCycleTime" SG_ 301 PTC_REL2_RQ 100;
BA_ "FlexKomSigStartValue" SG_ 301 PTC_REL2_RQ "00h";
BA_ "FlexKomSigStartPos" SG_ 301 PTC_REL2_RQ 23;
BA_ "FlexKomSigName" SG_ 301 PTC_REL2_RQ "PTC_REL_RQ";
BA_ "FlexKomSigLaenge" SG_ 301 PTC_REL2_RQ 3;
BA_ "FlexKomSID" SG_ 301 PTC_REL2_RQ 721;
BA_ "FlexKomIsMotorola" SG_ 301 PTC_REL2_RQ 1;
BA_ "FlexKomComment" SG_ 301 PTC_REL2_RQ "PTC relay requests";
BA_ "GenSigSNA" SG_ 301 PTC_REL3_RQ "0h";
BA_ "GenSigCycleTime" SG_ 301 PTC_REL3_RQ 100;
BA_ "FlexKomSigStartValue" SG_ 301 PTC_REL3_RQ "00h";
BA_ "FlexKomSigStartPos" SG_ 301 PTC_REL3_RQ 23;
BA_ "FlexKomSigName" SG_ 301 PTC_REL3_RQ "PTC_REL_RQ";
BA_ "FlexKomSigLaenge" SG_ 301 PTC_REL3_RQ 3;
BA_ "FlexKomSID" SG_ 301 PTC_REL3_RQ 721;
BA_ "FlexKomIsMotorola" SG_ 301 PTC_REL3_RQ 1;
BA_ "FlexKomComment" SG_ 301 PTC_REL3_RQ "PTC relay requests";
BA_ "GenSigTimeout_IC" SG_ 301 PrcntCplt 1050;
BA_ "GenSigStartValue" SG_ 301 PrcntCplt 15;
BA_ "GenSigSNA" SG_ 301 PrcntCplt "Fh";
BA_ "GenSigCycleTime" SG_ 301 PrcntCplt 100;
BA_ "FlexKomSigStartValue" SG_ 301 PrcntCplt "000Fh";
BA_ "FlexKomSigStartPos" SG_ 301 PrcntCplt 7;
BA_ "FlexKomSigName" SG_ 301 PrcntCplt "DEF_DPF_Pkt";
BA_ "FlexKomSigLaenge" SG_ 301 PrcntCplt 16;
BA_ "FlexKomSID" SG_ 301 PrcntCplt 1726;
BA_ "FlexKomIsMotorola" SG_ 301 PrcntCplt 1;
BA_ "FlexKomComment" SG_ 301 PrcntCplt "Exhaust fuel and particulate filter packet";
BA_ "GenSigTimeout_IC" SG_ 301 PreHtIndLmp_On_Rq 1050;
BA_ "GenSigTimeout_ETM" SG_ 301 PreHtIndLmp_On_Rq 1050;
BA_ "GenSigSNA" SG_ 301 PreHtIndLmp_On_Rq "0h";
BA_ "GenSigCycleTime" SG_ 301 PreHtIndLmp_On_Rq 100;
BA_ "FlexKomSigStartValue" SG_ 301 PreHtIndLmp_On_Rq "00h";
BA_ "FlexKomSigStartPos" SG_ 301 PreHtIndLmp_On_Rq 19;
BA_ "FlexKomSigName" SG_ 301 PreHtIndLmp_On_Rq "PreHtIndLmp_On_Rq";
BA_ "FlexKomSigLaenge" SG_ 301 PreHtIndLmp_On_Rq 1;
BA_ "FlexKomSID" SG_ 301 PreHtIndLmp_On_Rq 720;
BA_ "FlexKomIsMotorola" SG_ 301 PreHtIndLmp_On_Rq 1;
BA_ "FlexKomComment" SG_ 301 PreHtIndLmp_On_Rq "Request glow-plug (wait to start) lamp";
BA_ "GenSigSNA" SG_ 301 PreHtlmpwithEVIC_On_Rq "3h";
BA_ "GenSigCycleTime" SG_ 301 PreHtlmpwithEVIC_On_Rq 100;
BA_ "FlexKomSigStartValue" SG_ 301 PreHtlmpwithEVIC_On_Rq "00h";
BA_ "FlexKomSigStartPos" SG_ 301 PreHtlmpwithEVIC_On_Rq 3;
BA_ "FlexKomSigName" SG_ 301 PreHtlmpwithEVIC_On_Rq "PreHtlmpwithEVIC_On_Rq";
BA_ "FlexKomSigLaenge" SG_ 301 PreHtlmpwithEVIC_On_Rq 2;
BA_ "FlexKomSID" SG_ 301 PreHtlmpwithEVIC_On_Rq 2937;
BA_ "FlexKomIsMotorola" SG_ 301 PreHtlmpwithEVIC_On_Rq 1;
BA_ "FlexKomComment" SG_ 301 PreHtlmpwithEVIC_On_Rq "Request Glow Plug Wait to Start Message and Lamp I";
BA_ "GenSigTimeout_IC" SG_ 301 RemainDistUnt 1050;
BA_ "GenSigSNA" SG_ 301 RemainDistUnt "0h";
BA_ "GenSigCycleTime" SG_ 301 RemainDistUnt 100;
BA_ "FlexKomSigStartValue" SG_ 301 RemainDistUnt "00FF0000h";
BA_ "FlexKomSigStartPos" SG_ 301 RemainDistUnt 39;
BA_ "FlexKomSigName" SG_ 301 RemainDistUnt "AdblueDispRq";
BA_ "FlexKomSigLaenge" SG_ 301 RemainDistUnt 32;
BA_ "FlexKomSID" SG_ 301 RemainDistUnt 1436;
BA_ "FlexKomIsMotorola" SG_ 301 RemainDistUnt 1;
BA_ "FlexKomComment" SG_ 301 RemainDistUnt "Adblue display request";
BA_ "GenSigTimeout_IC" SG_ 301 WtrFuelIndLmp_On_Rq 1050;
BA_ "GenSigTimeout_ETM" SG_ 301 WtrFuelIndLmp_On_Rq 1050;
BA_ "GenSigSNA" SG_ 301 WtrFuelIndLmp_On_Rq "0h";
BA_ "GenSigCycleTime" SG_ 301 WtrFuelIndLmp_On_Rq 100;
BA_ "FlexKomSigStartValue" SG_ 301 WtrFuelIndLmp_On_Rq "00h";
BA_ "FlexKomSigStartPos" SG_ 301 WtrFuelIndLmp_On_Rq 30;
BA_ "FlexKomSigName" SG_ 301 WtrFuelIndLmp_On_Rq "WtrFuelIndLmp_On_Rq";
BA_ "FlexKomSigLaenge" SG_ 301 WtrFuelIndLmp_On_Rq 1;
BA_ "FlexKomSID" SG_ 301 WtrFuelIndLmp_On_Rq 1109;
BA_ "FlexKomIsMotorola" SG_ 301 WtrFuelIndLmp_On_Rq 1;
BA_ "FlexKomComment" SG_ 301 WtrFuelIndLmp_On_Rq "Request water in fuel lamp (diesel only)";
BA_ "GenSigTimeout_IC" SG_ 337 TrboBstPress 1050;
BA_ "GenSigSNA" SG_ 337 TrboBstPress "FFh";
BA_ "GenSigCycleTime" SG_ 337 TrboBstPress 100;
BA_ "FlexKomSigStartValue" SG_ 337 TrboBstPress "00h";
BA_ "FlexKomSigStartPos" SG_ 337 TrboBstPress 55;
BA_ "FlexKomSigName" SG_ 337 TrboBstPress "TrboBstPress";
BA_ "FlexKomSigLaenge" SG_ 337 TrboBstPress 8;
BA_ "FlexKomSID" SG_ 337 TrboBstPress 1666;
BA_ "FlexKomIsMotorola" SG_ 337 TrboBstPress 1;
BA_ "FlexKomComment" SG_ 337 TrboBstPress "Turbo boost pressure";
BA_ "GenSigTimeout_CBC" SG_ 39 ANL_LFT 105;
BA_ "GenSigSNA" SG_ 39 ANL_LFT "0h";
BA_ "GenSigCycleTime" SG_ 39 ANL_LFT 10;
BA_ "FlexKomSigStartValue" SG_ 39 ANL_LFT "9FFF1FFF1FFF00FFh";
BA_ "FlexKomSigStartPos" SG_ 39 ANL_LFT 7;
BA_ "FlexKomSigName" SG_ 39 ANL_LFT "ECM_ENG_TRQ_Pkt";
BA_ "FlexKomSigLaenge" SG_ 39 ANL_LFT 64;
BA_ "FlexKomSID" SG_ 39 ANL_LFT 1853;
BA_ "FlexKomIsMotorola" SG_ 39 ANL_LFT 1;
BA_ "FlexKomComment" SG_ 39 ANL_LFT "ECM_ENG_TRQ packet";
BA_ "GenSigStartValue" SG_ 39 CRC_ECM_ENG_TRQ 255;
BA_ "GenSigSNA" SG_ 39 CRC_ECM_ENG_TRQ "FFh";
BA_ "GenSigCycleTime" SG_ 39 CRC_ECM_ENG_TRQ 10;
BA_ "FlexKomSigStartValue" SG_ 39 CRC_ECM_ENG_TRQ "9FFF1FFF1FFF00FFh";
BA_ "FlexKomSigStartPos" SG_ 39 CRC_ECM_ENG_TRQ 7;
BA_ "FlexKomSigName" SG_ 39 CRC_ECM_ENG_TRQ "ECM_ENG_TRQ_Pkt";
BA_ "FlexKomSigLaenge" SG_ 39 CRC_ECM_ENG_TRQ 64;
BA_ "FlexKomSID" SG_ 39 CRC_ECM_ENG_TRQ 1853;
BA_ "FlexKomIsMotorola" SG_ 39 CRC_ECM_ENG_TRQ 1;
BA_ "FlexKomComment" SG_ 39 CRC_ECM_ENG_TRQ "ECM_ENG_TRQ packet";
BA_ "GenSigSNA" SG_ 39 CYL_CUT_POSS "0h";
BA_ "GenSigCycleTime" SG_ 39 CYL_CUT_POSS 10;
BA_ "FlexKomSigStartValue" SG_ 39 CYL_CUT_POSS "9FFF1FFF1FFF00FFh";
BA_ "FlexKomSigStartPos" SG_ 39 CYL_CUT_POSS 7;
BA_ "FlexKomSigName" SG_ 39 CYL_CUT_POSS "ECM_ENG_TRQ_Pkt";
BA_ "FlexKomSigLaenge" SG_ 39 CYL_CUT_POSS 64;
BA_ "FlexKomSID" SG_ 39 CYL_CUT_POSS 1853;
BA_ "FlexKomIsMotorola" SG_ 39 CYL_CUT_POSS 1;
BA_ "FlexKomComment" SG_ 39 CYL_CUT_POSS "ECM_ENG_TRQ packet";
BA_ "GenSigTimeout_ORC" SG_ 39 ClutchInterLk 35;
BA_ "GenSigTimeout_DTCM" SG_ 39 ClutchInterLk 105;
BA_ "GenSigStartValue" SG_ 39 ClutchInterLk 1;
BA_ "GenSigSNA" SG_ 39 ClutchInterLk "1h";
BA_ "GenSigCycleTime" SG_ 39 ClutchInterLk 10;
BA_ "FlexKomSigStartValue" SG_ 39 ClutchInterLk "9FFF1FFF1FFF00FFh";
BA_ "FlexKomSigStartPos" SG_ 39 ClutchInterLk 7;
BA_ "FlexKomSigName" SG_ 39 ClutchInterLk "ECM_ENG_TRQ_Pkt";
BA_ "FlexKomSigLaenge" SG_ 39 ClutchInterLk 64;
BA_ "FlexKomSID" SG_ 39 ClutchInterLk 1853;
BA_ "FlexKomIsMotorola" SG_ 39 ClutchInterLk 1;
BA_ "FlexKomComment" SG_ 39 ClutchInterLk "ECM_ENG_TRQ packet";
BA_ "GenSigTimeout_ORC" SG_ 39 Clutch_Disengg 35;
BA_ "GenSigSNA" SG_ 39 Clutch_Disengg "0h";
BA_ "GenSigCycleTime" SG_ 39 Clutch_Disengg 10;
BA_ "FlexKomSigStartValue" SG_ 39 Clutch_Disengg "9FFF1FFF1FFF00FFh";
BA_ "FlexKomSigStartPos" SG_ 39 Clutch_Disengg 7;
BA_ "FlexKomSigName" SG_ 39 Clutch_Disengg "ECM_ENG_TRQ_Pkt";
BA_ "FlexKomSigLaenge" SG_ 39 Clutch_Disengg 64;
BA_ "FlexKomSID" SG_ 39 Clutch_Disengg 1853;
BA_ "FlexKomIsMotorola" SG_ 39 Clutch_Disengg 1;
BA_ "FlexKomComment" SG_ 39 Clutch_Disengg "ECM_ENG_TRQ packet";
BA_ "GenSigSNA" SG_ 39 ESS_ReqShiftPark "0h";
BA_ "GenSigCycleTime" SG_ 39 ESS_ReqShiftPark 10;
BA_ "FlexKomSigStartValue" SG_ 39 ESS_ReqShiftPark "9FFF1FFF1FFF00FFh";
BA_ "FlexKomSigStartPos" SG_ 39 ESS_ReqShiftPark 7;
BA_ "FlexKomSigName" SG_ 39 ESS_ReqShiftPark "ECM_ENG_TRQ_Pkt";
BA_ "FlexKomSigLaenge" SG_ 39 ESS_ReqShiftPark 64;
BA_ "FlexKomSID" SG_ 39 ESS_ReqShiftPark 1853;
BA_ "FlexKomIsMotorola" SG_ 39 ESS_ReqShiftPark 1;
BA_ "FlexKomComment" SG_ 39 ESS_ReqShiftPark "ECM_ENG_TRQ packet";
BA_ "GenSigTimeout_IC" SG_ 39 EngTrqMax 105;
BA_ "GenSigStartValue" SG_ 39 EngTrqMax 8191;
BA_ "GenSigSNA" SG_ 39 EngTrqMax "1FFFh";
BA_ "GenSigCycleTime" SG_ 39 EngTrqMax 10;
BA_ "FlexKomSigStartValue" SG_ 39 EngTrqMax "9FFF1FFF1FFF00FFh";
BA_ "FlexKomSigStartPos" SG_ 39 EngTrqMax 7;
BA_ "FlexKomSigName" SG_ 39 EngTrqMax "ECM_ENG_TRQ_Pkt";
BA_ "FlexKomSigLaenge" SG_ 39 EngTrqMax 64;
BA_ "FlexKomSID" SG_ 39 EngTrqMax 1853;
BA_ "FlexKomIsMotorola" SG_ 39 EngTrqMax 1;
BA_ "FlexKomComment" SG_ 39 EngTrqMax "ECM_ENG_TRQ packet";
BA_ "GenSigTimeout_IC" SG_ 39 EngTrqMin 105;
BA_ "GenSigStartValue" SG_ 39 EngTrqMin 8191;
BA_ "GenSigSNA" SG_ 39 EngTrqMin "1FFFh";
BA_ "GenSigCycleTime" SG_ 39 EngTrqMin 10;
BA_ "FlexKomSigStartValue" SG_ 39 EngTrqMin "9FFF1FFF1FFF00FFh";
BA_ "FlexKomSigStartPos" SG_ 39 EngTrqMin 7;
BA_ "FlexKomSigName" SG_ 39 EngTrqMin "ECM_ENG_TRQ_Pkt";
BA_ "FlexKomSigLaenge" SG_ 39 EngTrqMin 64;
BA_ "FlexKomSID" SG_ 39 EngTrqMin 1853;
BA_ "FlexKomIsMotorola" SG_ 39 EngTrqMin 1;
BA_ "FlexKomComment" SG_ 39 EngTrqMin "ECM_ENG_TRQ packet";
BA_ "RID" SG_ 39 FullOFC_Actv "1822";
BA_ "GenSigSNA" SG_ 39 FullOFC_Actv "0h";
BA_ "GenSigCycleTime" SG_ 39 FullOFC_Actv 10;
BA_ "FlexKomSigStartValue" SG_ 39 FullOFC_Actv "9FFF1FFF1FFF00FFh";
BA_ "FlexKomSigStartPos" SG_ 39 FullOFC_Actv 7;
BA_ "FlexKomSigName" SG_ 39 FullOFC_Actv "ECM_ENG_TRQ_Pkt";
BA_ "FlexKomSigLaenge" SG_ 39 FullOFC_Actv 64;
BA_ "FlexKomSID" SG_ 39 FullOFC_Actv 1853;
BA_ "FlexKomIsMotorola" SG_ 39 FullOFC_Actv 1;
BA_ "FlexKomComment" SG_ 39 FullOFC_Actv "ECM_ENG_TRQ packet";
BA_ "GenSigSNA" SG_ 39 MC_ECM_ENG_TRQ "0h";
BA_ "GenSigCycleTime" SG_ 39 MC_ECM_ENG_TRQ 10;
BA_ "FlexKomSigStartValue" SG_ 39 MC_ECM_ENG_TRQ "9FFF1FFF1FFF00FFh";
BA_ "FlexKomSigStartPos" SG_ 39 MC_ECM_ENG_TRQ 7;
BA_ "FlexKomSigName" SG_ 39 MC_ECM_ENG_TRQ "ECM_ENG_TRQ_Pkt";
BA_ "FlexKomSigLaenge" SG_ 39 MC_ECM_ENG_TRQ 64;
BA_ "FlexKomSID" SG_ 39 MC_ECM_ENG_TRQ 1853;
BA_ "FlexKomIsMotorola" SG_ 39 MC_ECM_ENG_TRQ 1;
BA_ "FlexKomComment" SG_ 39 MC_ECM_ENG_TRQ "ECM_ENG_TRQ packet";
BA_ "RID" SG_ 39 MdsAct "2097";
BA_ "GenSigTimeout_IC" SG_ 39 MdsAct 105;
BA_ "GenSigSNA" SG_ 39 MdsAct "0h";
BA_ "GenSigCycleTime" SG_ 39 MdsAct 10;
BA_ "FlexKomSigStartValue" SG_ 39 MdsAct "9FFF1FFF1FFF00FFh";
BA_ "FlexKomSigStartPos" SG_ 39 MdsAct 7;
BA_ "FlexKomSigName" SG_ 39 MdsAct "ECM_ENG_TRQ_Pkt";
BA_ "FlexKomSigLaenge" SG_ 39 MdsAct 64;
BA_ "FlexKomSID" SG_ 39 MdsAct 1853;
BA_ "FlexKomIsMotorola" SG_ 39 MdsAct 1;
BA_ "FlexKomComment" SG_ 39 MdsAct "ECM_ENG_TRQ packet";
BA_ "GenSigSNA" SG_ 39 StartRelayBCMCmd "0h";
BA_ "GenSigCycleTime" SG_ 39 StartRelayBCMCmd 10;
BA_ "FlexKomSigStartValue" SG_ 39 StartRelayBCMCmd "9FFF1FFF1FFF00FFh";
BA_ "FlexKomSigStartPos" SG_ 39 StartRelayBCMCmd 7;
BA_ "FlexKomSigName" SG_ 39 StartRelayBCMCmd "ECM_ENG_TRQ_Pkt";
BA_ "FlexKomSigLaenge" SG_ 39 StartRelayBCMCmd 64;
BA_ "FlexKomSID" SG_ 39 StartRelayBCMCmd 1853;
BA_ "FlexKomIsMotorola" SG_ 39 StartRelayBCMCmd 1;
BA_ "FlexKomComment" SG_ 39 StartRelayBCMCmd "ECM_ENG_TRQ packet";
BA_ "GenSigTimeout_IC" SG_ 181 EngRPM_Tach 210;
BA_ "GenSigStartValue" SG_ 181 EngRPM_Tach 65535;
BA_ "GenSigSNA" SG_ 181 EngRPM_Tach "FFFFh";
BA_ "GenSigCycleTime" SG_ 181 EngRPM_Tach 20;
BA_ "FlexKomSigStartValue" SG_ 181 EngRPM_Tach "0000FFFF03AA00FFh";
BA_ "FlexKomSigStartPos" SG_ 181 EngRPM_Tach 7;
BA_ "FlexKomSigName" SG_ 181 EngRPM_Tach "ECM_ENG_TRQ2_PKT";
BA_ "FlexKomSigLaenge" SG_ 181 EngRPM_Tach 64;
BA_ "FlexKomSID" SG_ 181 EngRPM_Tach 2773;
BA_ "FlexKomIsMotorola" SG_ 181 EngRPM_Tach 1;
BA_ "FlexKomComment" SG_ 181 EngRPM_Tach "ECM_ENG_TRQ2_PKT";
BA_ "GenSigStartValue" SG_ 181 EngineStaticTorque 938;
BA_ "GenSigSNA" SG_ 181 EngineStaticTorque "FFFh";
BA_ "GenSigCycleTime" SG_ 181 EngineStaticTorque 20;
BA_ "FlexKomSigStartValue" SG_ 181 EngineStaticTorque "0000FFFF03AA00FFh";
BA_ "FlexKomSigStartPos" SG_ 181 EngineStaticTorque 7;
BA_ "FlexKomSigName" SG_ 181 EngineStaticTorque "ECM_ENG_TRQ2_PKT";
BA_ "FlexKomSigLaenge" SG_ 181 EngineStaticTorque 64;
BA_ "FlexKomSID" SG_ 181 EngineStaticTorque 2773;
BA_ "FlexKomIsMotorola" SG_ 181 EngineStaticTorque 1;
BA_ "FlexKomComment" SG_ 181 EngineStaticTorque "ECM_ENG_TRQ2_PKT";
BA_ "GenSigSNA" SG_ 181 EngineStaticTorqueV "0h";
BA_ "GenSigCycleTime" SG_ 181 EngineStaticTorqueV 20;
BA_ "FlexKomSigStartValue" SG_ 181 EngineStaticTorqueV "0000FFFF03AA00FFh";
BA_ "FlexKomSigStartPos" SG_ 181 EngineStaticTorqueV 7;
BA_ "FlexKomSigName" SG_ 181 EngineStaticTorqueV "ECM_ENG_TRQ2_PKT";
BA_ "FlexKomSigLaenge" SG_ 181 EngineStaticTorqueV 64;
BA_ "FlexKomSID" SG_ 181 EngineStaticTorqueV 2773;
BA_ "FlexKomIsMotorola" SG_ 181 EngineStaticTorqueV 1;
BA_ "FlexKomComment" SG_ 181 EngineStaticTorqueV "ECM_ENG_TRQ2_PKT";
BA_ "GenSigStartValue" SG_ 125 EngTrqMaxCorrFctr 255;
BA_ "GenSigSNA" SG_ 125 EngTrqMaxCorrFctr "FFh";
BA_ "GenSigCycleTime" SG_ 125 EngTrqMaxCorrFctr 20;
BA_ "FlexKomSigStartValue" SG_ 125 EngTrqMaxCorrFctr "FFh";
BA_ "FlexKomSigStartPos" SG_ 125 EngTrqMaxCorrFctr 15;
BA_ "FlexKomSigName" SG_ 125 EngTrqMaxCorrFctr "EngTrqMaxCorrFctr";
BA_ "FlexKomSigLaenge" SG_ 125 EngTrqMaxCorrFctr 8;
BA_ "FlexKomSID" SG_ 125 EngTrqMaxCorrFctr 1242;
BA_ "FlexKomIsMotorola" SG_ 125 EngTrqMaxCorrFctr 1;
BA_ "FlexKomComment" SG_ 125 EngTrqMaxCorrFctr "Factor of reduction from max. torque";
BA_ "GenSigSNA" SG_ 125 GrMax_Rq_ECM "0h";
BA_ "GenSigCycleTime" SG_ 125 GrMax_Rq_ECM 20;
BA_ "FlexKomSigStartValue" SG_ 125 GrMax_Rq_ECM "00h";
BA_ "FlexKomSigStartPos" SG_ 125 GrMax_Rq_ECM 21;
BA_ "FlexKomSigName" SG_ 125 GrMax_Rq_ECM "ECM_Gear";
BA_ "FlexKomSigLaenge" SG_ 125 GrMax_Rq_ECM 6;
BA_ "FlexKomSID" SG_ 125 GrMax_Rq_ECM 1243;
BA_ "FlexKomIsMotorola" SG_ 125 GrMax_Rq_ECM 1;
BA_ "FlexKomComment" SG_ 125 GrMax_Rq_ECM "Target gear upper and lower limit";
BA_ "GenSigSNA" SG_ 125 GrMin_Rq_ECM "0h";
BA_ "GenSigCycleTime" SG_ 125 GrMin_Rq_ECM 20;
BA_ "FlexKomSigStartValue" SG_ 125 GrMin_Rq_ECM "00h";
BA_ "FlexKomSigStartPos" SG_ 125 GrMin_Rq_ECM 21;
BA_ "FlexKomSigName" SG_ 125 GrMin_Rq_ECM "ECM_Gear";
BA_ "FlexKomSigLaenge" SG_ 125 GrMin_Rq_ECM 6;
BA_ "FlexKomSID" SG_ 125 GrMin_Rq_ECM 1243;
BA_ "FlexKomIsMotorola" SG_ 125 GrMin_Rq_ECM 1;
BA_ "FlexKomComment" SG_ 125 GrMin_Rq_ECM "Target gear upper and lower limit";
BA_ "GenSigSNA" SG_ 125 KickDnSw_Psd "0h";
BA_ "GenSigCycleTime" SG_ 125 KickDnSw_Psd 20;
BA_ "FlexKomSigStartValue" SG_ 125 KickDnSw_Psd "00h";
BA_ "FlexKomSigStartPos" SG_ 125 KickDnSw_Psd 3;
BA_ "FlexKomSigName" SG_ 125 KickDnSw_Psd "KickDnSw_Psd";
BA_ "FlexKomSigLaenge" SG_ 125 KickDnSw_Psd 1;
BA_ "FlexKomSID" SG_ 125 KickDnSw_Psd 1238;
BA_ "FlexKomIsMotorola" SG_ 125 KickDnSw_Psd 1;
BA_ "FlexKomComment" SG_ 125 KickDnSw_Psd "kick-down (change-over scenario open!)";
BA_ "GenSigStartValue" SG_ 125 NMOTS 65535;
BA_ "GenSigSNA" SG_ 125 NMOTS "FFFFh";
BA_ "GenSigCycleTime" SG_ 125 NMOTS 20;
BA_ "FlexKomSigStartValue" SG_ 125 NMOTS "FFFFh";
BA_ "FlexKomSigStartPos" SG_ 125 NMOTS 39;
BA_ "FlexKomSigName" SG_ 125 NMOTS "NMOTS";
BA_ "FlexKomSigLaenge" SG_ 125 NMOTS 16;
BA_ "FlexKomSID" SG_ 125 NMOTS 1248;
BA_ "FlexKomIsMotorola" SG_ 125 NMOTS 1;
BA_ "FlexKomComment" SG_ 125 NMOTS "Target idle speed";
BA_ "GenSigSNA" SG_ 125 TxAC_EMCC_rq "0h";
BA_ "GenSigCycleTime" SG_ 125 TxAC_EMCC_rq 20;
BA_ "FlexKomSigStartValue" SG_ 125 TxAC_EMCC_rq "00h";
BA_ "FlexKomSigStartPos" SG_ 125 TxAC_EMCC_rq 5;
BA_ "FlexKomSigName" SG_ 125 TxAC_EMCC_rq "TxAC_EMCC_rq";
BA_ "FlexKomSigLaenge" SG_ 125 TxAC_EMCC_rq 1;
BA_ "FlexKomSID" SG_ 125 TxAC_EMCC_rq 1240;
BA_ "FlexKomIsMotorola" SG_ 125 TxAC_EMCC_rq 1;
BA_ "FlexKomComment" SG_ 125 TxAC_EMCC_rq "Transmission  AC converter clutch slip request; [1";
BA_ "RID" SG_ 317 ChkFuelCap "6545";
BA_ "GenSigTimeout_TBM" SG_ 317 ChkFuelCap 1050;
BA_ "GenSigTimeout_IC" SG_ 317 ChkFuelCap 1050;
BA_ "GenSigTimeout_ETM" SG_ 317 ChkFuelCap 1050;
BA_ "GenSigSNA" SG_ 317 ChkFuelCap "0h";
BA_ "GenSigCycleTime" SG_ 317 ChkFuelCap 100;
BA_ "FlexKomSigStartValue" SG_ 317 ChkFuelCap "00h";
BA_ "FlexKomSigStartPos" SG_ 317 ChkFuelCap 15;
BA_ "FlexKomSigName" SG_ 317 ChkFuelCap "ChkFuelCap";
BA_ "FlexKomSigLaenge" SG_ 317 ChkFuelCap 1;
BA_ "FlexKomSID" SG_ 317 ChkFuelCap 1082;
BA_ "FlexKomIsMotorola" SG_ 317 ChkFuelCap 1;
BA_ "FlexKomComment" SG_ 317 ChkFuelCap "Check fuel cap";
BA_ "GenSigTimeout_IC" SG_ 317 DefFuelEcon 1050;
BA_ "GenSigStartValue" SG_ 317 DefFuelEcon 255;
BA_ "GenSigSNA" SG_ 317 DefFuelEcon "FFh";
BA_ "GenSigCycleTime" SG_ 317 DefFuelEcon 100;
BA_ "FlexKomSigStartValue" SG_ 317 DefFuelEcon "FFh";
BA_ "FlexKomSigStartPos" SG_ 317 DefFuelEcon 55;
BA_ "FlexKomSigName" SG_ 317 DefFuelEcon "DefFuelEcon";
BA_ "FlexKomSigLaenge" SG_ 317 DefFuelEcon 8;
BA_ "FlexKomSID" SG_ 317 DefFuelEcon 709;
BA_ "FlexKomIsMotorola" SG_ 317 DefFuelEcon 1;
BA_ "FlexKomComment" SG_ 317 DefFuelEcon "Default fuel economy";
BA_ "RID" SG_ 317 ETC_IND_LMP "6544";
BA_ "GenSigTimeout_TBM" SG_ 317 ETC_IND_LMP 1050;
BA_ "GenSigTimeout_IC" SG_ 317 ETC_IND_LMP 1050;
BA_ "GenSigTimeout_ETM" SG_ 317 ETC_IND_LMP 1050;
BA_ "GenSigSNA" SG_ 317 ETC_IND_LMP "3h";
BA_ "GenSigCycleTime" SG_ 317 ETC_IND_LMP 100;
BA_ "FlexKomSigStartValue" SG_ 317 ETC_IND_LMP "00h";
BA_ "FlexKomSigStartPos" SG_ 317 ETC_IND_LMP 3;
BA_ "FlexKomSigName" SG_ 317 ETC_IND_LMP "ETC_IND_LMP";
BA_ "FlexKomSigLaenge" SG_ 317 ETC_IND_LMP 2;
BA_ "FlexKomSID" SG_ 317 ETC_IND_LMP 712;
BA_ "FlexKomIsMotorola" SG_ 317 ETC_IND_LMP 1;
BA_ "FlexKomComment" SG_ 317 ETC_IND_LMP "ETC faulty, indicator lamp request";
BA_ "RID" SG_ 317 EngOilIndLmp_On_Rq "6552";
BA_ "GenSigTimeout_TBM" SG_ 317 EngOilIndLmp_On_Rq 1050;
BA_ "GenSigTimeout_IC" SG_ 317 EngOilIndLmp_On_Rq 1050;
BA_ "GenSigTimeout_ETM" SG_ 317 EngOilIndLmp_On_Rq 1050;
BA_ "GenSigSNA" SG_ 317 EngOilIndLmp_On_Rq "1h";
BA_ "GenSigCycleTime" SG_ 317 EngOilIndLmp_On_Rq 100;
BA_ "FlexKomSigStartValue" SG_ 317 EngOilIndLmp_On_Rq "00h";
BA_ "FlexKomSigStartPos" SG_ 317 EngOilIndLmp_On_Rq 10;
BA_ "FlexKomSigName" SG_ 317 EngOilIndLmp_On_Rq "EngOilIndLmp_On_Rq";
BA_ "FlexKomSigLaenge" SG_ 317 EngOilIndLmp_On_Rq 1;
BA_ "FlexKomSID" SG_ 317 EngOilIndLmp_On_Rq 1080;
BA_ "FlexKomIsMotorola" SG_ 317 EngOilIndLmp_On_Rq 1;
BA_ "FlexKomComment" SG_ 317 EngOilIndLmp_On_Rq "Request oil level/oil pressure indicator lamp";
BA_ "RID" SG_ 317 EngOilTemp "1200";
BA_ "GenSigTimeout_TBM" SG_ 317 EngOilTemp 1050;
BA_ "GenSigTimeout_IC" SG_ 317 EngOilTemp 1050;
BA_ "GenSigTimeout_CBC" SG_ 317 EngOilTemp 1050;
BA_ "GenSigStartValue" SG_ 317 EngOilTemp 255;
BA_ "GenSigSNA" SG_ 317 EngOilTemp "FFh";
BA_ "GenSigCycleTime" SG_ 317 EngOilTemp 100;
BA_ "FlexKomSigStartValue" SG_ 317 EngOilTemp "FFh";
BA_ "FlexKomSigStartPos" SG_ 317 EngOilTemp 31;
BA_ "FlexKomSigName" SG_ 317 EngOilTemp "EngOilTemp";
BA_ "FlexKomSigLaenge" SG_ 317 EngOilTemp 8;
BA_ "FlexKomSID" SG_ 317 EngOilTemp 440;
BA_ "FlexKomIsMotorola" SG_ 317 EngOilTemp 1;
BA_ "FlexKomComment" SG_ 317 EngOilTemp "Oil temperature";
BA_ "RID" SG_ 317 EngRun_Stat "2093";
BA_ "GenSigTimeout_IC" SG_ 317 EngRun_Stat 1050;
BA_ "GenSigTimeout_DTCM" SG_ 317 EngRun_Stat 1050;
BA_ "GenSigTimeout_CBC" SG_ 317 EngRun_Stat 1050;
BA_ "GenSigStartValue" SG_ 317 EngRun_Stat 7;
BA_ "GenSigSNA" SG_ 317 EngRun_Stat "7h";
BA_ "GenSigCycleTime" SG_ 317 EngRun_Stat 100;
BA_ "FlexKomSigStartValue" SG_ 317 EngRun_Stat "07h";
BA_ "FlexKomSigStartPos" SG_ 317 EngRun_Stat 58;
BA_ "FlexKomSigName" SG_ 317 EngRun_Stat "EngRun_Stat";
BA_ "FlexKomSigLaenge" SG_ 317 EngRun_Stat 3;
BA_ "FlexKomSID" SG_ 317 EngRun_Stat 1081;
BA_ "FlexKomIsMotorola" SG_ 317 EngRun_Stat 1;
BA_ "FlexKomComment" SG_ 317 EngRun_Stat "Engine running state";
BA_ "RID" SG_ 317 FuelCons "1818";
BA_ "GenSigTimeout_IC" SG_ 317 FuelCons 1050;
BA_ "GenSigTimeout_CBC" SG_ 317 FuelCons 1050;
BA_ "GenSigStartValue" SG_ 317 FuelCons 65535;
BA_ "GenSigSNA" SG_ 317 FuelCons "FFFFh";
BA_ "GenSigCycleTime" SG_ 317 FuelCons 100;
BA_ "FlexKomSigStartValue" SG_ 317 FuelCons "FFFFh";
BA_ "FlexKomSigStartPos" SG_ 317 FuelCons 39;
BA_ "FlexKomSigName" SG_ 317 FuelCons "FuelCons";
BA_ "FlexKomSigLaenge" SG_ 317 FuelCons 16;
BA_ "FlexKomSID" SG_ 317 FuelCons 443;
BA_ "FlexKomIsMotorola" SG_ 317 FuelCons 1;
BA_ "FlexKomComment" SG_ 317 FuelCons "Fuel consumption";
BA_ "GenSigTimeout_ORC" SG_ 317 MIL_IND_BLINK 350;
BA_ "GenSigTimeout_IC" SG_ 317 MIL_IND_BLINK 1050;
BA_ "GenSigSNA" SG_ 317 MIL_IND_BLINK "0h";
BA_ "GenSigCycleTime" SG_ 317 MIL_IND_BLINK 100;
BA_ "FlexKomSigStartValue" SG_ 317 MIL_IND_BLINK "00h";
BA_ "FlexKomSigStartPos" SG_ 317 MIL_IND_BLINK 1;
BA_ "FlexKomSigName" SG_ 317 MIL_IND_BLINK "MIL_IND_BLINK";
BA_ "FlexKomSigLaenge" SG_ 317 MIL_IND_BLINK 1;
BA_ "FlexKomSID" SG_ 317 MIL_IND_BLINK 713;
BA_ "FlexKomIsMotorola" SG_ 317 MIL_IND_BLINK 1;
BA_ "FlexKomComment" SG_ 317 MIL_IND_BLINK "Request MIL blink (OBD II)";
BA_ "RID" SG_ 317 MIL_OnRq "1210 6543";
BA_ "GenSigTimeout_ORC" SG_ 317 MIL_OnRq 350;
BA_ "GenSigTimeout_IC" SG_ 317 MIL_OnRq 1050;
BA_ "GenSigSNA" SG_ 317 MIL_OnRq "0h";
BA_ "GenSigCycleTime" SG_ 317 MIL_OnRq 100;
BA_ "FlexKomSigStartValue" SG_ 317 MIL_OnRq "00h";
BA_ "FlexKomSigName" SG_ 317 MIL_OnRq "MIL_OnRq";
BA_ "FlexKomSigLaenge" SG_ 317 MIL_OnRq 1;
BA_ "FlexKomSID" SG_ 317 MIL_OnRq 714;
BA_ "FlexKomIsMotorola" SG_ 317 MIL_OnRq 1;
BA_ "FlexKomComment" SG_ 317 MIL_OnRq "MIL on request from the engine";
BA_ "GenSigTimeout_IC" SG_ 317 OIL_IND_LMP_FLSH 1050;
BA_ "GenSigSNA" SG_ 317 OIL_IND_LMP_FLSH "0h";
BA_ "GenSigCycleTime" SG_ 317 OIL_IND_LMP_FLSH 100;
BA_ "FlexKomSigStartValue" SG_ 317 OIL_IND_LMP_FLSH "00h";
BA_ "FlexKomSigStartPos" SG_ 317 OIL_IND_LMP_FLSH 8;
BA_ "FlexKomSigName" SG_ 317 OIL_IND_LMP_FLSH "OIL_IND_LMP_FLSH";
BA_ "FlexKomSigLaenge" SG_ 317 OIL_IND_LMP_FLSH 1;
BA_ "FlexKomSID" SG_ 317 OIL_IND_LMP_FLSH 716;
BA_ "FlexKomIsMotorola" SG_ 317 OIL_IND_LMP_FLSH 1;
BA_ "FlexKomComment" SG_ 317 OIL_IND_LMP_FLSH "Oil indicator lamp flash (for in plant use)";
BA_ "RID" SG_ 317 OIL_PRESS "1183";
BA_ "GenSigTimeout_TBM" SG_ 317 OIL_PRESS 1050;
BA_ "GenSigTimeout_IC" SG_ 317 OIL_PRESS 1050;
BA_ "GenSigTimeout_CBC" SG_ 317 OIL_PRESS 1050;
BA_ "GenSigStartValue" SG_ 317 OIL_PRESS 255;
BA_ "GenSigSNA" SG_ 317 OIL_PRESS "FFh";
BA_ "GenSigCycleTime" SG_ 317 OIL_PRESS 100;
BA_ "FlexKomSigStartValue" SG_ 317 OIL_PRESS "FFh";
BA_ "FlexKomSigStartPos" SG_ 317 OIL_PRESS 23;
BA_ "FlexKomSigName" SG_ 317 OIL_PRESS "OIL_PRESS";
BA_ "FlexKomSigLaenge" SG_ 317 OIL_PRESS 8;
BA_ "FlexKomSID" SG_ 317 OIL_PRESS 717;
BA_ "FlexKomIsMotorola" SG_ 317 OIL_PRESS 1;
BA_ "FlexKomComment" SG_ 317 OIL_PRESS "Oil pressure";
BA_ "GenSigTimeout_IC" SG_ 317 OIL_TEMP_CHM_RQ 1050;
BA_ "GenSigSNA" SG_ 317 OIL_TEMP_CHM_RQ "0h";
BA_ "GenSigCycleTime" SG_ 317 OIL_TEMP_CHM_RQ 100;
BA_ "FlexKomSigStartValue" SG_ 317 OIL_TEMP_CHM_RQ "00h";
BA_ "FlexKomSigStartPos" SG_ 317 OIL_TEMP_CHM_RQ 14;
BA_ "FlexKomSigName" SG_ 317 OIL_TEMP_CHM_RQ "OIL_TEMP_RQ";
BA_ "FlexKomSigLaenge" SG_ 317 OIL_TEMP_CHM_RQ 4;
BA_ "FlexKomSID" SG_ 317 OIL_TEMP_CHM_RQ 718;
BA_ "FlexKomIsMotorola" SG_ 317 OIL_TEMP_CHM_RQ 1;
BA_ "FlexKomComment" SG_ 317 OIL_TEMP_CHM_RQ "Engine oil overtemp. indicator/chime request";
BA_ "RID" SG_ 317 OIL_TEMP_IND_RQ "6551";
BA_ "GenSigTimeout_TBM" SG_ 317 OIL_TEMP_IND_RQ 1050;
BA_ "GenSigTimeout_IC" SG_ 317 OIL_TEMP_IND_RQ 1050;
BA_ "GenSigTimeout_ETM" SG_ 317 OIL_TEMP_IND_RQ 1050;
BA_ "GenSigSNA" SG_ 317 OIL_TEMP_IND_RQ "3h";
BA_ "GenSigCycleTime" SG_ 317 OIL_TEMP_IND_RQ 100;
BA_ "FlexKomSigStartValue" SG_ 317 OIL_TEMP_IND_RQ "00h";
BA_ "FlexKomSigStartPos" SG_ 317 OIL_TEMP_IND_RQ 14;
BA_ "FlexKomSigName" SG_ 317 OIL_TEMP_IND_RQ "OIL_TEMP_RQ";
BA_ "FlexKomSigLaenge" SG_ 317 OIL_TEMP_IND_RQ 4;
BA_ "FlexKomSID" SG_ 317 OIL_TEMP_IND_RQ 718;
BA_ "FlexKomIsMotorola" SG_ 317 OIL_TEMP_IND_RQ 1;
BA_ "FlexKomComment" SG_ 317 OIL_TEMP_IND_RQ "Engine oil overtemp. indicator/chime request";
BA_ "GenSigTimeout_TBM" SG_ 289 AccelPdlPosn_OBD 1050;
BA_ "GenSigSNA" SG_ 289 AccelPdlPosn_OBD "0h";
BA_ "GenSigCycleTime" SG_ 289 AccelPdlPosn_OBD 100;
BA_ "FlexKomSigStartValue" SG_ 289 AccelPdlPosn_OBD "00h";
BA_ "FlexKomSigStartPos" SG_ 289 AccelPdlPosn_OBD 31;
BA_ "FlexKomSigName" SG_ 289 AccelPdlPosn_OBD "AccelPdlPosn_OBD";
BA_ "FlexKomSigLaenge" SG_ 289 AccelPdlPosn_OBD 8;
BA_ "FlexKomSID" SG_ 289 AccelPdlPosn_OBD 1089;
BA_ "FlexKomIsMotorola" SG_ 289 AccelPdlPosn_OBD 1;
BA_ "FlexKomComment" SG_ 289 AccelPdlPosn_OBD "Pedal value for OBD (ISO 15031-5.4 PID 49)";
BA_ "GenSigSNA" SG_ 289 CARB_PERM "0h";
BA_ "GenSigCycleTime" SG_ 289 CARB_PERM 100;
BA_ "FlexKomSigStartValue" SG_ 289 CARB_PERM "00h";
BA_ "FlexKomSigStartPos" SG_ 289 CARB_PERM 3;
BA_ "FlexKomSigName" SG_ 289 CARB_PERM "CARB_PERM";
BA_ "FlexKomSigLaenge" SG_ 289 CARB_PERM 1;
BA_ "FlexKomSID" SG_ 289 CARB_PERM 1258;
BA_ "FlexKomIsMotorola" SG_ 289 CARB_PERM 1;
BA_ "FlexKomComment" SG_ 289 CARB_PERM "CARB permanent fault code drive cycle";
BA_ "GenSigSNA" SG_ 289 CARB_Temp "0h";
BA_ "GenSigCycleTime" SG_ 289 CARB_Temp 100;
BA_ "FlexKomSigStartValue" SG_ 289 CARB_Temp "00h";
BA_ "FlexKomSigName" SG_ 289 CARB_Temp "CARB_Temp";
BA_ "FlexKomSigLaenge" SG_ 289 CARB_Temp 1;
BA_ "FlexKomSID" SG_ 289 CARB_Temp 1261;
BA_ "FlexKomIsMotorola" SG_ 289 CARB_Temp 1;
BA_ "FlexKomComment" SG_ 289 CARB_Temp "CARB warmup criteria is true [1]";
BA_ "GenSigSNA" SG_ 289 ENGINE_RESET "0h";
BA_ "GenSigCycleTime" SG_ 289 ENGINE_RESET 100;
BA_ "FlexKomSigStartValue" SG_ 289 ENGINE_RESET "00h";
BA_ "FlexKomSigStartPos" SG_ 289 ENGINE_RESET 10;
BA_ "FlexKomSigName" SG_ 289 ENGINE_RESET "ECM_SKIM_STAT_PKT";
BA_ "FlexKomSigLaenge" SG_ 289 ENGINE_RESET 3;
BA_ "FlexKomSID" SG_ 289 ENGINE_RESET 429;
BA_ "FlexKomIsMotorola" SG_ 289 ENGINE_RESET 1;
BA_ "FlexKomComment" SG_ 289 ENGINE_RESET "ECM Immobilizer Status Packet";
BA_ "GenSigSNA" SG_ 289 EngLoad_OBD "0h";
BA_ "GenSigCycleTime" SG_ 289 EngLoad_OBD 100;
BA_ "FlexKomSigStartValue" SG_ 289 EngLoad_OBD "00h";
BA_ "FlexKomSigStartPos" SG_ 289 EngLoad_OBD 23;
BA_ "FlexKomSigName" SG_ 289 EngLoad_OBD "EngLoad_OBD";
BA_ "FlexKomSigLaenge" SG_ 289 EngLoad_OBD 8;
BA_ "FlexKomSID" SG_ 289 EngLoad_OBD 1088;
BA_ "FlexKomIsMotorola" SG_ 289 EngLoad_OBD 1;
BA_ "FlexKomComment" SG_ 289 EngLoad_OBD "Load value for OBD (ISO 15031-5.4 PID 4)";
BA_ "GenSigSNA" SG_ 289 IgnCntrTrue "0h";
BA_ "GenSigCycleTime" SG_ 289 IgnCntrTrue 100;
BA_ "FlexKomSigStartValue" SG_ 289 IgnCntrTrue "00h";
BA_ "FlexKomSigStartPos" SG_ 289 IgnCntrTrue 6;
BA_ "FlexKomSigName" SG_ 289 IgnCntrTrue "IgnCntrTrue";
BA_ "FlexKomSigLaenge" SG_ 289 IgnCntrTrue 1;
BA_ "FlexKomSID" SG_ 289 IgnCntrTrue 1255;
BA_ "FlexKomIsMotorola" SG_ 289 IgnCntrTrue 1;
BA_ "FlexKomComment" SG_ 289 IgnCntrTrue "Ignition cycle counter is true [1]";
BA_ "GenSigSNA" SG_ 289 InpICC_Fail "0h";
BA_ "GenSigCycleTime" SG_ 289 InpICC_Fail 100;
BA_ "FlexKomSigStartValue" SG_ 289 InpICC_Fail "00h";
BA_ "FlexKomSigStartPos" SG_ 289 InpICC_Fail 2;
BA_ "FlexKomSigName" SG_ 289 InpICC_Fail "InpICC_Fail";
BA_ "FlexKomSigLaenge" SG_ 289 InpICC_Fail 1;
BA_ "FlexKomSID" SG_ 289 InpICC_Fail 1259;
BA_ "FlexKomIsMotorola" SG_ 289 InpICC_Fail 1;
BA_ "FlexKomComment" SG_ 289 InpICC_Fail "Inputs to the Ign Cycle Cntr are in a Pend or MIL ";
BA_ "GenSigSNA" SG_ 289 Inp_GD_Fail "0h";
BA_ "GenSigCycleTime" SG_ 289 Inp_GD_Fail 100;
BA_ "FlexKomSigStartValue" SG_ 289 Inp_GD_Fail "00h";
BA_ "FlexKomSigStartPos" SG_ 289 Inp_GD_Fail 1;
BA_ "FlexKomSigName" SG_ 289 Inp_GD_Fail "Inp_GD_Fail";
BA_ "FlexKomSigLaenge" SG_ 289 Inp_GD_Fail 1;
BA_ "FlexKomSID" SG_ 289 Inp_GD_Fail 1260;
BA_ "FlexKomIsMotorola" SG_ 289 Inp_GD_Fail 1;
BA_ "FlexKomComment" SG_ 289 Inp_GD_Fail "Inputs to the general denominator are in a pend or";
BA_ "GenSigSNA" SG_ 289 OBD_GnrlDenCond_Stat "0h";
BA_ "GenSigCycleTime" SG_ 289 OBD_GnrlDenCond_Stat 100;
BA_ "FlexKomSigStartValue" SG_ 289 OBD_GnrlDenCond_Stat "00h";
BA_ "FlexKomSigStartPos" SG_ 289 OBD_GnrlDenCond_Stat 5;
BA_ "FlexKomSigName" SG_ 289 OBD_GnrlDenCond_Stat "OBD_GnrlDenCond_Stat";
BA_ "FlexKomSigLaenge" SG_ 289 OBD_GnrlDenCond_Stat 1;
BA_ "FlexKomSID" SG_ 289 OBD_GnrlDenCond_Stat 1256;
BA_ "FlexKomIsMotorola" SG_ 289 OBD_GnrlDenCond_Stat 1;
BA_ "FlexKomComment" SG_ 289 OBD_GnrlDenCond_Stat "General denominator conditions are met [1].";
BA_ "GenSigTimeout_ETM" SG_ 289 RAD_FAN1_STAT 1050;
BA_ "GenSigSNA" SG_ 289 RAD_FAN1_STAT "FFh";
BA_ "GenSigCycleTime" SG_ 289 RAD_FAN1_STAT 100;
BA_ "FlexKomSigStartValue" SG_ 289 RAD_FAN1_STAT "00h";
BA_ "FlexKomSigStartPos" SG_ 289 RAD_FAN1_STAT 39;
BA_ "FlexKomSigName" SG_ 289 RAD_FAN1_STAT "RAD_FAN1_STAT";
BA_ "FlexKomSigLaenge" SG_ 289 RAD_FAN1_STAT 8;
BA_ "FlexKomSID" SG_ 289 RAD_FAN1_STAT 1091;
BA_ "FlexKomIsMotorola" SG_ 289 RAD_FAN1_STAT 1;
BA_ "FlexKomComment" SG_ 289 RAD_FAN1_STAT "Low speed or single radiator fan requested duty cy";
BA_ "GenSigSNA" SG_ 1449 ECU_APPL_AHLM "0h";
BA_ "GenSigSendType" SG_ 1449 ECU_APPL_AHLM 1;
BA_ "FlexKomSigStartValue" SG_ 1449 ECU_APPL_AHLM "0000000000000000h";
BA_ "FlexKomSigStartPos" SG_ 1449 ECU_APPL_AHLM 7;
BA_ "FlexKomSigName" SG_ 1449 ECU_APPL_AHLM "ECU_APPL_AHLM";
BA_ "FlexKomSigLaenge" SG_ 1449 ECU_APPL_AHLM 64;
BA_ "FlexKomSID" SG_ 1449 ECU_APPL_AHLM 339;
BA_ "FlexKomIsMotorola" SG_ 1449 ECU_APPL_AHLM 1;
BA_ "FlexKomComment" SG_ 1449 ECU_APPL_AHLM "ECU to External Application";
BA_ "GenSigSNA" SG_ 1418 ECU_APPL_ASBS "0h";
BA_ "GenSigSendType" SG_ 1418 ECU_APPL_ASBS 1;
BA_ "FlexKomSigStartValue" SG_ 1418 ECU_APPL_ASBS "0000000000000000h";
BA_ "FlexKomSigStartPos" SG_ 1418 ECU_APPL_ASBS 7;
BA_ "FlexKomSigName" SG_ 1418 ECU_APPL_ASBS "ECU_APPL_ASBS";
BA_ "FlexKomSigLaenge" SG_ 1418 ECU_APPL_ASBS 64;
BA_ "FlexKomSID" SG_ 1418 ECU_APPL_ASBS 2625;
BA_ "FlexKomIsMotorola" SG_ 1418 ECU_APPL_ASBS 1;
BA_ "FlexKomComment" SG_ 1418 ECU_APPL_ASBS "ECU to External Application";
BA_ "GenSigSNA" SG_ 1468 ECU_APPL_BSMO "0h";
BA_ "GenSigSendType" SG_ 1468 ECU_APPL_BSMO 1;
BA_ "FlexKomSigStartValue" SG_ 1468 ECU_APPL_BSMO "0000000000000000h";
BA_ "FlexKomSigStartPos" SG_ 1468 ECU_APPL_BSMO 7;
BA_ "FlexKomSigName" SG_ 1468 ECU_APPL_BSMO "ECU_APPL_BSMO";
BA_ "FlexKomSigLaenge" SG_ 1468 ECU_APPL_BSMO 64;
BA_ "FlexKomSID" SG_ 1468 ECU_APPL_BSMO 2283;
BA_ "FlexKomIsMotorola" SG_ 1468 ECU_APPL_BSMO 1;
BA_ "FlexKomComment" SG_ 1468 ECU_APPL_BSMO "ECU to External Application";
BA_ "GenSigSNA" SG_ 1409 ECU_APPL_CBC "0h";
BA_ "GenSigSendType" SG_ 1409 ECU_APPL_CBC 1;
BA_ "FlexKomSigStartValue" SG_ 1409 ECU_APPL_CBC "0000000000000000h";
BA_ "FlexKomSigStartPos" SG_ 1409 ECU_APPL_CBC 7;
BA_ "FlexKomSigName" SG_ 1409 ECU_APPL_CBC "ECU_APPL_CBC";
BA_ "FlexKomSigLaenge" SG_ 1409 ECU_APPL_CBC 64;
BA_ "FlexKomSID" SG_ 1409 ECU_APPL_CBC 344;
BA_ "FlexKomIsMotorola" SG_ 1409 ECU_APPL_CBC 1;
BA_ "FlexKomComment" SG_ 1409 ECU_APPL_CBC "ECU to External Application";
BA_ "GenSigSNA" SG_ 1427 ECU_APPL_DASM "0h";
BA_ "GenSigSendType" SG_ 1427 ECU_APPL_DASM 1;
BA_ "FlexKomSigStartValue" SG_ 1427 ECU_APPL_DASM "0000000000000000h";
BA_ "FlexKomSigStartPos" SG_ 1427 ECU_APPL_DASM 7;
BA_ "FlexKomSigName" SG_ 1427 ECU_APPL_DASM "ECU_APPL_DASM";
BA_ "FlexKomSigLaenge" SG_ 1427 ECU_APPL_DASM 64;
BA_ "FlexKomSID" SG_ 1427 ECU_APPL_DASM 364;
BA_ "FlexKomIsMotorola" SG_ 1427 ECU_APPL_DASM 1;
BA_ "FlexKomComment" SG_ 1427 ECU_APPL_DASM "ECU to External Application";
BA_ "GenSigSNA" SG_ 1425 ECU_APPL_DPDM "0h";
BA_ "GenSigSendType" SG_ 1425 ECU_APPL_DPDM 1;
BA_ "FlexKomSigStartValue" SG_ 1425 ECU_APPL_DPDM "0000000000000000h";
BA_ "FlexKomSigStartPos" SG_ 1425 ECU_APPL_DPDM 7;
BA_ "FlexKomSigName" SG_ 1425 ECU_APPL_DPDM "ECU_APPL_DPDM";
BA_ "FlexKomSigLaenge" SG_ 1425 ECU_APPL_DPDM 64;
BA_ "FlexKomSID" SG_ 1425 ECU_APPL_DPDM 2659;
BA_ "FlexKomIsMotorola" SG_ 1425 ECU_APPL_DPDM 1;
BA_ "FlexKomComment" SG_ 1425 ECU_APPL_DPDM "ECU to External Application";
BA_ "GenSigSNA" SG_ 1419 ECU_APPL_DTCM "0h";
BA_ "GenSigSendType" SG_ 1419 ECU_APPL_DTCM 1;
BA_ "FlexKomSigStartValue" SG_ 1419 ECU_APPL_DTCM "0000000000000000h";
BA_ "FlexKomSigStartPos" SG_ 1419 ECU_APPL_DTCM 7;
BA_ "FlexKomSigName" SG_ 1419 ECU_APPL_DTCM "ECU_APPL_DTCM";
BA_ "FlexKomSigLaenge" SG_ 1419 ECU_APPL_DTCM 64;
BA_ "FlexKomSID" SG_ 1419 ECU_APPL_DTCM 351;
BA_ "FlexKomIsMotorola" SG_ 1419 ECU_APPL_DTCM 1;
BA_ "FlexKomComment" SG_ 1419 ECU_APPL_DTCM "ECU to External Application";
BA_ "GenSigSNA" SG_ 1464 ECU_APPL_ECM "0h";
BA_ "GenSigSendType" SG_ 1464 ECU_APPL_ECM 1;
BA_ "FlexKomSigStartValue" SG_ 1464 ECU_APPL_ECM "0000000000000000h";
BA_ "FlexKomSigStartPos" SG_ 1464 ECU_APPL_ECM 7;
BA_ "FlexKomSigName" SG_ 1464 ECU_APPL_ECM "ECU_APPL_ECM";
BA_ "FlexKomSigLaenge" SG_ 1464 ECU_APPL_ECM 64;
BA_ "FlexKomSID" SG_ 1464 ECU_APPL_ECM 352;
BA_ "FlexKomIsMotorola" SG_ 1464 ECU_APPL_ECM 1;
BA_ "FlexKomComment" SG_ 1464 ECU_APPL_ECM "ECU to External Application";
BA_ "GenSigSNA" SG_ 1434 ECU_APPL_EPS "0h";
BA_ "GenSigSendType" SG_ 1434 ECU_APPL_EPS 1;
BA_ "FlexKomSigStartValue" SG_ 1434 ECU_APPL_EPS "0000000000000000h";
BA_ "FlexKomSigStartPos" SG_ 1434 ECU_APPL_EPS 7;
BA_ "FlexKomSigName" SG_ 1434 ECU_APPL_EPS "ECU_APPL_EPS";
BA_ "FlexKomSigLaenge" SG_ 1434 ECU_APPL_EPS 64;
BA_ "FlexKomSID" SG_ 1434 ECU_APPL_EPS 354;
BA_ "FlexKomIsMotorola" SG_ 1434 ECU_APPL_EPS 1;
BA_ "FlexKomComment" SG_ 1434 ECU_APPL_EPS "ECU to External Application";
BA_ "GenSigSNA" SG_ 1415 ECU_APPL_ESC "0h";
BA_ "GenSigSendType" SG_ 1415 ECU_APPL_ESC 1;
BA_ "FlexKomSigStartValue" SG_ 1415 ECU_APPL_ESC "0000000000000000h";
BA_ "FlexKomSigStartPos" SG_ 1415 ECU_APPL_ESC 7;
BA_ "FlexKomSigName" SG_ 1415 ECU_APPL_ESC "ECU_APPL_ESC";
BA_ "FlexKomSigLaenge" SG_ 1415 ECU_APPL_ESC 64;
BA_ "FlexKomSID" SG_ 1415 ECU_APPL_ESC 356;
BA_ "FlexKomIsMotorola" SG_ 1415 ECU_APPL_ESC 1;
BA_ "FlexKomComment" SG_ 1415 ECU_APPL_ESC "ECU to External Application";
BA_ "GenSigSNA" SG_ 1416 ECU_APPL_ESL "0h";
BA_ "GenSigSendType" SG_ 1416 ECU_APPL_ESL 1;
BA_ "FlexKomSigStartValue" SG_ 1416 ECU_APPL_ESL "0000000000000000h";
BA_ "FlexKomSigStartPos" SG_ 1416 ECU_APPL_ESL 7;
BA_ "FlexKomSigName" SG_ 1416 ECU_APPL_ESL "ECU_APPL_ESL";
BA_ "FlexKomSigLaenge" SG_ 1416 ECU_APPL_ESL 64;
BA_ "FlexKomSID" SG_ 1416 ECU_APPL_ESL 2341;
BA_ "FlexKomIsMotorola" SG_ 1416 ECU_APPL_ESL 1;
BA_ "FlexKomComment" SG_ 1416 ECU_APPL_ESL "ECU to External Application";
BA_ "GenSigSNA" SG_ 1417 ECU_APPL_ESM "0h";
BA_ "GenSigSendType" SG_ 1417 ECU_APPL_ESM 1;
BA_ "FlexKomSigStartValue" SG_ 1417 ECU_APPL_ESM "0000000000000000h";
BA_ "FlexKomSigStartPos" SG_ 1417 ECU_APPL_ESM 7;
BA_ "FlexKomSigName" SG_ 1417 ECU_APPL_ESM "ECU_APPL_ESM";
BA_ "FlexKomSigLaenge" SG_ 1417 ECU_APPL_ESM 64;
BA_ "FlexKomSID" SG_ 1417 ECU_APPL_ESM 355;
BA_ "FlexKomIsMotorola" SG_ 1417 ECU_APPL_ESM 1;
BA_ "FlexKomComment" SG_ 1417 ECU_APPL_ESM "ECU to External Application";
BA_ "GenSigSNA" SG_ 1458 ECU_APPL_GPF "0h";
BA_ "GenSigSendType" SG_ 1458 ECU_APPL_GPF 1;
BA_ "FlexKomSigStartValue" SG_ 1458 ECU_APPL_GPF "0000000000000000h";
BA_ "FlexKomSigStartPos" SG_ 1458 ECU_APPL_GPF 7;
BA_ "FlexKomSigName" SG_ 1458 ECU_APPL_GPF "ECU_APPL_GPF";
BA_ "FlexKomSigLaenge" SG_ 1458 ECU_APPL_GPF 64;
BA_ "FlexKomSID" SG_ 1458 ECU_APPL_GPF 2828;
BA_ "FlexKomIsMotorola" SG_ 1458 ECU_APPL_GPF 1;
BA_ "FlexKomComment" SG_ 1458 ECU_APPL_GPF "ECU to External Application";
BA_ "GenSigSNA" SG_ 1466 ECU_APPL_HCP "0h";
BA_ "GenSigSendType" SG_ 1466 ECU_APPL_HCP 1;
BA_ "FlexKomSigStartValue" SG_ 1466 ECU_APPL_HCP "0000000000000000h";
BA_ "FlexKomSigStartPos" SG_ 1466 ECU_APPL_HCP 7;
BA_ "FlexKomSigName" SG_ 1466 ECU_APPL_HCP "ECU_APPL_HCP";
BA_ "FlexKomSigLaenge" SG_ 1466 ECU_APPL_HCP 64;
BA_ "FlexKomSID" SG_ 1466 ECU_APPL_HCP 2120;
BA_ "FlexKomIsMotorola" SG_ 1466 ECU_APPL_HCP 1;
BA_ "FlexKomComment" SG_ 1466 ECU_APPL_HCP "ECU to External Application";
BA_ "GenSigSNA" SG_ 1410 ECU_APPL_IC "0h";
BA_ "GenSigSendType" SG_ 1410 ECU_APPL_IC 1;
BA_ "FlexKomSigStartValue" SG_ 1410 ECU_APPL_IC "0000000000000000h";
BA_ "FlexKomSigStartPos" SG_ 1410 ECU_APPL_IC 7;
BA_ "FlexKomSigName" SG_ 1410 ECU_APPL_IC "ECU_APPL_IC";
BA_ "FlexKomSigLaenge" SG_ 1410 ECU_APPL_IC 64;
BA_ "FlexKomSID" SG_ 1410 ECU_APPL_IC 361;
BA_ "FlexKomIsMotorola" SG_ 1410 ECU_APPL_IC 1;
BA_ "FlexKomComment" SG_ 1410 ECU_APPL_IC "ECU to External Application";
BA_ "GenSigSNA" SG_ 1438 ECU_APPL_OCM "0h";
BA_ "GenSigSendType" SG_ 1438 ECU_APPL_OCM 1;
BA_ "FlexKomSigStartValue" SG_ 1438 ECU_APPL_OCM "0000000000000000h";
BA_ "FlexKomSigStartPos" SG_ 1438 ECU_APPL_OCM 7;
BA_ "FlexKomSigName" SG_ 1438 ECU_APPL_OCM "ECU_APPL_OCM";
BA_ "FlexKomSigLaenge" SG_ 1438 ECU_APPL_OCM 64;
BA_ "FlexKomSID" SG_ 1438 ECU_APPL_OCM 1540;
BA_ "FlexKomIsMotorola" SG_ 1438 ECU_APPL_OCM 1;
BA_ "FlexKomComment" SG_ 1438 ECU_APPL_OCM "ECU to External Application";
BA_ "GenSigSNA" SG_ 1412 ECU_APPL_ORC "0h";
BA_ "GenSigSendType" SG_ 1412 ECU_APPL_ORC 1;
BA_ "FlexKomSigStartValue" SG_ 1412 ECU_APPL_ORC "0000000000000000h";
BA_ "FlexKomSigStartPos" SG_ 1412 ECU_APPL_ORC 7;
BA_ "FlexKomSigName" SG_ 1412 ECU_APPL_ORC "ECU_APPL_ORC";
BA_ "FlexKomSigLaenge" SG_ 1412 ECU_APPL_ORC 64;
BA_ "FlexKomSID" SG_ 1412 ECU_APPL_ORC 368;
BA_ "FlexKomIsMotorola" SG_ 1412 ECU_APPL_ORC 1;
BA_ "FlexKomComment" SG_ 1412 ECU_APPL_ORC "ECU to External Application";
BA_ "GenSigSNA" SG_ 1442 ECU_APPL_PTS "0h";
BA_ "GenSigSendType" SG_ 1442 ECU_APPL_PTS 1;
BA_ "FlexKomSigStartValue" SG_ 1442 ECU_APPL_PTS "0000000000000000h";
BA_ "FlexKomSigStartPos" SG_ 1442 ECU_APPL_PTS 7;
BA_ "FlexKomSigName" SG_ 1442 ECU_APPL_PTS "ECU_APPL_PTS";
BA_ "FlexKomSigLaenge" SG_ 1442 ECU_APPL_PTS 64;
BA_ "FlexKomSID" SG_ 1442 ECU_APPL_PTS 376;
BA_ "FlexKomIsMotorola" SG_ 1442 ECU_APPL_PTS 1;
BA_ "FlexKomComment" SG_ 1442 ECU_APPL_PTS "ECU to External Application";
BA_ "GenSigSNA" SG_ 1408 ECU_APPL_RF_HUB "0h";
BA_ "GenSigSendType" SG_ 1408 ECU_APPL_RF_HUB 1;
BA_ "FlexKomSigStartValue" SG_ 1408 ECU_APPL_RF_HUB "0000000000000000h";
BA_ "FlexKomSigStartPos" SG_ 1408 ECU_APPL_RF_HUB 7;
BA_ "FlexKomSigName" SG_ 1408 ECU_APPL_RF_HUB "ECU_APPL_RF_HUB";
BA_ "FlexKomSigLaenge" SG_ 1408 ECU_APPL_RF_HUB 64;
BA_ "FlexKomSID" SG_ 1408 ECU_APPL_RF_HUB 358;
BA_ "FlexKomIsMotorola" SG_ 1408 ECU_APPL_RF_HUB 1;
BA_ "FlexKomComment" SG_ 1408 ECU_APPL_RF_HUB "ECU to External Application";
BA_ "GenSigSNA" SG_ 1443 ECU_APPL_SCCM "0h";
BA_ "GenSigSendType" SG_ 1443 ECU_APPL_SCCM 1;
BA_ "FlexKomSigStartValue" SG_ 1443 ECU_APPL_SCCM "0000000000000000h";
BA_ "FlexKomSigStartPos" SG_ 1443 ECU_APPL_SCCM 7;
BA_ "FlexKomSigName" SG_ 1443 ECU_APPL_SCCM "ECU_APPL_SCCM";
BA_ "FlexKomSigLaenge" SG_ 1443 ECU_APPL_SCCM 64;
BA_ "FlexKomSID" SG_ 1443 ECU_APPL_SCCM 380;
BA_ "FlexKomIsMotorola" SG_ 1443 ECU_APPL_SCCM 1;
BA_ "FlexKomComment" SG_ 1443 ECU_APPL_SCCM "ECU to External Application";
BA_ "GenSigSNA" SG_ 1515 ECU_APPL_TBM "0h";
BA_ "GenSigSendType" SG_ 1515 ECU_APPL_TBM 1;
BA_ "FlexKomSigStartValue" SG_ 1515 ECU_APPL_TBM "0000000000000000h";
BA_ "FlexKomSigStartPos" SG_ 1515 ECU_APPL_TBM 7;
BA_ "FlexKomSigName" SG_ 1515 ECU_APPL_TBM "ECU_APPL_TBM";
BA_ "FlexKomSigLaenge" SG_ 1515 ECU_APPL_TBM 64;
BA_ "FlexKomSID" SG_ 1515 ECU_APPL_TBM 2432;
BA_ "FlexKomIsMotorola" SG_ 1515 ECU_APPL_TBM 1;
BA_ "FlexKomComment" SG_ 1515 ECU_APPL_TBM "ECU to External Application";
BA_ "GenSigSNA" SG_ 1465 ECU_APPL_TCM "0h";
BA_ "GenSigSendType" SG_ 1465 ECU_APPL_TCM 1;
BA_ "FlexKomSigStartValue" SG_ 1465 ECU_APPL_TCM "0000000000000000h";
BA_ "FlexKomSigStartPos" SG_ 1465 ECU_APPL_TCM 7;
BA_ "FlexKomSigName" SG_ 1465 ECU_APPL_TCM "ECU_APPL_TCM";
BA_ "FlexKomSigLaenge" SG_ 1465 ECU_APPL_TCM 64;
BA_ "FlexKomSID" SG_ 1465 ECU_APPL_TCM 384;
BA_ "FlexKomIsMotorola" SG_ 1465 ECU_APPL_TCM 1;
BA_ "FlexKomComment" SG_ 1465 ECU_APPL_TCM "ECU to External Application";
BA_ "GenSigSNA" SG_ 1411 ECU_APPL_TPM "0h";
BA_ "GenSigSendType" SG_ 1411 ECU_APPL_TPM 1;
BA_ "FlexKomSigStartValue" SG_ 1411 ECU_APPL_TPM "0000000000000000h";
BA_ "FlexKomSigStartPos" SG_ 1411 ECU_APPL_TPM 7;
BA_ "FlexKomSigName" SG_ 1411 ECU_APPL_TPM "ECU_APPL_TPM";
BA_ "FlexKomSigLaenge" SG_ 1411 ECU_APPL_TPM 64;
BA_ "FlexKomSID" SG_ 1411 ECU_APPL_TPM 387;
BA_ "FlexKomIsMotorola" SG_ 1411 ECU_APPL_TPM 1;
BA_ "FlexKomComment" SG_ 1411 ECU_APPL_TPM "ECU to External Application";
BA_ "GenSigSNA" SG_ 993 A580_DATA "0h";
BA_ "GenSigCycleTime" SG_ 993 A580_DATA 100;
BA_ "FlexKomSigStartValue" SG_ 993 A580_DATA "1F0000h";
BA_ "FlexKomSigStartPos" SG_ 993 A580_DATA 39;
BA_ "FlexKomSigName" SG_ 993 A580_DATA "AVC_CFG";
BA_ "FlexKomSigLaenge" SG_ 993 A580_DATA 24;
BA_ "FlexKomSID" SG_ 993 A580_DATA 1090;
BA_ "FlexKomIsMotorola" SG_ 993 A580_DATA 1;
BA_ "FlexKomComment" SG_ 993 A580_DATA "TCM_EGS AVC Configuration";
BA_ "RID" SG_ 993 DISPLACEMENT "1899";
BA_ "GenSigTimeout_ORC" SG_ 993 DISPLACEMENT 350;
BA_ "GenSigTimeout_IC" SG_ 993 DISPLACEMENT 1050;
BA_ "GenSigTimeout_ETM" SG_ 993 DISPLACEMENT 1050;
BA_ "GenSigTimeout_DTCM" SG_ 993 DISPLACEMENT 1050;
BA_ "GenSigTimeout_CBC" SG_ 993 DISPLACEMENT 1050;
BA_ "GenSigStartValue" SG_ 993 DISPLACEMENT 255;
BA_ "GenSigSNA" SG_ 993 DISPLACEMENT "FFh";
BA_ "GenSigCycleTime" SG_ 993 DISPLACEMENT 100;
BA_ "FlexKomSigStartValue" SG_ 993 DISPLACEMENT "FFEFE7E7h";
BA_ "FlexKomSigStartPos" SG_ 993 DISPLACEMENT 7;
BA_ "FlexKomSigName" SG_ 993 DISPLACEMENT "ENG_CFG";
BA_ "FlexKomSigLaenge" SG_ 993 DISPLACEMENT 32;
BA_ "FlexKomSID" SG_ 993 DISPLACEMENT 617;
BA_ "FlexKomIsMotorola" SG_ 993 DISPLACEMENT 1;
BA_ "FlexKomComment" SG_ 993 DISPLACEMENT "Engine Configuration Information";
BA_ "GenSigTimeout_IC" SG_ 993 ECM_Vehi_Type 1050;
BA_ "GenSigSNA" SG_ 993 ECM_Vehi_Type "3h";
BA_ "GenSigCycleTime" SG_ 993 ECM_Vehi_Type 100;
BA_ "FlexKomSigStartValue" SG_ 993 ECM_Vehi_Type "FFEFE7E7h";
BA_ "FlexKomSigStartPos" SG_ 993 ECM_Vehi_Type 7;
BA_ "FlexKomSigName" SG_ 993 ECM_Vehi_Type "ENG_CFG";
BA_ "FlexKomSigLaenge" SG_ 993 ECM_Vehi_Type 32;
BA_ "FlexKomSID" SG_ 993 ECM_Vehi_Type 617;
BA_ "FlexKomIsMotorola" SG_ 993 ECM_Vehi_Type 1;
BA_ "FlexKomComment" SG_ 993 ECM_Vehi_Type "Engine Configuration Information";
BA_ "GenSigTimeout_ETM" SG_ 993 ENG_ASP 1050;
BA_ "GenSigStartValue" SG_ 993 ENG_ASP 7;
BA_ "GenSigSNA" SG_ 993 ENG_ASP "7h";
BA_ "GenSigCycleTime" SG_ 993 ENG_ASP 100;
BA_ "FlexKomSigStartValue" SG_ 993 ENG_ASP "FFEFE7E7h";
BA_ "FlexKomSigStartPos" SG_ 993 ENG_ASP 7;
BA_ "FlexKomSigName" SG_ 993 ENG_ASP "ENG_CFG";
BA_ "FlexKomSigLaenge" SG_ 993 ENG_ASP 32;
BA_ "FlexKomSID" SG_ 993 ENG_ASP 617;
BA_ "FlexKomIsMotorola" SG_ 993 ENG_ASP 1;
BA_ "FlexKomComment" SG_ 993 ENG_ASP "Engine Configuration Information";
BA_ "GenSigTimeout_IC" SG_ 993 ETC_PRSNT 1050;
BA_ "GenSigSNA" SG_ 993 ETC_PRSNT "0h";
BA_ "GenSigCycleTime" SG_ 993 ETC_PRSNT 100;
BA_ "FlexKomSigStartValue" SG_ 993 ETC_PRSNT "FFEFE7E7h";
BA_ "FlexKomSigStartPos" SG_ 993 ETC_PRSNT 7;
BA_ "FlexKomSigName" SG_ 993 ETC_PRSNT "ENG_CFG";
BA_ "FlexKomSigLaenge" SG_ 993 ETC_PRSNT 32;
BA_ "FlexKomSID" SG_ 993 ETC_PRSNT 617;
BA_ "FlexKomIsMotorola" SG_ 993 ETC_PRSNT 1;
BA_ "FlexKomComment" SG_ 993 ETC_PRSNT "Engine Configuration Information";
BA_ "RID" SG_ 993 EngStyle "1062";
BA_ "GenSigTimeout_CBC" SG_ 993 EngStyle 1050;
BA_ "GenSigStartValue" SG_ 993 EngStyle 7;
BA_ "GenSigSNA" SG_ 993 EngStyle "7h";
BA_ "GenSigCycleTime" SG_ 993 EngStyle 100;
BA_ "FlexKomSigStartValue" SG_ 993 EngStyle "FFEFE7E7h";
BA_ "FlexKomSigStartPos" SG_ 993 EngStyle 7;
BA_ "FlexKomSigName" SG_ 993 EngStyle "ENG_CFG";
BA_ "FlexKomSigLaenge" SG_ 993 EngStyle 32;
BA_ "FlexKomSID" SG_ 993 EngStyle 617;
BA_ "FlexKomIsMotorola" SG_ 993 EngStyle 1;
BA_ "FlexKomComment" SG_ 993 EngStyle "Engine Configuration Information";
BA_ "RID" SG_ 993 FUEL_TYPE "1261";
BA_ "GenSigTimeout_ORC" SG_ 993 FUEL_TYPE 350;
BA_ "GenSigTimeout_IC" SG_ 993 FUEL_TYPE 1050;
BA_ "GenSigTimeout_EHPS" SG_ 993 FUEL_TYPE 1050;
BA_ "GenSigTimeout_CBC" SG_ 993 FUEL_TYPE 1050;
BA_ "GenSigStartValue" SG_ 993 FUEL_TYPE 7;
BA_ "GenSigSNA" SG_ 993 FUEL_TYPE "7h";
BA_ "GenSigCycleTime" SG_ 993 FUEL_TYPE 100;
BA_ "FlexKomSigStartValue" SG_ 993 FUEL_TYPE "FFEFE7E7h";
BA_ "FlexKomSigStartPos" SG_ 993 FUEL_TYPE 7;
BA_ "FlexKomSigName" SG_ 993 FUEL_TYPE "ENG_CFG";
BA_ "FlexKomSigLaenge" SG_ 993 FUEL_TYPE 32;
BA_ "FlexKomSID" SG_ 993 FUEL_TYPE 617;
BA_ "FlexKomIsMotorola" SG_ 993 FUEL_TYPE 1;
BA_ "FlexKomComment" SG_ 993 FUEL_TYPE "Engine Configuration Information";
BA_ "GenSigStartValue" SG_ 993 Manufacture 7;
BA_ "GenSigSNA" SG_ 993 Manufacture "7h";
BA_ "GenSigCycleTime" SG_ 993 Manufacture 100;
BA_ "FlexKomSigStartValue" SG_ 993 Manufacture "FFEFE7E7h";
BA_ "FlexKomSigStartPos" SG_ 993 Manufacture 7;
BA_ "FlexKomSigName" SG_ 993 Manufacture "ENG_CFG";
BA_ "FlexKomSigLaenge" SG_ 993 Manufacture 32;
BA_ "FlexKomSID" SG_ 993 Manufacture 617;
BA_ "FlexKomIsMotorola" SG_ 993 Manufacture 1;
BA_ "FlexKomComment" SG_ 993 Manufacture "Engine Configuration Information";
BA_ "GenSigStartValue" SG_ 993 NUM_CYL 15;
BA_ "GenSigSNA" SG_ 993 NUM_CYL "Fh";
BA_ "GenSigCycleTime" SG_ 993 NUM_CYL 100;
BA_ "FlexKomSigStartValue" SG_ 993 NUM_CYL "FFEFE7E7h";
BA_ "FlexKomSigStartPos" SG_ 993 NUM_CYL 7;
BA_ "FlexKomSigName" SG_ 993 NUM_CYL "ENG_CFG";
BA_ "FlexKomSigLaenge" SG_ 993 NUM_CYL 32;
BA_ "FlexKomSID" SG_ 993 NUM_CYL 617;
BA_ "FlexKomIsMotorola" SG_ 993 NUM_CYL 1;
BA_ "FlexKomComment" SG_ 993 NUM_CYL "Engine Configuration Information";
BA_ "GenSigStartValue" SG_ 993 NUM_VALVE 7;
BA_ "GenSigSNA" SG_ 993 NUM_VALVE "7h";
BA_ "GenSigCycleTime" SG_ 993 NUM_VALVE 100;
BA_ "FlexKomSigStartValue" SG_ 993 NUM_VALVE "FFEFE7E7h";
BA_ "FlexKomSigStartPos" SG_ 993 NUM_VALVE 7;
BA_ "FlexKomSigName" SG_ 993 NUM_VALVE "ENG_CFG";
BA_ "FlexKomSigLaenge" SG_ 993 NUM_VALVE 32;
BA_ "FlexKomSID" SG_ 993 NUM_VALVE 617;
BA_ "FlexKomIsMotorola" SG_ 993 NUM_VALVE 1;
BA_ "FlexKomComment" SG_ 993 NUM_VALVE "Engine Configuration Information";
BA_ "RID" SG_ 993 SpStPrsnt "1164";
BA_ "GenSigTimeout_ORC" SG_ 993 SpStPrsnt 350;
BA_ "GenSigTimeout_IC" SG_ 993 SpStPrsnt 1050;
BA_ "GenSigSNA" SG_ 993 SpStPrsnt "0h";
BA_ "GenSigCycleTime" SG_ 993 SpStPrsnt 100;
BA_ "FlexKomSigStartValue" SG_ 993 SpStPrsnt "FFEFE7E7h";
BA_ "FlexKomSigStartPos" SG_ 993 SpStPrsnt 7;
BA_ "FlexKomSigName" SG_ 993 SpStPrsnt "ENG_CFG";
BA_ "FlexKomSigLaenge" SG_ 993 SpStPrsnt 32;
BA_ "FlexKomSID" SG_ 993 SpStPrsnt 617;
BA_ "FlexKomIsMotorola" SG_ 993 SpStPrsnt 1;
BA_ "FlexKomComment" SG_ 993 SpStPrsnt "Engine Configuration Information";
BA_ "RID" SG_ 993 TRANS_TYPE "1094";
BA_ "GenSigTimeout_TPM" SG_ 993 TRANS_TYPE 1050;
BA_ "GenSigTimeout_ORC" SG_ 993 TRANS_TYPE 350;
BA_ "GenSigTimeout_IC" SG_ 993 TRANS_TYPE 1050;
BA_ "GenSigSNA" SG_ 993 TRANS_TYPE "0h";
BA_ "GenSigCycleTime" SG_ 993 TRANS_TYPE 100;
BA_ "FlexKomSigStartValue" SG_ 993 TRANS_TYPE "FFEFE7E7h";
BA_ "FlexKomSigStartPos" SG_ 993 TRANS_TYPE 7;
BA_ "FlexKomSigName" SG_ 993 TRANS_TYPE "ENG_CFG";
BA_ "FlexKomSigLaenge" SG_ 993 TRANS_TYPE 32;
BA_ "FlexKomSID" SG_ 993 TRANS_TYPE 617;
BA_ "FlexKomIsMotorola" SG_ 993 TRANS_TYPE 1;
BA_ "FlexKomComment" SG_ 993 TRANS_TYPE "Engine Configuration Information";
BA_ "GenSigTimeout_ORC" SG_ 296 EPS_AsstStat 350;
BA_ "GenSigTimeout_IC" SG_ 296 EPS_AsstStat 1050;
BA_ "GenSigStartValue" SG_ 296 EPS_AsstStat 1;
BA_ "GenSigSNA" SG_ 296 EPS_AsstStat "7h";
BA_ "GenSigCycleTime" SG_ 296 EPS_AsstStat 100;
BA_ "FlexKomSigStartValue" SG_ 296 EPS_AsstStat "0200FF0000000000h";
BA_ "FlexKomSigStartPos" SG_ 296 EPS_AsstStat 7;
BA_ "FlexKomSigName" SG_ 296 EPS_AsstStat "EPS_A1_PKT";
BA_ "FlexKomSigLaenge" SG_ 296 EPS_AsstStat 64;
BA_ "FlexKomSID" SG_ 296 EPS_AsstStat 846;
BA_ "FlexKomIsMotorola" SG_ 296 EPS_AsstStat 1;
BA_ "FlexKomComment" SG_ 296 EPS_AsstStat "EPS_A1_PKT";
BA_ "GenSigStartValue" SG_ 296 EPS_Curr 255;
BA_ "GenSigSNA" SG_ 296 EPS_Curr "FFh";
BA_ "GenSigCycleTime" SG_ 296 EPS_Curr 100;
BA_ "FlexKomSigStartValue" SG_ 296 EPS_Curr "0200FF0000000000h";
BA_ "FlexKomSigStartPos" SG_ 296 EPS_Curr 7;
BA_ "FlexKomSigName" SG_ 296 EPS_Curr "EPS_A1_PKT";
BA_ "FlexKomSigLaenge" SG_ 296 EPS_Curr 64;
BA_ "FlexKomSID" SG_ 296 EPS_Curr 846;
BA_ "FlexKomIsMotorola" SG_ 296 EPS_Curr 1;
BA_ "FlexKomComment" SG_ 296 EPS_Curr "EPS_A1_PKT";
BA_ "RID" SG_ 296 EPS_Warn_Disp_Rq "1995";
BA_ "GenSigTimeout_ORC" SG_ 296 EPS_Warn_Disp_Rq 350;
BA_ "GenSigTimeout_IC" SG_ 296 EPS_Warn_Disp_Rq 1050;
BA_ "GenSigTimeout_CBC" SG_ 296 EPS_Warn_Disp_Rq 1050;
BA_ "GenSigSNA" SG_ 296 EPS_Warn_Disp_Rq "7h";
BA_ "GenSigCycleTime" SG_ 296 EPS_Warn_Disp_Rq 100;
BA_ "FlexKomSigStartValue" SG_ 296 EPS_Warn_Disp_Rq "0200FF0000000000h";
BA_ "FlexKomSigStartPos" SG_ 296 EPS_Warn_Disp_Rq 7;
BA_ "FlexKomSigName" SG_ 296 EPS_Warn_Disp_Rq "EPS_A1_PKT";
BA_ "FlexKomSigLaenge" SG_ 296 EPS_Warn_Disp_Rq 64;
BA_ "FlexKomSID" SG_ 296 EPS_Warn_Disp_Rq 846;
BA_ "FlexKomIsMotorola" SG_ 296 EPS_Warn_Disp_Rq 1;
BA_ "FlexKomComment" SG_ 296 EPS_Warn_Disp_Rq "EPS_A1_PKT";
BA_ "GenSigSNA" SG_ 296 EngineFanRequestActivation "0h";
BA_ "GenSigCycleTime" SG_ 296 EngineFanRequestActivation 100;
BA_ "FlexKomSigStartValue" SG_ 296 EngineFanRequestActivation "0200FF0000000000h";
BA_ "FlexKomSigStartPos" SG_ 296 EngineFanRequestActivation 7;
BA_ "FlexKomSigName" SG_ 296 EngineFanRequestActivation "EPS_A1_PKT";
BA_ "FlexKomSigLaenge" SG_ 296 EngineFanRequestActivation 64;
BA_ "FlexKomSID" SG_ 296 EngineFanRequestActivation 846;
BA_ "FlexKomIsMotorola" SG_ 296 EngineFanRequestActivation 1;
BA_ "FlexKomComment" SG_ 296 EngineFanRequestActivation "EPS_A1_PKT";
BA_ "RID" SG_ 296 PS_SysType "1993";
BA_ "GenSigTimeout_IC" SG_ 296 PS_SysType 1050;
BA_ "GenSigSNA" SG_ 296 PS_SysType "0h";
BA_ "GenSigCycleTime" SG_ 296 PS_SysType 100;
BA_ "FlexKomSigStartValue" SG_ 296 PS_SysType "0200FF0000000000h";
BA_ "FlexKomSigStartPos" SG_ 296 PS_SysType 7;
BA_ "FlexKomSigName" SG_ 296 PS_SysType "EPS_A1_PKT";
BA_ "FlexKomSigLaenge" SG_ 296 PS_SysType 64;
BA_ "FlexKomSID" SG_ 296 PS_SysType 846;
BA_ "FlexKomIsMotorola" SG_ 296 PS_SysType 1;
BA_ "FlexKomComment" SG_ 296 PS_SysType "EPS_A1_PKT";
BA_ "GenSigSNA" SG_ 463 CodeCheckStsESL "0h";
BA_ "GenSigSendType" SG_ 463 CodeCheckStsESL 1;
BA_ "FlexKomSigStartValue" SG_ 463 CodeCheckStsESL "0000000000h";
BA_ "FlexKomSigStartPos" SG_ 463 CodeCheckStsESL 7;
BA_ "FlexKomSigName" SG_ 463 CodeCheckStsESL "ESL_CodeRespPkt";
BA_ "FlexKomSigLaenge" SG_ 463 CodeCheckStsESL 40;
BA_ "FlexKomSID" SG_ 463 CodeCheckStsESL 2367;
BA_ "FlexKomIsMotorola" SG_ 463 CodeCheckStsESL 1;
BA_ "FlexKomComment" SG_ 463 CodeCheckStsESL "ESL code response packet";
BA_ "GenSigSNA" SG_ 463 ControlEncodingRspESL "0h";
BA_ "GenSigSendType" SG_ 463 ControlEncodingRspESL 1;
BA_ "FlexKomSigStartValue" SG_ 463 ControlEncodingRspESL "0000000000h";
BA_ "FlexKomSigStartPos" SG_ 463 ControlEncodingRspESL 7;
BA_ "FlexKomSigName" SG_ 463 ControlEncodingRspESL "ESL_CodeRespPkt";
BA_ "FlexKomSigLaenge" SG_ 463 ControlEncodingRspESL 40;
BA_ "FlexKomSID" SG_ 463 ControlEncodingRspESL 2367;
BA_ "FlexKomIsMotorola" SG_ 463 ControlEncodingRspESL 1;
BA_ "FlexKomComment" SG_ 463 ControlEncodingRspESL "ESL code response packet";
BA_ "GenSigSNA" SG_ 463 ESLFeedbackCmd "7h";
BA_ "GenSigSendType" SG_ 463 ESLFeedbackCmd 1;
BA_ "FlexKomSigStartValue" SG_ 463 ESLFeedbackCmd "0000000000h";
BA_ "FlexKomSigStartPos" SG_ 463 ESLFeedbackCmd 7;
BA_ "FlexKomSigName" SG_ 463 ESLFeedbackCmd "ESL_CodeRespPkt";
BA_ "FlexKomSigLaenge" SG_ 463 ESLFeedbackCmd 40;
BA_ "FlexKomSID" SG_ 463 ESLFeedbackCmd 2367;
BA_ "FlexKomIsMotorola" SG_ 463 ESLFeedbackCmd 1;
BA_ "FlexKomComment" SG_ 463 ESLFeedbackCmd "ESL code response packet";
BA_ "GenSigSNA" SG_ 463 ESLLockFailSts "0h";
BA_ "GenSigSendType" SG_ 463 ESLLockFailSts 1;
BA_ "FlexKomSigStartValue" SG_ 463 ESLLockFailSts "0000000000h";
BA_ "FlexKomSigStartPos" SG_ 463 ESLLockFailSts 7;
BA_ "FlexKomSigName" SG_ 463 ESLLockFailSts "ESL_CodeRespPkt";
BA_ "FlexKomSigLaenge" SG_ 463 ESLLockFailSts 40;
BA_ "FlexKomSID" SG_ 463 ESLLockFailSts 2367;
BA_ "FlexKomIsMotorola" SG_ 463 ESLLockFailSts 1;
BA_ "FlexKomComment" SG_ 463 ESLLockFailSts "ESL code response packet";
BA_ "GenSigSNA" SG_ 463 ESLUnlockFailSts "0h";
BA_ "GenSigSendType" SG_ 463 ESLUnlockFailSts 1;
BA_ "FlexKomSigStartValue" SG_ 463 ESLUnlockFailSts "0000000000h";
BA_ "FlexKomSigStartPos" SG_ 463 ESLUnlockFailSts 7;
BA_ "FlexKomSigName" SG_ 463 ESLUnlockFailSts "ESL_CodeRespPkt";
BA_ "FlexKomSigLaenge" SG_ 463 ESLUnlockFailSts 40;
BA_ "FlexKomSID" SG_ 463 ESLUnlockFailSts 2367;
BA_ "FlexKomIsMotorola" SG_ 463 ESLUnlockFailSts 1;
BA_ "FlexKomComment" SG_ 463 ESLUnlockFailSts "ESL code response packet";
BA_ "GenSigSNA" SG_ 463 ESL_ProgrammedSts "0h";
BA_ "GenSigSendType" SG_ 463 ESL_ProgrammedSts 1;
BA_ "FlexKomSigStartValue" SG_ 463 ESL_ProgrammedSts "0000000000h";
BA_ "FlexKomSigStartPos" SG_ 463 ESL_ProgrammedSts 7;
BA_ "FlexKomSigName" SG_ 463 ESL_ProgrammedSts "ESL_CodeRespPkt";
BA_ "FlexKomSigLaenge" SG_ 463 ESL_ProgrammedSts 40;
BA_ "FlexKomSID" SG_ 463 ESL_ProgrammedSts 2367;
BA_ "FlexKomIsMotorola" SG_ 463 ESL_ProgrammedSts 1;
BA_ "FlexKomComment" SG_ 463 ESL_ProgrammedSts "ESL code response packet";
BA_ "GenSigSNA" SG_ 463 MiniCryptGCodeESL "0h";
BA_ "GenSigSendType" SG_ 463 MiniCryptGCodeESL 1;
BA_ "FlexKomSigStartValue" SG_ 463 MiniCryptGCodeESL "0000000000h";
BA_ "FlexKomSigStartPos" SG_ 463 MiniCryptGCodeESL 7;
BA_ "FlexKomSigName" SG_ 463 MiniCryptGCodeESL "ESL_CodeRespPkt";
BA_ "FlexKomSigLaenge" SG_ 463 MiniCryptGCodeESL 40;
BA_ "FlexKomSID" SG_ 463 MiniCryptGCodeESL 2367;
BA_ "FlexKomIsMotorola" SG_ 463 MiniCryptGCodeESL 1;
BA_ "FlexKomComment" SG_ 463 MiniCryptGCodeESL "ESL code response packet";
VAL_ 123 AccelPdlPosn 255 "SNA" ;
VAL_ 123 EngTrqSel_D_TTC 8191 "SNA" ;
VAL_ 123 EngTrq_DrvReqMod 8191 "SNA" ;
VAL_ 124 AccelPdlPosn_PHEV 255 "SNA" ;
VAL_ 124 ECM_Comm_Fail_ePT 0 "No_Fault" 1 "ECM_LoC_ePT_TCM" 2 "ECM_LoC_ePT_HCP" 3 "ECM_LoC_ePT_HCP_TCM" 7 "ECM_Bus_Failure_ePT" ;
VAL_ 124 EngTrqTgt_SEM_PHEV 8191 "SNA" ;
VAL_ 53 ESS_ENG_ST 1 "ENS_STOPPED" 2 "ENS_RQ_ST" 3 "ENS_RUN" 4 "ENS_STOP_PEND" 5 "ENS_ST_PRTCT" 6 "ENS_ST_INH" 7 "ENS_DSBL" 8 "ENS_IHB_LATCH" 9 "ENS_STARTING" 10 "KEY_START" 11 "ENS_CHANGE_MIND" 15 "SNA" ;
VAL_ 53 EngMaxRPM 255 "SNA" ;
VAL_ 53 EngRdyForESS 0 "SNA" ;
VAL_ 53 EngStallSts 0 "NOT_STALL" 1 "STALL" 3 "SNA" ;
VAL_ 53 EngTrqStatic_SEM 8191 "SNA" ;
VAL_ 53 EngTrqTgt_SEM 8191 "SNA" ;
VAL_ 53 TRANS_CLU_SLIP_MODE 0 "NORMAL" 1 "MDS_RQ" 2 "IDFSO_RQ" 3 "AC_EN_DIS_RQ" 4 "IDFSO_ACTIVE" 5 "MDS_IDFSO_ACT" 7 "SNA" ;
VAL_ 976 KNK_MG_TRIGGER 0 "LSPI_NO_MESSAGE" 1 "LSPI_LEVEL_1" 2 "LSPI_LEVEL_2" 3 "LSPI_LEVEL_3" ;
VAL_ 976 PF_WARN_MSG 0 "PF_WARN" 1 "PF_WARN_REG_REQ" 2 "PF_WARN_REG_STRT" 3 "PF_WARN_REG_CMPT" 4 "PF_WARN_REG_SERV" 5 "PF_WARN_REG_PW_RED" 6 "PF_WARN_6" 7 "PF_WARN_7" ;
VAL_ 157 ActlAccelPdlPosn 255 "SNA" ;
VAL_ 157 Analog_Clutch 255 "SNA" ;
VAL_ 819 ExhaustSwStat 0 "OFF" 1 "CONT" 2 "BLINK" 3 "SNA" ;
VAL_ 676 ECM_WARN_EXT 0 "NONE" 1 "WARN_EXT_1" 2 "WARN_EXT_2" 3 "WARN_EXT_3" 4 "WARN_EXT_4" 5 "WARN_EXT_5" 6 "WARN_EXT_6" 7 "WARN_EXT_7" 8 "WARN_EXT_8" 9 "WARN_EXT_9" 10 "WARN_EXT_10" 12 "WARN_EXT_12" 13 "WARN_EXT_13" 14 "WARN_EXT_14" 15 "WARN_EXT_15" 16 "WARN_EXT_16" 17 "WARN_EXT_17" 18 "WARN_EXT_18" 19 "WARN_EXT_19" 20 "WARN_EXT_20" 21 "WARN_EXT_21" 22 "WARN_EXT_22" 23 "WARN_EXT_23" 24 "WARN_EXT_24" 25 "WARN_EXT_25" ;
VAL_ 676 MAP_4_Bar 511 "SNA" ;
VAL_ 676 TransWarmup_Min_RPM 255 "SNA" ;
VAL_ 311 CC_SetSpdDspl 255 "SNA" ;
VAL_ 311 CC_SetSpdDsplMPH 255 "SNA" ;
VAL_ 311 CoolVlvPos 0 "OPEN" 254 "CLOSED" 255 "SNA" ;
VAL_ 311 EVPmpStat 0 "OFF" 1 "ON" 2 "FAULT" 3 "SNA" ;
VAL_ 311 EconShftRq 0 "NONE" 1 "UP" 2 "DOWN" 3 "SNA" ;
VAL_ 311 SpStDispstat 0 "NONE" 1 "STARTING" 2 "START" 3 "ACTIVE" 4 "D_OR_SB" 5 "NR_DRV_NOT_DET" 6 "DR_INHIB" 7 "TX_INHIB" 8 "KEY" 9 "BATT" 10 "SYSFLT" 11 "NR" 12 "READY" 13 "OFF" 14 "HOOD" 15 "PEDAL" 16 "BATT_CHG" 17 "TM" 18 "T4WD_L" 19 "LF" 20 "INCLINE" 21 "AMB_TEMP" 22 "ENG_TEMP" 23 "SB" 24 "DR_AJAR" 25 "CABIN" 26 "MAX_HVAC" 27 "FT_DEFROST" 28 "EBL" 29 "ST_WHEEL" 30 "Eng_Temp_Hi" 31 "Eng_Temp_Lo" 32 "Prk_Brk_Inhib" 33 "Park_Inhib" 34 "Hood_Inhib" 35 "DPF_Regen" 36 "PSG_DR_INHIB" 37 "ACC_SET" 38 "BATT_HIGH" 39 "OFF_ROAD1" 40 "OFF_ROAD2" 63 "SNA" ;
VAL_ 311 SpStSwStat 0 "OFF" 1 "CONT" 2 "BLINK" 3 "SNA" ;
VAL_ 311 SpStWarnStat 0 "NONE" 1 "PCR_Opens" 2 "START" 3 "ACTIVE" 4 "D_OR_SB" 5 "NR_DRV_NOT_DET" 6 "DR_INHIB" 7 "TX_INHIB" 8 "KEY" 9 "BATT" 10 "SYSFLT" 11 "Prk_Brk_Inhib" 12 "Hood_Inhib" 13 "PSG_DR_INHIB" 14 "Park_Inhib" 15 "SNA" ;
VAL_ 295 AM_ECM_Prsnt 0 "DEFAULT" 2 "AM_ECM_PRSNT" 3 "SNA" ;
VAL_ 295 AirPress_Outsd 255 "SNA" ;
VAL_ 295 CHRG_FAIL 1 "SNA" ;
VAL_ 295 EngCoolTemp 255 "SNA" ;
VAL_ 295 IntkAirTemp 255 "SNA" ;
VAL_ 295 R134a_Press_Stat 511 "SNA" ;
VAL_ 295 SysVolt 255 "SNA" ;
VAL_ 633 DisOilLifeRst 65535 "SNA" ;
VAL_ 633 FuelMM_Sts 0 "INACTIVE" 1 "ACTIVE" 2 "DISABLED" ;
VAL_ 633 HoursOilLifeRst 4095 "SNA" ;
VAL_ 633 MntncSts 0 "NONE" 1 "SOON" 2 "NOW" 3 "SNA" ;
VAL_ 633 OilLifeLeft 255 "SNA" ;
VAL_ 347 RevOilLifeRst 65535 "SNA" ;
VAL_ 343 LeakCheckTimerValue 511 "SNA" ;
VAL_ 343 LeakTestSts 0 "NONE" 1 "PEND" 2 "COMPLETE" 3 "DELAY" ;
VAL_ 343 RefuelEvent 0 "NONE" 1 "PEND" 2 "TRUE" 3 "COMP" 4 "FAULT" ;
VAL_ 343 RefuelIndication 0 "NONE" 1 "WAIT" 2 "PARK" 3 "OK" 4 "DOOR" 5 "BLOCKAGE" 6 "SERVICE" ;
VAL_ 343 SAMInfo 0 "SAMOFF" 1 "Engine_OFF" 2 "Cranking_management" 3 "ColdEngineManagement" 4 "PassiveBoost" 5 "Steady_State" 6 "RegenerativeBraking" 7 "QuickCharge" 8 "Auto_Shut_OFF" 9 "Shut_OFF" 10 "SAM_recovery" 11 "Battery_Regeneration" 15 "SNA" ;
VAL_ 343 StartProtectionInhibit 0 "Default" 2 "Crank_Inhibit" 3 "SNA" ;
VAL_ 343 StarterProtectionTime 255 "SNA" ;
VAL_ 129 BARO_ENG 255 "SNA" ;
VAL_ 129 CRUISE_EGD 0 "SNA" ;
VAL_ 129 CRUISE_ON 0 "SNA" ;
VAL_ 129 ECM_WARN 0 "None" 1 "WARN_1" 2 "WARN_2" 3 "WARN_3" 4 "WARN_4" 5 "WARN_5" 6 "WARN_6" 7 "SNA" ;
VAL_ 129 MAP_ENG 255 "SNA" ;
VAL_ 129 Rel_Pdl_ENG 255 "SNA" ;
VAL_ 129 Rel_Thrt_ENG 255 "SNA" ;
VAL_ 129 SpeedLimitSts 0 "S_B" 1 "ACT" 2 "N_A" 3 "OVER" 4 "OVER_SPEED" 5 "DEACTIVATED" 6 "OFF" 7 "SNA" ;
VAL_ 129 V_MAX_TM 255 "SNA" ;
VAL_ 301 AdblueRemainDist 65535 "SNA" ;
VAL_ 301 Adblue_FL_LVL 255 "SNA" ;
VAL_ 301 Adblue_Stat 0 "OK" 1 "DEFLW1" 2 "DEFLW2" 3 "DEFLW3" 4 "DEFLW4" 5 "DEFLW5" 6 "DEFLW6" 7 "DEFLW7" 8 "DEFLW8" 9 "DEFLW9" 10 "DEFLW10" 11 "DEFLW11" 12 "DEFLW12" 13 "DEFLW13" 14 "DEFLW14" 15 "DEFLW15" 16 "DEFQW1" 17 "DEFQW2" 18 "DEFQW3" 19 "DEFQW4" 20 "DEFQW5" 21 "DEFQW6" 22 "DEFQW7" 23 "DEFQW8" 24 "DEFQW9" 25 "DEFQW10" 33 "DEFLW1_RL" 34 "DEFLW2_RL" 35 "DEFLW3_RL" 36 "DEFLW4_RL" 37 "DEFLW5_RL" 38 "DEFLW6_RL" 39 "DEFLW7_RL" 40 "DEFLW8_RL" 41 "DEFLW9_RL" 42 "DEFLW10_RL" 43 "DEFLW11_RL" 44 "DEFLW12_RL" 45 "DEFLW13_RL" 46 "DEFLW14_RL" 47 "DEFLW15_RL" 48 "DEFQW1_RL" 49 "DEFQW2_RL" 50 "DEFQW3_RL" 51 "DEFQW4_RL" 52 "DEFQW5_RL" 53 "DEFQW6_RL" 54 "DEFQW7_RL" 55 "DEFQW8_RL" 56 "DEFQW9_RL" 57 "DEFQW10_RL" 63 "SNA" ;
VAL_ 301 DEF_LOW 0 "OFF" 1 "CONT" 2 "BLINK" 3 "SNA" ;
VAL_ 301 ECM_HMI_Timer_RQ 0 "TMR120" 1 "TMR60" 2 "TMR30" 7 "SNA" ;
VAL_ 301 PFW_Stat 0 "PFW_MN" 1 "RegRqPFW_Stat" 2 "SerRqPFW_Stat" 3 "SER_REQ" 4 "REG_CMPL" 5 "RegActPFW_Stat" 6 "PWR_RED" 9 "RegRqPFW_StatRL" 10 "SerRqPFW_StatRL" 11 "SER_REQ_RL" 12 "REG_CMPL_RL" 13 "RegActPFW_StatRL" 14 "PWR_RED_RL" 15 "SNA" ;
VAL_ 301 PF_RgnActv 0 "SNA" ;
VAL_ 301 PrcntCplt 15 "SNA" ;
VAL_ 301 PreHtIndLmp_On_Rq 0 "SNA" ;
VAL_ 301 PreHtlmpwithEVIC_On_Rq 0 "DEFAULT" 1 "LMP_SOLID" 2 "LMP_FLASH" 3 "SNA" ;
VAL_ 301 WtrFuelIndLmp_On_Rq 0 "SNA" ;
VAL_ 337 TrboBstPress 255 "SNA" ;
VAL_ 39 EngTrqMax 8191 "SNA" ;
VAL_ 39 EngTrqMin 8191 "SNA" ;
VAL_ 39 StartRelayBCMCmd 0 "SNA" ;
VAL_ 181 EngRPM_Tach 65535 "SNA" ;
VAL_ 181 EngineStaticTorque 4095 "SNA" ;
VAL_ 181 EngineStaticTorqueV 0 "Valid" 1 "Not_Valid" ;
VAL_ 125 EngTrqMaxCorrFctr 255 "SNA" ;
VAL_ 125 GrMax_Rq_ECM 0 "PASSIVE" 1 "G1" 2 "G2" 3 "G3" 4 "G4" 5 "G5" 6 "G6" 7 "G7" ;
VAL_ 125 GrMin_Rq_ECM 0 "PASSIVE" 1 "G1" 2 "G2" 3 "G3" 4 "G4" 5 "G5" 6 "G6" 7 "G7" ;
VAL_ 125 NMOTS 65535 "SNA" ;
VAL_ 317 DefFuelEcon 255 "SNA" ;
VAL_ 317 ETC_IND_LMP 0 "OFF" 1 "ON" 2 "ON_Flashing" 3 "SNA" ;
VAL_ 317 EngOilIndLmp_On_Rq 1 "SNA" ;
VAL_ 317 EngOilTemp 255 "SNA" ;
VAL_ 317 EngRun_Stat 0 "STOP" 1 "START" 2 "IDLE_UNSTBL" 3 "IDLE_STBL" 4 "UNLIMITED" 5 "LIMITED" 6 "NDEF6" 7 "SNA" ;
VAL_ 317 FuelCons 65535 "SNA" ;
VAL_ 317 OIL_PRESS 255 "SNA" ;
VAL_ 317 OIL_TEMP_CHM_RQ 0 "NO_CHM" 1 "1_CHM" 2 "SLOW_CHM" 3 "FAST_CHM" ;
VAL_ 317 OIL_TEMP_IND_RQ 0 "IND_LMP_OFF" 1 "IND_LMP_ON" 2 "IND_LMP_FLASH" 3 "SNA" ;
VAL_ 289 RAD_FAN1_STAT 255 "SNA" ;
VAL_ 993 DISPLACEMENT 255 "SNA" ;
VAL_ 993 ECM_Vehi_Type 0 "STANDARD" 1 "EVEHICLE" 3 "SNA" ;
VAL_ 993 ENG_ASP 0 "INTAKE_NORM" 1 "TURBO1" 2 "TURBO2" 3 "SUPER" 7 "SNA" ;
VAL_ 993 EngStyle 0 "CHOICE1" 1 "CHOICE2" 2 "CHOICE3" 3 "CHOICE4" 4 "CHOICE5" 5 "CHOICE6" 7 "SNA" ;
VAL_ 993 FUEL_TYPE 0 "UNLEADED" 1 "DIESEL" 2 "FLEX" 3 "CNG" 7 "SNA" ;
VAL_ 993 Manufacture 0 "ENG_DCA" 1 "ENG_DCS" 2 "ENG_MMC" 3 "ENG_HY" 7 "ENG_NP" ;
VAL_ 993 NUM_CYL 15 "SNA" ;
VAL_ 993 NUM_VALVE 7 "SNA" ;
VAL_ 296 EPS_AsstStat 0 "AST_ACT" 1 "AST_OFF" 2 "AST_RT" 7 "SNA" ;
VAL_ 296 EPS_Curr 255 "SNA" ;
VAL_ 296 EPS_Warn_Disp_Rq 0 "OK" 1 "ERR" 2 "ERR2" 3 "SERV_HI" 7 "SNA" ;
VAL_ 463 CodeCheckStsESL 0 "No_Code" 1 "CodeCheck_OK" 2 "CodeCheck_Fault" ;
VAL_ 463 ESLFeedbackCmd 0 "Undefined_Position" 3 "Lock" 5 "Unlock" 7 "SNA" ;
